VERSION ""

NS_ :

BS_:

BU_: APIM_CISM FCIMB RACM_RCIM DSP WCM DACMC HUD_ADV TRM_ITRM ACM GWM _delete APIM IPC GENERIC TSTR

BO_ 1931 TesterPhysicalResDSP: 8 DSP
 SG_ TesterPhysicalResDSP : 7|64@0+ (1,0) [0|1.84467E+019] "unitless"  TSTR

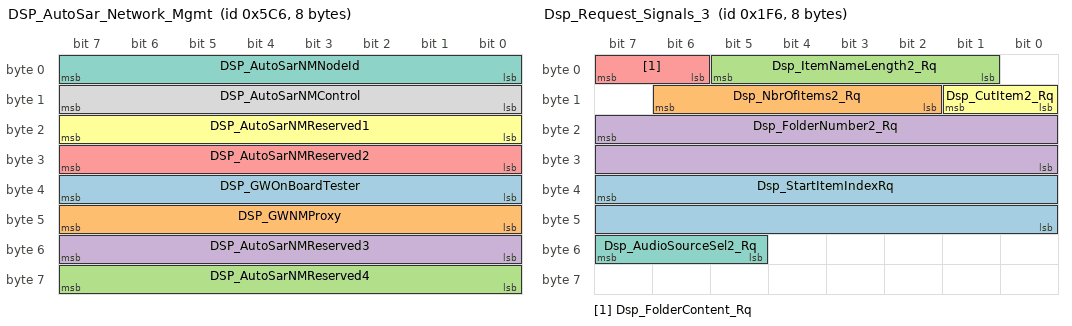
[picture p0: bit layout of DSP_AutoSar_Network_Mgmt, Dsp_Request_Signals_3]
BO_ 1478 DSP_AutoSar_Network_Mgmt: 8 DSP
 SG_ DSP_GWOnBoardTester : 39|8@0+ (1,0) [0|255] "unitless"  HUD_ADV
 SG_ DSP_GWNMProxy : 47|8@0+ (1,0) [0|255] "unitless"  HUD_ADV
 SG_ DSP_AutoSarNMReserved4 : 63|8@0+ (1,0) [0|255] "unitless"  HUD_ADV
 SG_ DSP_AutoSarNMReserved3 : 55|8@0+ (1,0) [0|255] "unitless"  HUD_ADV
 SG_ DSP_AutoSarNMReserved2 : 31|8@0+ (1,0) [0|255] "unitless"  HUD_ADV
 SG_ DSP_AutoSarNMReserved1 : 23|8@0+ (1,0) [0|255] "unitless"  HUD_ADV
 SG_ DSP_AutoSarNMNodeId : 7|8@0+ (1,0) [0|255] "unitless"  HUD_ADV
 SG_ DSP_AutoSarNMControl : 15|8@0+ (1,0) [0|255] "unitless"  HUD_ADV

BO_ 502 Dsp_Request_Signals_3: 8 APIM
 SG_ Dsp_StartItemIndexRq : 39|16@0+ (1,0) [0|65535] "unitless"  ACM
 SG_ Dsp_NbrOfItems2_Rq : 14|5@0+ (1,0) [0|20] "SED"  ACM
 SG_ Dsp_ItemNameLength2_Rq : 5|5@0+ (1,0) [0|20] "SED"  ACM
 SG_ Dsp_FolderNumber2_Rq : 23|16@0+ (1,0) [0|65535] "unitless"  ACM
 SG_ Dsp_FolderContent_Rq : 7|2@0+ (1,0) [0|3] "SED"  ACM
 SG_ Dsp_CutItem2_Rq : 9|2@0+ (1,0) [0|3] "SED"  ACM
 SG_ Dsp_AudioSourceSel2_Rq : 55|3@0+ (1,0) [0|7] "SED"  ACM

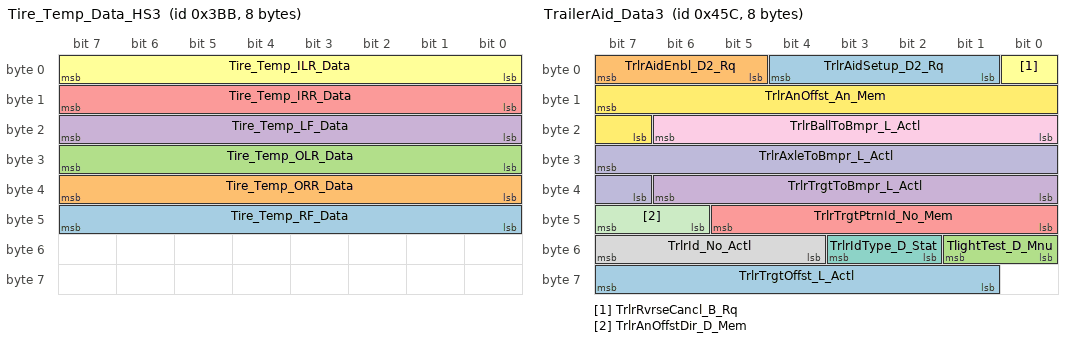
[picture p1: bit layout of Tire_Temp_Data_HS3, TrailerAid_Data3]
BO_ 955 Tire_Temp_Data_HS3: 8 GWM
 SG_ Tire_Temp_RF_Data : 47|8@0+ (1,-60) [-60|193] "degC"  IPC,APIM,APIM_CISM
 SG_ Tire_Temp_ORR_Data : 39|8@0+ (1,-60) [-60|193] "degC"  IPC,APIM,APIM_CISM
 SG_ Tire_Temp_OLR_Data : 31|8@0+ (1,-60) [-60|193] "degC"  IPC,APIM,APIM_CISM
 SG_ Tire_Temp_LF_Data : 23|8@0+ (1,-60) [-60|193] "degC"  IPC,APIM,APIM_CISM
 SG_ Tire_Temp_IRR_Data : 15|8@0+ (1,-60) [-60|193] "degC"  IPC,APIM,APIM_CISM
 SG_ Tire_Temp_ILR_Data : 7|8@0+ (1,-60) [-60|193] "degC"  IPC,APIM,APIM_CISM

BO_ 1116 TrailerAid_Data3: 8 APIM
 SG_ TrlrAidSetup_D2_Rq : 4|4@0+ (1,0) [0|15] "SED"  GWM
 SG_ TrlrAidEnbl_D2_Rq : 7|3@0+ (1,0) [0|7] "SED"  GWM
 SG_ TlightTest_D_Mnu : 49|2@0+ (1,0) [0|3] "SED"  GWM
 SG_ TrlrTrgtToBmpr_L_Actl : 38|7@0+ (0.0127,0) [0|1.6129] "meter"  GWM
 SG_ TrlrTrgtPtrnId_No_Mem : 45|6@0+ (1,0) [0|63] "unitless"  GWM
 SG_ TrlrRvrseCancl_B_Rq : 0|1@0+ (1,0) [0|1] "SED"  GWM
 SG_ TrlrIdType_D_Stat : 51|2@0+ (1,0) [0|3] "SED"  GWM
 SG_ TrlrId_No_Actl : 55|4@0+ (1,0) [0|15] "unitless"  GWM
 SG_ TrlrBallToBmpr_L_Actl : 22|7@0+ (0.0127,0) [0|1.6129] "meter"  GWM
 SG_ TrlrAxleToBmpr_L_Actl : 31|9@0+ (0.0254,0) [0|12.9794] "meter"  GWM
 SG_ TrlrAnOffstDir_D_Mem : 47|2@0+ (1,0) [0|3] "SED"  GWM
 SG_ TrlrAnOffst_An_Mem : 15|9@0+ (0.1,0) [0|51.1] "degrees"  GWM
 SG_ TrlrTrgtOffst_L_Actl : 63|7@0+ (0.0127,0) [0|1.6129] "meter"  GWM

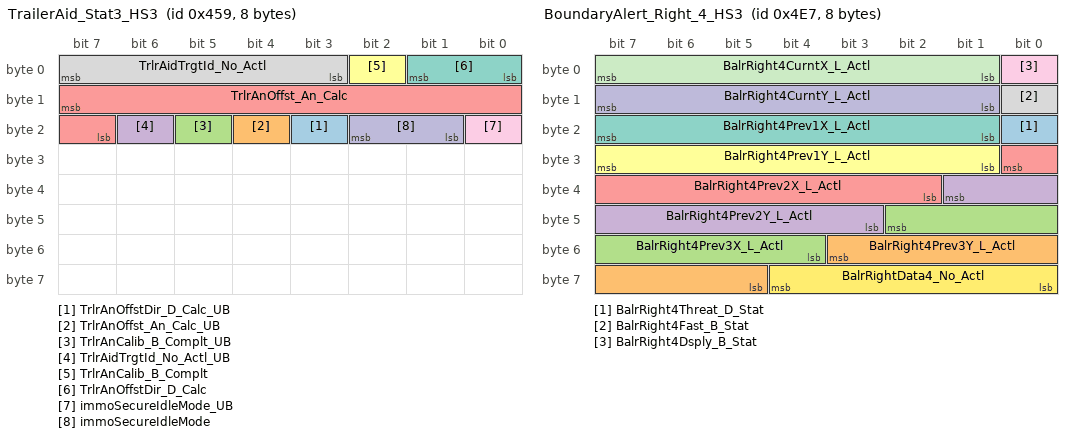
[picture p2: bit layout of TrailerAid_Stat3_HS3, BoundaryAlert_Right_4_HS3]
BO_ 1113 TrailerAid_Stat3_HS3: 8 GWM
 SG_ TrlrAnOffstDir_D_Calc_UB : 19|1@0+ (1,0) [0|1] "SED"  APIM_CISM,IPC,APIM
 SG_ TrlrAnOffst_An_Calc_UB : 20|1@0+ (1,0) [0|1] "SED"  APIM_CISM,IPC,APIM
 SG_ TrlrAnCalib_B_Complt_UB : 21|1@0+ (1,0) [0|1] "SED"  APIM_CISM,IPC,APIM
 SG_ TrlrAidTrgtId_No_Actl_UB : 22|1@0+ (1,0) [0|1] "SED"  APIM_CISM,IPC,APIM
 SG_ TrlrAnOffst_An_Calc : 15|9@0+ (0.1,0) [0|51.1] "degrees"  APIM_CISM,IPC,APIM
 SG_ TrlrAnCalib_B_Complt : 2|1@0+ (1,0) [0|1] "SED"  APIM_CISM,IPC,APIM
 SG_ TrlrAnOffstDir_D_Calc : 1|2@0+ (1,0) [0|3] "SED"  APIM_CISM,IPC,APIM
 SG_ TrlrAidTrgtId_No_Actl : 7|5@0+ (1,0) [0|31] "unitless"  APIM_CISM,IPC,APIM
 SG_ immoSecureIdleMode_UB : 16|1@0+ (1,0) [0|1] "SED"  APIM
 SG_ immoSecureIdleMode : 18|2@0+ (1,0) [0|3] "SED"  APIM

BO_ 1255 BoundaryAlert_Right_4_HS3: 8 GWM
 SG_ BalrRight4Threat_D_Stat : 16|1@0+ (1,0) [0|1] "SED"  IPC
 SG_ BalrRight4Prev3Y_L_Actl : 51|7@0+ (0.5,-32) [-32|31.5] "meter"  IPC
 SG_ BalrRight4Prev3X_L_Actl : 42|7@0+ (0.5,-32) [-32|31.5] "meter"  IPC
 SG_ BalrRight4Prev2Y_L_Actl : 33|7@0+ (0.5,-32) [-32|31.5] "meter"  IPC
 SG_ BalrRight4Prev2X_L_Actl : 24|7@0+ (0.5,-32) [-32|31.5] "meter"  IPC
 SG_ BalrRight4Prev1Y_L_Actl : 31|7@0+ (0.5,-32) [-32|31.5] "meter"  IPC
 SG_ BalrRight4Prev1X_L_Actl : 23|7@0+ (0.5,-32) [-32|31.5] "meter"  IPC
 SG_ BalrRight4Fast_B_Stat : 8|1@0+ (1,0) [0|1] "SED"  IPC
 SG_ BalrRight4Dsply_B_Stat : 0|1@0+ (1,0) [0|1] "SED"  IPC
 SG_ BalrRight4CurntY_L_Actl : 15|7@0+ (0.5,-32) [-32|31.5] "meter"  IPC
 SG_ BalrRight4CurntX_L_Actl : 7|7@0+ (0.5,-32) [-32|31.5] "meter"  IPC
 SG_ BalrRightData4_No_Actl : 60|5@0+ (1,0) [0|31] "unitless" Vector__XXX

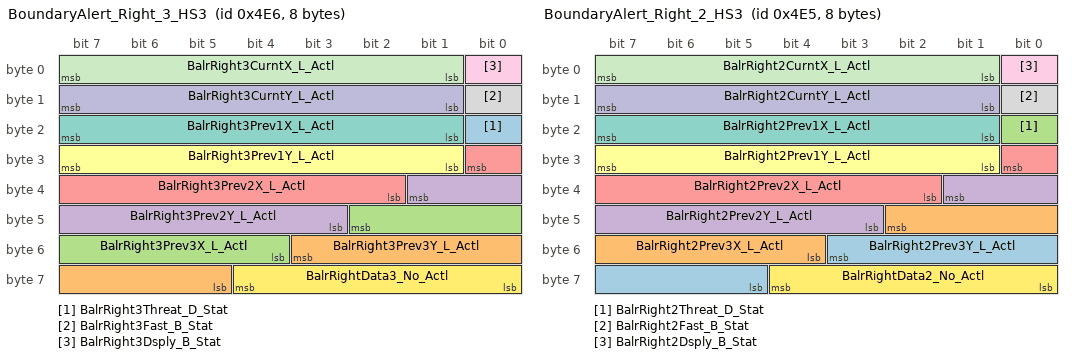
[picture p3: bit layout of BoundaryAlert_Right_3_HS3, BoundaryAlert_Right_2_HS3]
BO_ 1254 BoundaryAlert_Right_3_HS3: 8 GWM
 SG_ BalrRight3Threat_D_Stat : 16|1@0+ (1,0) [0|1] "SED"  IPC
 SG_ BalrRight3Prev3Y_L_Actl : 51|7@0+ (0.5,-32) [-32|31.5] "meter"  IPC
 SG_ BalrRight3Prev3X_L_Actl : 42|7@0+ (0.5,-32) [-32|31.5] "meter"  IPC
 SG_ BalrRight3Prev2Y_L_Actl : 33|7@0+ (0.5,-32) [-32|31.5] "meter"  IPC
 SG_ BalrRight3Prev2X_L_Actl : 24|7@0+ (0.5,-32) [-32|31.5] "meter"  IPC
 SG_ BalrRight3Prev1Y_L_Actl : 31|7@0+ (0.5,-32) [-32|31.5] "meter"  IPC
 SG_ BalrRight3Prev1X_L_Actl : 23|7@0+ (0.5,-32) [-32|31.5] "meter"  IPC
 SG_ BalrRight3Fast_B_Stat : 8|1@0+ (1,0) [0|1] "SED"  IPC
 SG_ BalrRight3Dsply_B_Stat : 0|1@0+ (1,0) [0|1] "SED"  IPC
 SG_ BalrRight3CurntY_L_Actl : 15|7@0+ (0.5,-32) [-32|31.5] "meter"  IPC
 SG_ BalrRight3CurntX_L_Actl : 7|7@0+ (0.5,-32) [-32|31.5] "meter"  IPC
 SG_ BalrRightData3_No_Actl : 60|5@0+ (1,0) [0|31] "unitless" Vector__XXX

BO_ 1253 BoundaryAlert_Right_2_HS3: 8 GWM
 SG_ BalrRight2Prev3Y_L_Actl : 51|7@0+ (0.5,-32) [-32|31.5] "meter"  IPC
 SG_ BalrRight2Prev3X_L_Actl : 42|7@0+ (0.5,-32) [-32|31.5] "meter"  IPC
 SG_ BalrRight2Threat_D_Stat : 16|1@0+ (1,0) [0|1] "SED"  IPC
 SG_ BalrRight2Prev2Y_L_Actl : 33|7@0+ (0.5,-32) [-32|31.5] "meter"  IPC
 SG_ BalrRight2Prev2X_L_Actl : 24|7@0+ (0.5,-32) [-32|31.5] "meter"  IPC
 SG_ BalrRight2Prev1Y_L_Actl : 31|7@0+ (0.5,-32) [-32|31.5] "meter"  IPC
 SG_ BalrRight2Prev1X_L_Actl : 23|7@0+ (0.5,-32) [-32|31.5] "meter"  IPC
 SG_ BalrRight2Fast_B_Stat : 8|1@0+ (1,0) [0|1] "SED"  IPC
 SG_ BalrRight2Dsply_B_Stat : 0|1@0+ (1,0) [0|1] "SED"  IPC
 SG_ BalrRight2CurntY_L_Actl : 15|7@0+ (0.5,-32) [-32|31.5] "meter"  IPC
 SG_ BalrRight2CurntX_L_Actl : 7|7@0+ (0.5,-32) [-32|31.5] "meter"  IPC
 SG_ BalrRightData2_No_Actl : 60|5@0+ (1,0) [0|31] "unitless" Vector__XXX

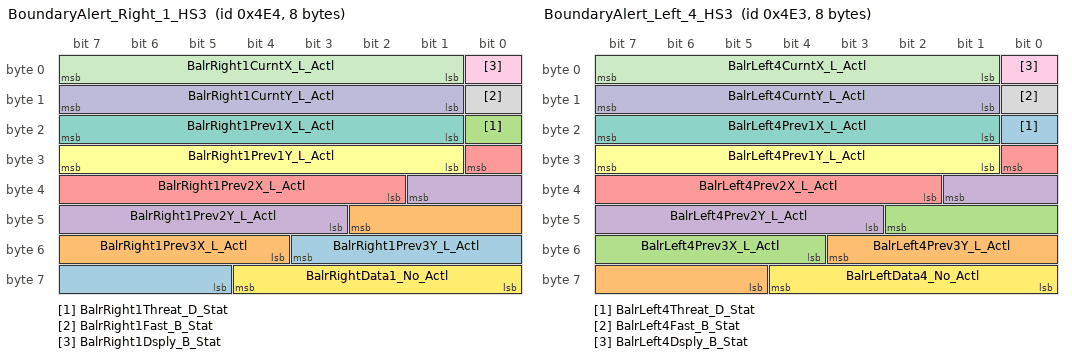
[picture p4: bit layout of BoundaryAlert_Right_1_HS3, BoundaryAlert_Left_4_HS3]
BO_ 1252 BoundaryAlert_Right_1_HS3: 8 GWM
 SG_ BalrRight1Prev3Y_L_Actl : 51|7@0+ (0.5,-32) [-32|31.5] "meter"  IPC
 SG_ BalrRight1Prev3X_L_Actl : 42|7@0+ (0.5,-32) [-32|31.5] "meter"  IPC
 SG_ BalrRight1Threat_D_Stat : 16|1@0+ (1,0) [0|1] "SED"  IPC
 SG_ BalrRight1Prev2Y_L_Actl : 33|7@0+ (0.5,-32) [-32|31.5] "meter"  IPC
 SG_ BalrRight1Prev2X_L_Actl : 24|7@0+ (0.5,-32) [-32|31.5] "meter"  IPC
 SG_ BalrRight1Prev1Y_L_Actl : 31|7@0+ (0.5,-32) [-32|31.5] "meter"  IPC
 SG_ BalrRight1Prev1X_L_Actl : 23|7@0+ (0.5,-32) [-32|31.5] "meter"  IPC
 SG_ BalrRight1Fast_B_Stat : 8|1@0+ (1,0) [0|1] "SED"  IPC
 SG_ BalrRight1Dsply_B_Stat : 0|1@0+ (1,0) [0|1] "SED"  IPC
 SG_ BalrRight1CurntY_L_Actl : 15|7@0+ (0.5,-32) [-32|31.5] "meter"  IPC
 SG_ BalrRight1CurntX_L_Actl : 7|7@0+ (0.5,-32) [-32|31.5] "meter"  IPC
 SG_ BalrRightData1_No_Actl : 60|5@0+ (1,0) [0|31] "unitless" Vector__XXX

BO_ 1251 BoundaryAlert_Left_4_HS3: 8 GWM
 SG_ BalrLeft4Threat_D_Stat : 16|1@0+ (1,0) [0|1] "SED"  IPC
 SG_ BalrLeft4Prev3Y_L_Actl : 51|7@0+ (0.5,-32) [-32|31.5] "meter"  IPC
 SG_ BalrLeft4Prev3X_L_Actl : 42|7@0+ (0.5,-32) [-32|31.5] "meter"  IPC
 SG_ BalrLeft4Prev2Y_L_Actl : 33|7@0+ (0.5,-32) [-32|31.5] "meter"  IPC
 SG_ BalrLeft4Prev2X_L_Actl : 24|7@0+ (0.5,-32) [-32|31.5] "meter"  IPC
 SG_ BalrLeft4Prev1Y_L_Actl : 31|7@0+ (0.5,-32) [-32|31.5] "meter"  IPC
 SG_ BalrLeft4Prev1X_L_Actl : 23|7@0+ (0.5,-32) [-32|31.5] "meter"  IPC
 SG_ BalrLeft4Fast_B_Stat : 8|1@0+ (1,0) [0|1] "SED"  IPC
 SG_ BalrLeft4Dsply_B_Stat : 0|1@0+ (1,0) [0|1] "SED"  IPC
 SG_ BalrLeft4CurntY_L_Actl : 15|7@0+ (0.5,-32) [-32|31.5] "meter"  IPC
 SG_ BalrLeft4CurntX_L_Actl : 7|7@0+ (0.5,-32) [-32|31.5] "meter"  IPC
 SG_ BalrLeftData4_No_Actl : 60|5@0+ (1,0) [0|31] "unitless" Vector__XXX

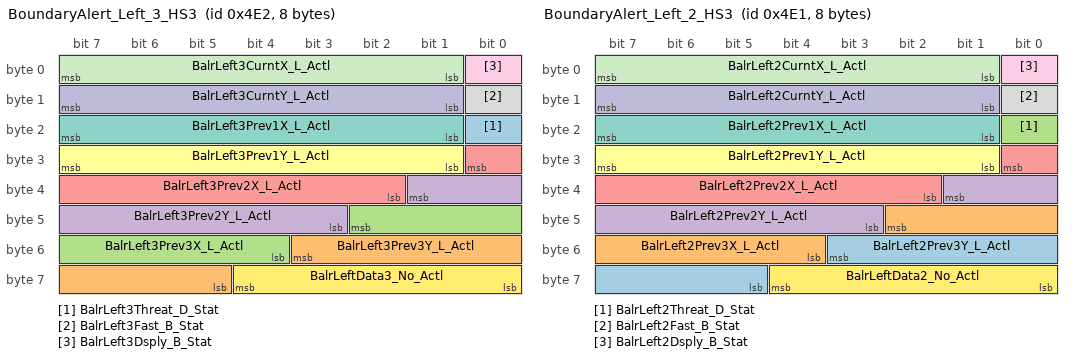
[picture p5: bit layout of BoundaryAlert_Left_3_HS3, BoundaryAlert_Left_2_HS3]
BO_ 1250 BoundaryAlert_Left_3_HS3: 8 GWM
 SG_ BalrLeft3Threat_D_Stat : 16|1@0+ (1,0) [0|1] "SED"  IPC
 SG_ BalrLeft3Prev3Y_L_Actl : 51|7@0+ (0.5,-32) [-32|31.5] "meter"  IPC
 SG_ BalrLeft3Prev3X_L_Actl : 42|7@0+ (0.5,-32) [-32|31.5] "meter"  IPC
 SG_ BalrLeft3Prev2Y_L_Actl : 33|7@0+ (0.5,-32) [-32|31.5] "meter"  IPC
 SG_ BalrLeft3Prev2X_L_Actl : 24|7@0+ (0.5,-32) [-32|31.5] "meter"  IPC
 SG_ BalrLeft3Prev1Y_L_Actl : 31|7@0+ (0.5,-32) [-32|31.5] "meter"  IPC
 SG_ BalrLeft3Prev1X_L_Actl : 23|7@0+ (0.5,-32) [-32|31.5] "meter"  IPC
 SG_ BalrLeft3Fast_B_Stat : 8|1@0+ (1,0) [0|1] "SED"  IPC
 SG_ BalrLeft3Dsply_B_Stat : 0|1@0+ (1,0) [0|1] "SED"  IPC
 SG_ BalrLeft3CurntY_L_Actl : 15|7@0+ (0.5,-32) [-32|31.5] "meter"  IPC
 SG_ BalrLeft3CurntX_L_Actl : 7|7@0+ (0.5,-32) [-32|31.5] "meter"  IPC
 SG_ BalrLeftData3_No_Actl : 60|5@0+ (1,0) [0|31] "unitless" Vector__XXX

BO_ 1249 BoundaryAlert_Left_2_HS3: 8 GWM
 SG_ BalrLeft2Prev3Y_L_Actl : 51|7@0+ (0.5,-32) [-32|31.5] "meter"  IPC
 SG_ BalrLeft2Prev3X_L_Actl : 42|7@0+ (0.5,-32) [-32|31.5] "meter"  IPC
 SG_ BalrLeft2Threat_D_Stat : 16|1@0+ (1,0) [0|1] "SED"  IPC
 SG_ BalrLeft2Prev2Y_L_Actl : 33|7@0+ (0.5,-32) [-32|31.5] "meter"  IPC
 SG_ BalrLeft2Prev2X_L_Actl : 24|7@0+ (0.5,-32) [-32|31.5] "meter"  IPC
 SG_ BalrLeft2Prev1Y_L_Actl : 31|7@0+ (0.5,-32) [-32|31.5] "meter"  IPC
 SG_ BalrLeft2Prev1X_L_Actl : 23|7@0+ (0.5,-32) [-32|31.5] "meter"  IPC
 SG_ BalrLeft2Fast_B_Stat : 8|1@0+ (1,0) [0|1] "SED"  IPC
 SG_ BalrLeft2Dsply_B_Stat : 0|1@0+ (1,0) [0|1] "SED"  IPC
 SG_ BalrLeft2CurntY_L_Actl : 15|7@0+ (0.5,-32) [-32|31.5] "meter"  IPC
 SG_ BalrLeft2CurntX_L_Actl : 7|7@0+ (0.5,-32) [-32|31.5] "meter"  IPC
 SG_ BalrLeftData2_No_Actl : 60|5@0+ (1,0) [0|31] "unitless" Vector__XXX

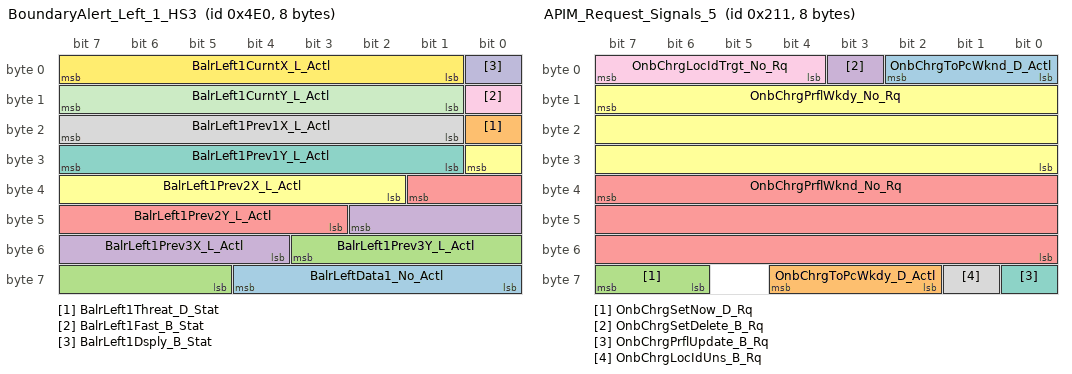
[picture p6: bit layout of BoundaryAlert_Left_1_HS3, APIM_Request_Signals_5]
BO_ 1248 BoundaryAlert_Left_1_HS3: 8 GWM
 SG_ BalrLeftData1_No_Actl : 60|5@0+ (1,0) [0|31] "unitless" Vector__XXX
 SG_ BalrLeft1Threat_D_Stat : 16|1@0+ (1,0) [0|1] "SED"  IPC
 SG_ BalrLeft1Prev3Y_L_Actl : 51|7@0+ (0.5,-32) [-32|31.5] "meter"  IPC
 SG_ BalrLeft1Prev3X_L_Actl : 42|7@0+ (0.5,-32) [-32|31.5] "meter"  IPC
 SG_ BalrLeft1Prev2Y_L_Actl : 33|7@0+ (0.5,-32) [-32|31.5] "meter"  IPC
 SG_ BalrLeft1Prev2X_L_Actl : 24|7@0+ (0.5,-32) [-32|31.5] "meter"  IPC
 SG_ BalrLeft1Prev1Y_L_Actl : 31|7@0+ (0.5,-32) [-32|31.5] "meter"  IPC
 SG_ BalrLeft1Prev1X_L_Actl : 23|7@0+ (0.5,-32) [-32|31.5] "meter"  IPC
 SG_ BalrLeft1Fast_B_Stat : 8|1@0+ (1,0) [0|1] "SED"  IPC
 SG_ BalrLeft1Dsply_B_Stat : 0|1@0+ (1,0) [0|1] "SED"  IPC
 SG_ BalrLeft1CurntY_L_Actl : 15|7@0+ (0.5,-32) [-32|31.5] "meter"  IPC
 SG_ BalrLeft1CurntX_L_Actl : 7|7@0+ (0.5,-32) [-32|31.5] "meter"  IPC

BO_ 1256 GWM_Send_Signals_15_HS3: 8 GWM
 SG_ BalrMdeRight_D_Stat_UB : 21|1@0+ (1,0) [0|1] "SED"  IPC
 SG_ BalrMdeSelRight_B_Stat_UB : 17|1@0+ (1,0) [0|1] "SED"  IPC
 SG_ BalrRight_D_Stat_UB : 16|1@0+ (1,0) [0|1] "SED"  IPC
 SG_ BalrLckRight_B_Stat_UB : 14|1@0+ (1,0) [0|1] "SED"  IPC
 SG_ BalrChimeRight_D_Rq_UB : 2|1@0+ (1,0) [0|1] "SED"  IPC
 SG_ BalrSnsRight_D_Falt_UB : 24|1@0+ (1,0) [0|1] "SED"  IPC
 SG_ BalrWndwRight_B_Stat_UB : 36|1@0+ (1,0) [0|1] "SED"  IPC
 SG_ BalrLckRight_B_Stat : 15|1@0+ (1,0) [0|1] "SED"  IPC
 SG_ BalrWndwRight_B_Stat : 37|1@0+ (1,0) [0|1] "SED"  IPC
 SG_ BalrMdeSelRight_B_Stat : 18|1@0+ (1,0) [0|1] "SED"  IPC
 SG_ BalrSnsRight_D_Falt : 26|2@0+ (1,0) [0|3] "SED"  IPC
 SG_ BalrChimeRight_D_Rq : 4|2@0+ (1,0) [0|3] "SED"  IPC
 SG_ BalrMdeRight_D_Stat : 23|2@0+ (1,0) [0|3] "SED"  IPC
 SG_ BalrRight_D_Stat : 31|2@0+ (1,0) [0|3] "SED"  IPC
 SG_ BalrWndwLeft_B_Stat_UB : 38|1@0+ (1,0) [0|1] "SED"  IPC
 SG_ BalrSnsLeft_D_Falt_UB : 27|1@0+ (1,0) [0|1] "SED"  IPC
 SG_ BalrMdeSelLeft_B_Stat_UB : 19|1@0+ (1,0) [0|1] "SED"  IPC
 SG_ BalrMdeLeft_D_Stat_UB : 8|1@0+ (1,0) [0|1] "SED"  IPC
 SG_ BalrLeft_D_Stat_UB : 11|1@0+ (1,0) [0|1] "SED"  IPC
 SG_ BalrLckLeft_B_Stat_UB : 0|1@0+ (1,0) [0|1] "SED"  IPC
 SG_ BalrChimeLeft_D_Rq_UB : 5|1@0+ (1,0) [0|1] "SED"  IPC
 SG_ BalrLeft_D_Stat : 13|2@0+ (1,0) [0|3] "SED"  IPC
 SG_ BalrMdeSelLeft_B_Stat : 20|1@0+ (1,0) [0|1] "SED"  IPC
 SG_ BalrLckLeft_B_Stat : 1|1@0+ (1,0) [0|1] "SED"  IPC
 SG_ BalrWndwLeft_B_Stat : 39|1@0+ (1,0) [0|1] "SED"  IPC
 SG_ BalrMdeLeft_D_Stat : 10|2@0+ (1,0) [0|3] "SED"  IPC
 SG_ BalrSnsLeft_D_Falt : 29|2@0+ (1,0) [0|3] "SED"  IPC
 SG_ BalrChimeLeft_D_Rq : 7|2@0+ (1,0) [0|3] "SED"  IPC
 SG_ WakeAlarm2_D_Stat_UB : 33|1@0+ (1,0) [0|1] "SED"  TRM_ITRM
 SG_ WakeAlarm2_D_Stat : 35|2@0+ (1,0) [0|3] "SED"  TRM_ITRM

BO_ 529 APIM_Request_Signals_5: 8 APIM
 SG_ OnbChrgToPcWknd_D_Actl : 2|3@0+ (1,0) [0|7] "percent"  GWM
 SG_ OnbChrgToPcWkdy_D_Actl : 60|3@0+ (1,0) [0|7] "percent"  GWM
 SG_ OnbChrgSetNow_D_Rq : 63|2@0+ (1,0) [0|3] "SED"  GWM
 SG_ OnbChrgSetDelete_B_Rq : 3|1@0+ (1,0) [0|1] "SED"  GWM
 SG_ OnbChrgPrflWknd_No_Rq : 39|24@0+ (1,0) [0|16777215] "unitless"  GWM
 SG_ OnbChrgPrflWkdy_No_Rq : 15|24@0+ (1,0) [0|16777215] "unitless"  GWM
 SG_ OnbChrgPrflUpdate_B_Rq : 56|1@0+ (1,0) [0|1] "SED"  GWM
 SG_ OnbChrgLocIdUns_B_Rq : 57|1@0+ (1,0) [0|1] "SED"  GWM
 SG_ OnbChrgLocIdTrgt_No_Rq : 7|4@0+ (1,0) [0|15] "Unitless"  GWM

BO_ 642 GWM_Send_Signals_14_HS3: 8 GWM
 SG_ SldrrMsgTxt_D2_Rq_UB : 8|1@0+ (1,0) [0|1] "SED"  IPC
 SG_ SldrrMsgTxt_D2_Rq : 11|3@0+ (1,0) [0|7] "SED"  IPC
 SG_ SldrrChime_D_Rq_UB : 12|1@0+ (1,0) [0|1] "SED"  IPC
 SG_ SldrrChime_D_Rq : 15|3@0+ (1,0) [0|7] "SED"  IPC
 SG_ SldrlMsgTxt_D2_Rq_UB : 0|1@0+ (1,0) [0|1] "SED"  IPC
 SG_ SldrlMsgTxt_D2_Rq : 3|3@0+ (1,0) [0|7] "SED"  IPC
 SG_ SldrlChime_D_Rq_UB : 4|1@0+ (1,0) [0|1] "SED"  IPC
 SG_ SldrlChime_D_Rq : 7|3@0+ (1,0) [0|7] "SED"  IPC
 SG_ PaakMyKeySearch_D_Stat_UB : 27|1@0+ (1,0) [0|1] "SED"  APIM_CISM,APIM
 SG_ UreaLvlQlty_D_RqDsply_UB : 48|1@0+ (1,0) [0|1] "SED"  IPC
 SG_ DieslPrtcWarn_D_Rq_UB : 24|1@0+ (1,0) [0|1] "SED"  IPC
 SG_ UreaQltySysWarn_D_Rq_UB : 25|1@0+ (1,0) [0|1] "SED"  IPC
 SG_ UreaLvlTxtWarn_D_Rq_UB : 26|1@0+ (1,0) [0|1] "SED"  IPC
 SG_ UreaLvlQlty_D_RqDsply : 59|3@0+ (1,0) [0|7] "SED"  IPC
 SG_ UreaLvlTxtWarn_D_Rq : 63|4@0+ (1,0) [0|15] "SED"  IPC
 SG_ UreaQltySysWarn_D_Rq : 51|3@0+ (1,0) [0|7] "SED"  IPC
 SG_ DieslPrtcWarn_D_Rq : 55|4@0+ (1,0) [0|15] "SED"  IPC
 SG_ KeyMyKeyTot_No2_Cnt_UB : 40|1@0+ (1,0) [0|1] "SED"  APIM_CISM,APIM
 SG_ KeyAdmnTot_No2_Cnt_UB : 32|1@0+ (1,0) [0|1] "SED"  APIM_CISM,APIM
 SG_ KeyMyKeyTot_No2_Cnt : 47|7@0+ (1,0) [0|127] "unitless"  APIM_CISM,APIM
 SG_ KeyAdmnTot_No2_Cnt : 39|7@0+ (1,0) [0|127] "unitless"  APIM_CISM,APIM
 SG_ DcChrgSrvcRqd_B_Rq_UB : 31|1@0+ (1,0) [0|1] "SED"  IPC
 SG_ DcChrgSrvcRqd_B_Rq : 16|1@0+ (1,0) [0|1] "SED"  IPC
 SG_ PaakMyKeySearch_D_Stat : 30|3@0+ (1,0) [0|7] "SED"  APIM_CISM,APIM
 SG_ GrdAsstActv_B_Stat_UB : 17|1@0+ (1,0) [0|1] "SED"  IPC
 SG_ GrdAsstActv_B_Stat : 18|1@0+ (1,0) [0|1] "SED"  IPC
 SG_ TrlrAidTrlrId_No_Rq_UB : 19|1@0+ (1,0) [0|1] "SED"  APIM_CISM,IPC,APIM
 SG_ TrlrAidTrlrId_No_Rq : 23|4@0+ (1,0) [0|15] "unitless"  APIM_CISM,IPC,APIM

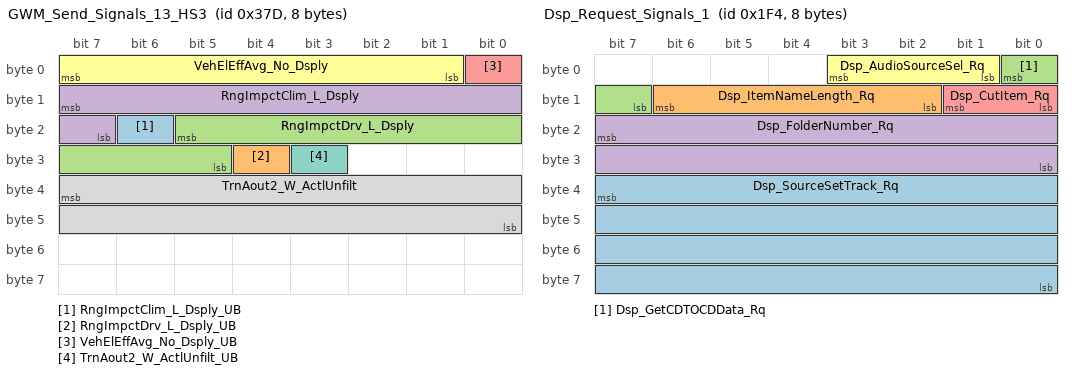
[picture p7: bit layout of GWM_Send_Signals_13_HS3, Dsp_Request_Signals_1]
BO_ 893 GWM_Send_Signals_13_HS3: 8 GWM
 SG_ RngImpctClim_L_Dsply_UB : 22|1@0+ (1,0) [0|1] "SED"  IPC
 SG_ RngImpctDrv_L_Dsply_UB : 28|1@0+ (1,0) [0|1] "SED"  IPC
 SG_ RngImpctDrv_L_Dsply : 21|9@0+ (1,-255) [-255|256] "km"  IPC
 SG_ RngImpctClim_L_Dsply : 15|9@0+ (1,-255) [-255|256] "km"  IPC
 SG_ VehElEffAvg_No_Dsply_UB : 0|1@0+ (1,0) [0|1] "SED"  IPC,APIM
 SG_ VehElEffAvg_No_Dsply : 7|7@0+ (10,-100) [-100|1150] "wattHr/km"  IPC,APIM
 SG_ TrnAout2_W_ActlUnfilt_UB : 27|1@0+ (1,0) [0|1] "SED"  ACM
 SG_ TrnAout2_W_ActlUnfilt : 39|16@0+ (0.1,-3276.5) [-3276.5|3276.8] "rad/s"  ACM

BO_ 500 Dsp_Request_Signals_1: 8 APIM
 SG_ Dsp_SourceSetTrack_Rq : 39|32@0+ (1,0) [0|4294967295] "unitless"  ACM
 SG_ Dsp_ItemNameLength_Rq : 14|5@0+ (1,0) [0|20] "SED"  ACM
 SG_ Dsp_GetCDTOCDData_Rq : 0|2@0+ (1,0) [0|3] "SED"  ACM
 SG_ Dsp_FolderNumber_Rq : 23|16@0+ (1,0) [0|65535] "unitless"  ACM
 SG_ Dsp_CutItem_Rq : 9|2@0+ (1,0) [0|3] "SED"  ACM
 SG_ Dsp_AudioSourceSel_Rq : 3|3@0+ (1,0) [0|7] "SED"  ACM

BO_ 503 Dsp_Request_Signals_4: 8 APIM
 SG_ Dsp_PlayFrstTrInFldr_Rq : 39|16@0+ (1,0) [0|65535] "unitless"  ACM
 SG_ Dsp_ItemIndex_Rq : 23|16@0+ (1,0) [0|65535] "unitless"  ACM
 SG_ Dsp_FolderNumber3_Rq : 7|16@0+ (1,0) [0|65535] "unitless"  ACM
 SG_ Dsp_AudioSourceSel3_Rq : 55|3@0+ (1,0) [0|7] "SED"  ACM

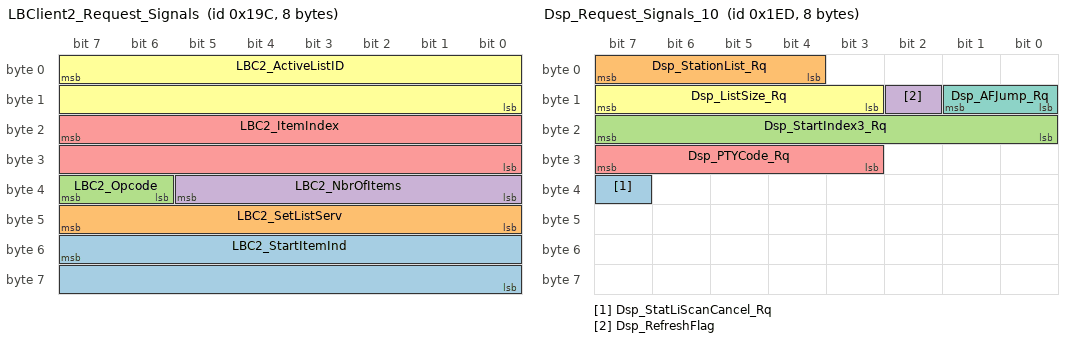
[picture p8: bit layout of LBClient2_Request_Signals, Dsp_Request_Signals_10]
BO_ 412 LBClient2_Request_Signals: 8 APIM
 SG_ LBC2_StartItemInd : 55|16@0+ (1,0) [0|65535] "unitless"  ACM
 SG_ LBC2_SetListServ : 47|8@0+ (1,0) [0|255] "unitless"  ACM
 SG_ LBC2_Opcode : 39|2@0+ (1,0) [0|3] "SED"  ACM
 SG_ LBC2_NbrOfItems : 37|6@0+ (1,0) [0|63] "unitless"  ACM
 SG_ LBC2_ItemIndex : 23|16@0+ (1,0) [0|65535] "unitless"  ACM
 SG_ LBC2_ActiveListID : 7|16@0+ (1,0) [0|65535] "unitless"  ACM

BO_ 493 Dsp_Request_Signals_10: 8 APIM
 SG_ Dsp_StatLiScanCancel_Rq : 39|1@0+ (1,0) [0|1] "SED"  ACM
 SG_ Dsp_StationList_Rq : 7|4@0+ (1,0) [0|15] "SED"  ACM
 SG_ Dsp_StartIndex3_Rq : 23|8@0+ (1,0) [0|255] "unitless"  ACM
 SG_ Dsp_RefreshFlag : 10|1@0+ (1,0) [0|1] "SED"  ACM
 SG_ Dsp_PTYCode_Rq : 31|5@0+ (1,0) [0|31] "SED"  ACM
 SG_ Dsp_ListSize_Rq : 15|5@0+ (1,0) [0|31] "SED"  ACM
 SG_ Dsp_AFJump_Rq : 9|2@0+ (1,0) [0|3] "SED"  ACM

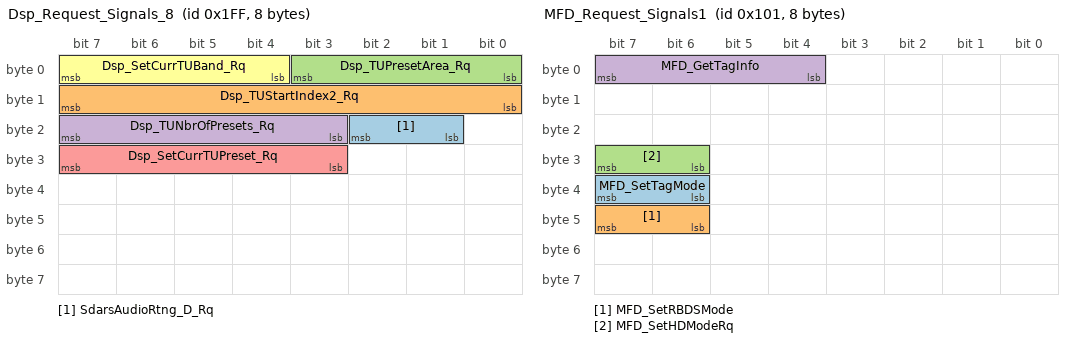
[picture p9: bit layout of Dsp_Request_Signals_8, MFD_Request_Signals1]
BO_ 511 Dsp_Request_Signals_8: 8 APIM
 SG_ SdarsAudioRtng_D_Rq : 18|2@0+ (1,0) [0|3] "SED"  ACM
 SG_ Dsp_TUStartIndex2_Rq : 15|8@0+ (1,0) [0|255] "unitless"  ACM
 SG_ Dsp_TUPresetArea_Rq : 3|4@0+ (1,0) [0|15] "SED"  ACM
 SG_ Dsp_TUNbrOfPresets_Rq : 23|5@0+ (1,0) [0|30] "SED"  ACM
 SG_ Dsp_SetCurrTUPreset_Rq : 31|5@0+ (1,0) [0|31] "SED"  ACM
 SG_ Dsp_SetCurrTUBand_Rq : 7|4@0+ (1,0) [0|15] "SED"  ACM

BO_ 257 MFD_Request_Signals1: 8 APIM
 SG_ MFD_SetTagMode : 39|2@0+ (1,0) [0|3] "SED"  ACM
 SG_ MFD_SetRBDSMode : 47|2@0+ (1,0) [0|3] "SED"  ACM
 SG_ MFD_SetHDModeRq : 31|2@0+ (1,0) [0|3] "SED"  ACM
 SG_ MFD_GetTagInfo : 7|4@0+ (1,0) [0|15] "day"  ACM

BO_ 713 SDARS_RDISP_WORD_Rx: 8 APIM
 SG_ SDARS_RDISP_WORD_Rx : 7|64@0+ (1,0) [0|1.84467440737096E+019] "unitless"  ACM

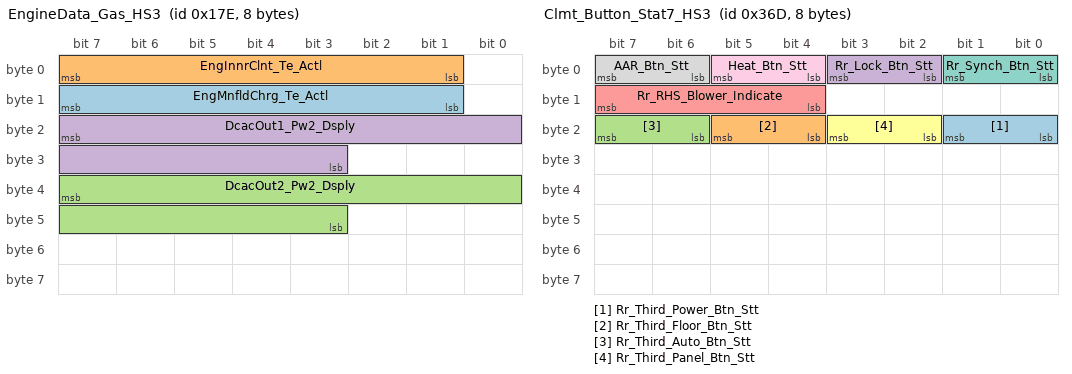
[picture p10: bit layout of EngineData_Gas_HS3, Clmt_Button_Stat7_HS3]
BO_ 382 EngineData_Gas_HS3: 8 GWM
 SG_ EngMnfldChrg_Te_Actl : 15|7@0+ (1,-20) [-20|105] "degC"  IPC
 SG_ EngInnrClnt_Te_Actl : 7|7@0+ (1,50) [50|175] "degC"  IPC
 SG_ DcacOut2_Pw2_Dsply : 39|13@0+ (1,0) [0|8189] "watts"  APIM
 SG_ DcacOut1_Pw2_Dsply : 23|13@0+ (1,0) [0|8189] "watts"  APIM

BO_ 877 Clmt_Button_Stat7_HS3: 8 GWM
 SG_ Rr_Third_Power_Btn_Stt : 17|2@0+ (1,0) [0|3] "SED"  APIM_CISM,APIM,RACM_RCIM
 SG_ Rr_Third_Floor_Btn_Stt : 21|2@0+ (1,0) [0|3] "SED"  APIM_CISM,APIM,RACM_RCIM
 SG_ Rr_Third_Auto_Btn_Stt : 23|2@0+ (1,0) [0|3] "SED"  APIM_CISM,APIM,RACM_RCIM
 SG_ Rr_Lock_Btn_Stt : 3|2@0+ (1,0) [0|3] "SED"  APIM_CISM,RACM_RCIM,APIM
 SG_ Rr_RHS_Blower_Indicate : 15|4@0+ (1,0) [0|15] "SED"  APIM_CISM,RACM_RCIM,APIM
 SG_ Rr_Third_Panel_Btn_Stt : 19|2@0+ (1,0) [0|3] "SED"  APIM_CISM,APIM,RACM_RCIM
 SG_ Rr_Synch_Btn_Stt : 1|2@0+ (1,0) [0|3] "SED"  APIM_CISM,APIM
 SG_ AAR_Btn_Stt : 7|2@0+ (1,0) [0|3] "SED"  APIM_CISM,FCIMB,APIM
 SG_ Heat_Btn_Stt : 5|2@0+ (1,0) [0|3] "SED"  APIM_CISM,FCIMB,APIM

BO_ 592 RFA_BLEM_APIM_Tx_HS3: 8 GWM
 SG_ RFA_BLEM_APIM_Tx : 7|64@0+ (1,0) [0|1.84467440737096E+019] "unitless"  APIM_CISM,APIM

BO_ 600 APIM_RFA_BLEM_Tx: 8 APIM
 SG_ APIM_RFA_BLEM_Tx : 7|64@0+ (1,0) [0|1.84467440737096E+019] "unitless"  GWM

BO_ 708 TMCSrvr_TMCClnt_WORD_Tx: 8 ACM
 SG_ TMCSrvr_TMCClnt_WORD_Tx : 7|64@0+ (1,0) [0|1.84467440737096E+019] "unitless"  APIM

BO_ 414 LBS2_Indication_Signals: 8 ACM
 SG_ LBS2_ListStatus : 57|2@0+ (1,0) [0|3] "SED"  APIM,IPC
 SG_ LBS2_ParentID : 31|16@0+ (1,0) [0|65535] "unitless"  APIM,IPC
 SG_ LBS2_ListServer : 7|8@0+ (1,0) [0|255] "unitless"  APIM,IPC
 SG_ LBS2_ListID : 15|16@0+ (1,0) [0|65535] "unitless"  APIM,IPC
 SG_ LBS2_EntryIndex : 47|16@0+ (1,0) [0|65535] "unitless"  APIM,IPC

BO_ 716 TMCSrvr_TMCClient_WORD_Rx: 8 APIM
 SG_ TMCSrvr_TMCClnt_WORD_Rx : 7|64@0+ (1,0) [0|1.84467440737096E+019] "unitless"  ACM

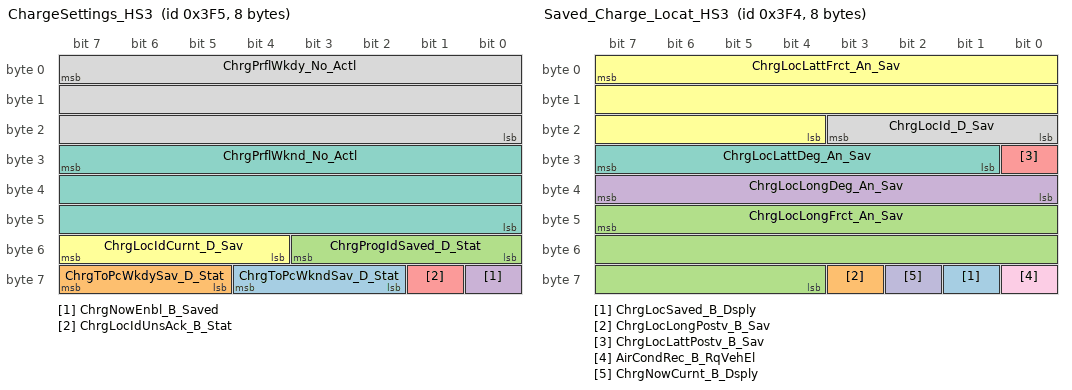
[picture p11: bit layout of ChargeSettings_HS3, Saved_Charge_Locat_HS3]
BO_ 1013 ChargeSettings_HS3: 8 GWM
 SG_ ChrgToPcWkndSav_D_Stat : 60|3@0+ (1,0) [0|7] "SED"  APIM_CISM,APIM
 SG_ ChrgToPcWkdySav_D_Stat : 63|3@0+ (1,0) [0|7] "SED"  APIM_CISM,APIM
 SG_ ChrgProgIdSaved_D_Stat : 51|4@0+ (1,0) [0|15] "Unitless"  APIM_CISM,APIM
 SG_ ChrgNowEnbl_B_Saved : 56|1@0+ (1,0) [0|1] "SED"  APIM_CISM,APIM
 SG_ ChrgLocIdUnsAck_B_Stat : 57|1@0+ (1,0) [0|1] "SED"  APIM_CISM,APIM
 SG_ ChrgLocIdCurnt_D_Sav : 55|4@0+ (1,0) [0|15] "unitless"  APIM_CISM,IPC,APIM
 SG_ ChrgPrflWknd_No_Actl : 31|24@0+ (1,0) [0|16777215] "unitless"  APIM_CISM,APIM
 SG_ ChrgPrflWkdy_No_Actl : 7|24@0+ (1,0) [0|16777215] "unitless"  APIM_CISM,APIM

BO_ 641 GWM_Send_Signals_10_HS3: 8 GWM
 SG_ ChrgGoTElement_B_Dsply_UB : 57|1@0+ (1,0) [0|1] "SED"  APIM,APIM_CISM
 SG_ ChrgGoTElement_B_Dsply : 58|1@0+ (1,0) [0|1] "SED"  APIM,APIM_CISM
 SG_ BattChrgTrgtSoC_D_Rq : 46|3@0+ (1,0) [0|7] "Percent"  APIM_CISM,IPC
 SG_ BattChrgTrgtSoC_D_Rq_UB : 43|1@0+ (1,0) [0|1] "SED"  APIM_CISM,IPC
 SG_ ChrgLocIdCurnt_D_Uns_UB : 59|1@0+ (1,0) [0|1] "SED"  APIM_CISM,APIM
 SG_ ChrgLocIdCurnt_D_Uns : 63|4@0+ (1,0) [0|15] "unitless"  APIM_CISM,APIM
 SG_ IgnPsswrdActv_B_Stat_UB : 54|1@0+ (1,0) [0|1] "SED"  APIM_CISM,APIM
 SG_ IgnPsswrdSetup_B_Rq_UB : 50|1@0+ (1,0) [0|1] "SED"  APIM_CISM,APIM
 SG_ IgnPsswrdLckout_B_Stat_UB : 51|1@0+ (1,0) [0|1] "SED"  APIM_CISM,APIM
 SG_ IgnPsswrdSetup_B_Rq : 52|1@0+ (1,0) [0|1] "SED"  APIM_CISM,APIM
 SG_ IgnPsswrdLckout_B_Stat : 53|1@0+ (1,0) [0|1] "SED"  APIM_CISM,APIM
 SG_ PaakCnnct_D_Stat_UB : 40|1@0+ (1,0) [0|1] "SED"  APIM_CISM,APIM
 SG_ PaakCnnct_D_Stat : 42|2@0+ (1,0) [0|3] "SED"  APIM_CISM,APIM
 SG_ IgnPsswrdActv_B_Stat : 55|1@0+ (1,0) [0|1] "SED"  APIM_CISM,APIM
 SG_ ChrgGoTTouch_B_Stat_UB : 47|1@0+ (1,0) [0|1] "SED"  APIM_CISM,APIM
 SG_ ChrgGoTTouch_B_Stat : 24|1@0+ (1,0) [0|1] "SED"  APIM_CISM,APIM
 SG_ ChrgGoTPrcond_D_Stat_UB : 16|1@0+ (1,0) [0|1] "SED"  APIM_CISM,APIM
 SG_ ChrgGoTPrcond_D_Stat : 26|2@0+ (1,0) [0|3] "SED"  APIM_CISM,APIM
 SG_ ChrgGoTNext_D_Stat_UB : 17|1@0+ (1,0) [0|1] "SED"  APIM_CISM,APIM
 SG_ ChrgGoTNext_D_Stat : 35|4@0+ (1,0) [0|15] "Unitless"  APIM_CISM,APIM
 SG_ ChrgGoTMnte_D_Stat_UB : 18|1@0+ (1,0) [0|1] "SED"  APIM_CISM,APIM
 SG_ ChrgGoTMnte_D_Stat : 39|4@0+ (1,0) [0|15] "SED"  APIM_CISM,APIM
 SG_ ChrgGoTHr_T_Stat_UB : 19|1@0+ (1,0) [0|1] "SED"  APIM_CISM,APIM
 SG_ ChrgGoTHr_T_Stat : 31|5@0+ (1,0) [0|29] "hour"  APIM_CISM,APIM
 SG_ ChrgGoTExtHtr_B_Stat_UB : 8|1@0+ (1,0) [0|1] "SED"  APIM_CISM,APIM
 SG_ ChrgGoTExtHtr_B_Stat : 9|1@0+ (1,0) [0|1] "SED"  APIM_CISM,APIM
 SG_ ChrgGoTElement_D_Stat_UB : 10|1@0+ (1,0) [0|1] "SED"  APIM_CISM,APIM
 SG_ ChrgGoTElement_D_Stat : 23|4@0+ (1,0) [0|15] "Unitless"  APIM_CISM,APIM
 SG_ ChrgGoTAllOn_B_Stat_UB : 11|1@0+ (1,0) [0|1] "SED"  APIM_CISM,APIM
 SG_ ChrgGoTAllOn_B_Stat : 12|1@0+ (1,0) [0|1] "SED"  APIM_CISM,APIM
 SG_ TrlrAidMsgTxt_D2_Rq : 7|6@0+ (1,0) [0|63] "SED"  APIM_CISM,IPC,TRM_ITRM,APIM
 SG_ TrlrAidEnbl_D2_Stat : 15|3@0+ (1,0) [0|7] "SED"  APIM_CISM,IPC,TRM_ITRM,APIM
 SG_ TrlrAidMsgTxt_D2_Rq_UB : 1|1@0+ (1,0) [0|1] "SED"  APIM_CISM,IPC,TRM_ITRM,APIM
 SG_ TrlrAidEnbl_D2_Stat_UB : 0|1@0+ (1,0) [0|1] "SED"  APIM_CISM,IPC,TRM_ITRM,APIM

BO_ 1012 Saved_Charge_Locat_HS3: 8 GWM
 SG_ ChrgLocSaved_B_Dsply : 57|1@0+ (1,0) [0|1] "SED"  APIM,APIM_CISM
 SG_ ChrgLocLongPostv_B_Sav : 59|1@0+ (1,0) [0|1] "SED"  APIM_CISM,APIM
 SG_ ChrgLocLongFrct_An_Sav : 47|20@0+ (1E-006,0) [0|1.048575] "degrees"  APIM_CISM,APIM
 SG_ ChrgLocLongDeg_An_Sav : 39|8@0+ (1,0) [0|255] "degrees"  APIM_CISM,APIM
 SG_ ChrgLocLattPostv_B_Sav : 24|1@0+ (1,0) [0|1] "SED"  APIM_CISM,APIM
 SG_ ChrgLocLattFrct_An_Sav : 7|20@0+ (1E-006,0) [0|1.048575] "degrees"  APIM_CISM,APIM
 SG_ ChrgLocLattDeg_An_Sav : 31|7@0+ (1,0) [0|127] "unitless"  APIM_CISM,APIM
 SG_ ChrgLocId_D_Sav : 19|4@0+ (1,0) [0|15] "unitless"  APIM_CISM,APIM
 SG_ AirCondRec_B_RqVehEl : 56|1@0+ (1,0) [0|1] "SED"  GENERIC
 SG_ ChrgNowCurnt_B_Dsply : 58|1@0+ (1,0) [0|1] "SED"  IPC,APIM_CISM,APIM

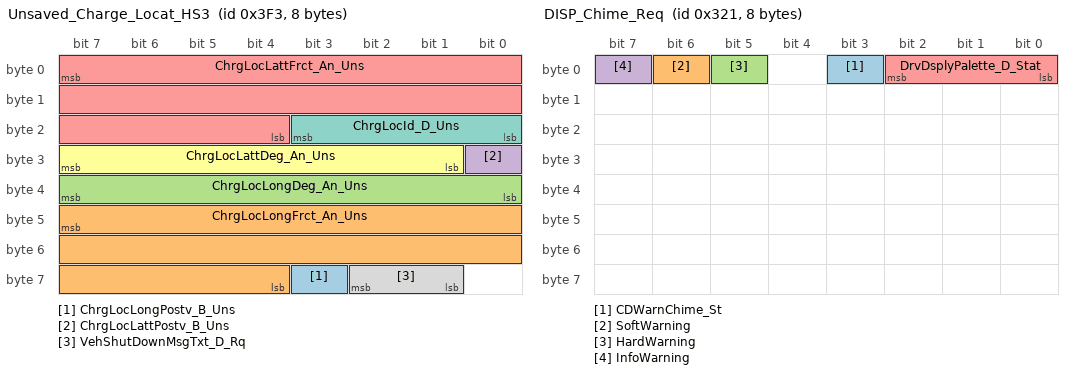
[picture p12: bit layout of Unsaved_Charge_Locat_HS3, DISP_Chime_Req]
BO_ 1011 Unsaved_Charge_Locat_HS3: 8 GWM
 SG_ ChrgLocLongPostv_B_Uns : 59|1@0+ (1,0) [0|1] "SED"  APIM_CISM,APIM
 SG_ ChrgLocLongFrct_An_Uns : 47|20@0+ (1E-006,0) [0|1.048575] "degrees"  APIM_CISM,APIM
 SG_ ChrgLocLongDeg_An_Uns : 39|8@0+ (1,0) [0|255] "degrees"  APIM_CISM,APIM
 SG_ ChrgLocLattPostv_B_Uns : 24|1@0+ (1,0) [0|1] "SED"  APIM_CISM,APIM
 SG_ ChrgLocLattFrct_An_Uns : 7|20@0+ (1E-006,0) [0|1.048575] "degrees"  APIM_CISM,APIM
 SG_ ChrgLocLattDeg_An_Uns : 31|7@0+ (1,0) [0|127] "unitless"  APIM_CISM,APIM
 SG_ ChrgLocId_D_Uns : 19|4@0+ (1,0) [0|15] "unitless"  APIM_CISM,APIM
 SG_ VehShutDownMsgTxt_D_Rq : 58|2@0+ (1,0) [0|3] "SED"  IPC

BO_ 533 APIM_Send_Signals_2: 8 APIM
 SG_ AutoEpbZoomView_B_Stat : 32|1@0+ (1,0) [0|1] "SED"  GWM
 SG_ PaakMyKey_D_Rq : 7|2@0+ (1,0) [0|3] "SED"  GWM
 SG_ AutoEpbButtn_B_Stat : 19|1@0+ (1,0) [0|1] "SED"  GWM
 SG_ TrlrAidMde_D_Rq : 5|2@0+ (1,0) [0|3] "SED"  GWM
 SG_ TCU_Init_Actvtn_St : 1|2@0+ (1,0) [0|3] "SED"  GWM
 SG_ TCU_Final_Actvtn_St : 3|2@0+ (1,0) [0|3] "SED"  GWM
 SG_ DcacPw_D_Rq : 62|2@0+ (1,0) [0|3] "SED"  GWM
 SG_ DcacPwReset_B_Rq : 63|1@0+ (1,0) [0|1] "SED"  GWM
 SG_ LghtAmbDrvMde_D_Rq : 49|2@0+ (1,0) [0|3] "SED"  GWM
 SG_ OtaTrg_D_Stat : 41|2@0+ (1,0) [0|3] "SED"  GWM
 SG_ DcacPwLoButtn_B_Stat : 13|1@0+ (1,0) [0|1] "SED"  GWM
 SG_ DcacPwOffButtn_B_Stat : 12|1@0+ (1,0) [0|1] "SED"  GWM
 SG_ DcacPwHiButtn_B_Stat : 14|1@0+ (1,0) [0|1] "SED"  GWM
 SG_ DcacPwResetButtn_B_Stat : 11|1@0+ (1,0) [0|1] "SED"  GWM
 SG_ DcacPwButtn_B_Falt : 15|1@0+ (1,0) [0|1] "SED"  GWM
 SG_ OnbChrgGoTTouch_D_Rq : 43|2@0+ (1,0) [0|3] "SED"  GWM
 SG_ OnbChrgGoTPrcond_D_Rq : 34|2@0+ (1,0) [0|3] "SED"  GWM
 SG_ OnbChrgGoTOn_D_Rq : 25|2@0+ (1,0) [0|3] "SED"  GWM
 SG_ OnbChrgGoTMnte_D_Rq : 47|4@0+ (1,0) [0|15] "minute"  GWM
 SG_ OnbChrgGoTHr_T_Rq : 39|5@0+ (1,0) [0|29] "hour"  GWM
 SG_ OnbChrgGoTExtHtr_D_Rq : 27|2@0+ (1,0) [0|3] "SED"  GWM
 SG_ OnbChrgGoTElement_D_Rq : 31|4@0+ (1,0) [0|15] "Unitless"  GWM
 SG_ OnbChrgGoTDelete_B_Rq : 17|1@0+ (1,0) [0|1] "SED"  GWM
 SG_ OnbChrgClearAll_B_Rq : 18|1@0+ (1,0) [0|1] "SED"  GWM
 SG_ OnbChrgGoTUpdate_B_Rq : 16|1@0+ (1,0) [0|1] "SED"  GWM
 SG_ TrlrAlarmButtn_B_Stat : 50|1@0+ (1,0) [0|1] "SED"  TRM_ITRM,GWM
 SG_ DcacMdeButtn_B_Stat : 8|1@0+ (1,0) [0|1] "SED"  GWM
 SG_ DcacGfciTestBttn_B_Stat : 9|1@0+ (1,0) [0|1] "SED"  GWM
 SG_ TrlrBrkGain_No_Rq : 55|5@0+ (0.5,0) [0|15.5] "unitless"  TRM_ITRM,GWM
 SG_ TrlrHitch_D_RqMnu : 23|4@0+ (1,0) [0|15] "SED"  GWM
 SG_ DcacPwButtn_B_Stat : 10|1@0+ (1,0) [0|1] "SED"  GWM

BO_ 1184 APIM_TCU_Word_Rx_HS3: 8 GWM
 SG_ APIM_TCU_Word_Rx : 7|64@0+ (1,0) [0|1.84467440737096E+019] "unitless"  APIM_CISM,APIM

BO_ 801 DISP_Chime_Req: 8 APIM
 SG_ CDWarnChime_St : 3|1@0+ (1,0) [0|1] "SED"  IPC
 SG_ SoftWarning : 6|1@0+ (1,0) [0|1] "SED"  IPC
 SG_ HardWarning : 5|1@0+ (1,0) [0|1] "SED"  IPC
 SG_ InfoWarning : 7|1@0+ (1,0) [0|1] "SED"  IPC
 SG_ DrvDsplyPalette_D_Stat : 2|3@0+ (1,0) [0|7] "SED"  IPC

BO_ 878 Rear_Climate_Data2: 8 RACM_RCIM
 SG_ ClimtSyncRear2_B_Stat : 58|1@0+ (1,0) [0|1] "SED"  GENERIC,GWM
 SG_ ClimtStHeatRr2_B_Stat : 54|1@0+ (1,0) [0|1] "SED"  GENERIC,GWM
 SG_ ClimtStHeatRl2_B_Stat : 55|1@0+ (1,0) [0|1] "SED"  GENERIC,GWM
 SG_ ClimtStCoolRr2_B_Stat : 52|1@0+ (1,0) [0|1] "SED"  GENERIC,GWM
 SG_ ClimtStCoolRl2_B_Stat : 53|1@0+ (1,0) [0|1] "SED"  GENERIC,GWM
 SG_ ClimtSeatRr2_D_Rq : 39|8@0+ (1,0) [0|64] "SED"  GENERIC,GWM
 SG_ ClimtSeatRl2_D_Rq : 47|8@0+ (1,0) [0|64] "SED"  GENERIC,GWM
 SG_ ClimtRrTe3rd2_D_Stat : 51|2@0+ (1,0) [0|3] "SED"  GENERIC,GWM
 SG_ ClimtRrPw3rd2_B_Stat : 59|1@0+ (1,0) [0|1] "SED"  GENERIC,GWM
 SG_ ClimtRrPnl3rd2_B_Stat : 62|1@0+ (1,0) [0|1] "SED"  GENERIC,GWM
 SG_ ClimtRrPf3rd2_B_Stat : 63|1@0+ (1,0) [0|1] "SED"  GENERIC,GWM
 SG_ ClimtRrFlr3rd2_B_Stat : 61|1@0+ (1,0) [0|1] "SED"  GENERIC,GWM
 SG_ ClimtRrBlwr3rd2_D_Stat : 49|2@0+ (1,0) [0|3] "SED"  GENERIC,GWM
 SG_ ClimtRrAuto3rd2_B_Stat : 60|1@0+ (1,0) [0|1] "SED"  GENERIC,GWM
 SG_ ClimtRearView2_D_Stat : 57|2@0+ (1,0) [0|3] "SED"  GENERIC,GWM
 SG_ ClimtRearTe2_D_Stat : 11|2@0+ (1,0) [0|3] "SED"  GENERIC,GWM
 SG_ ClimtRearTe2_An_Actl : 7|9@0+ (1,0) [0|510] "degrees"  GENERIC,GWM
 SG_ ClimtRearPw2_B_Stat : 29|1@0+ (1,0) [0|1] "SED"  GENERIC,GWM
 SG_ ClimtRearPnlFlr2_B_Stat : 13|1@0+ (1,0) [0|1] "SED"  GENERIC,GWM
 SG_ ClimtRearPnl2_B_Stat : 14|1@0+ (1,0) [0|1] "SED"  GENERIC,GWM
 SG_ ClimtRearFlr2_B_Stat : 12|1@0+ (1,0) [0|1] "SED"  GENERIC,GWM
 SG_ ClimtRearBlwr2_D_Stat : 9|2@0+ (1,0) [0|3] "SED"  GENERIC,GWM
 SG_ ClimtRearBlwr2_An_Actl : 23|9@0+ (1,0) [0|510] "degrees"  GENERIC,GWM
 SG_ ClimtRearAuto2_B_Stat : 30|1@0+ (1,0) [0|1] "SED"  GENERIC,GWM

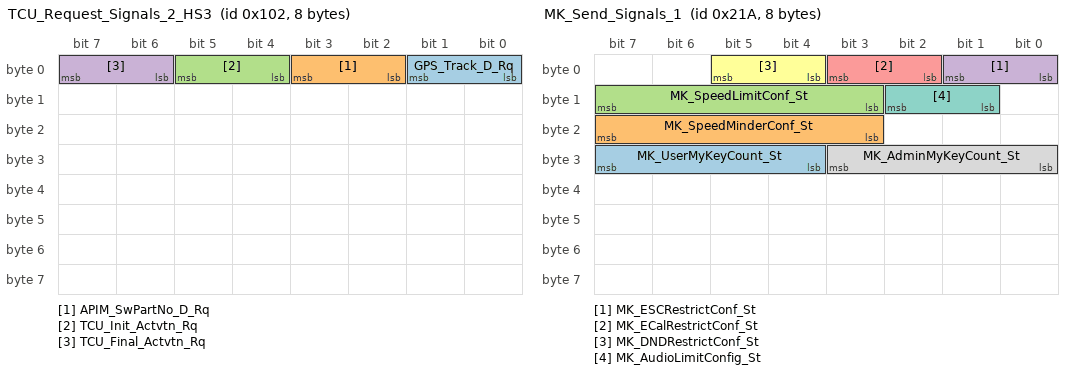
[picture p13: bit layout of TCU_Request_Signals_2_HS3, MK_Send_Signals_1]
BO_ 258 TCU_Request_Signals_2_HS3: 8 GWM
 SG_ GPS_Track_D_Rq : 1|2@0+ (1,0) [0|3] "SED"  APIM_CISM,APIM
 SG_ APIM_SwPartNo_D_Rq : 3|2@0+ (1,0) [0|3] "SED"  APIM_CISM,APIM
 SG_ TCU_Init_Actvtn_Rq : 5|2@0+ (1,0) [0|3] "SED"  APIM_CISM,APIM
 SG_ TCU_Final_Actvtn_Rq : 7|2@0+ (1,0) [0|3] "SED"  APIM_CISM,APIM

BO_ 1192 APIM_TCU_Word_Tx: 8 APIM
 SG_ APIM_TCU_Word_Tx : 7|64@0+ (1,0) [0|1.84467440737096E+019] "unitless"  GWM

BO_ 259 MFD_Request_Signals2: 8 APIM
 SG_ SDARS_CurrCATlstSize_Rq : 15|8@0+ (1,0) [0|255] "unitless"  ACM
 SG_ SDARS_CurrCATlistInd_Rq : 7|8@0+ (1,0) [0|255] "unitless"  ACM
 SG_ SDARS_ChipControl_Rq : 21|3@0+ (1,0) [0|7] "SED"  ACM
 SG_ SDARS_AlertStatus_Rq : 23|2@0+ (1,0) [0|3] "SED"  ACM

BO_ 538 MK_Send_Signals_1: 8 IPC
 SG_ MK_UserMyKeyCount_St : 31|4@0+ (1,0) [0|13] "SED"  APIM_CISM,APIM
 SG_ MK_SpeedMinderConf_St : 23|5@0+ (1,0) [0|31] "SED"  APIM_CISM,APIM
 SG_ MK_SpeedLimitConf_St : 15|5@0+ (1,0) [0|31] "SED"  APIM_CISM,APIM
 SG_ MK_ESCRestrictConf_St : 1|2@0+ (1,0) [0|3] "SED"  APIM_CISM,GENERIC
 SG_ MK_ECalRestrictConf_St : 3|2@0+ (1,0) [0|3] "SED"  APIM_CISM,APIM
 SG_ MK_DNDRestrictConf_St : 5|2@0+ (1,0) [0|3] "SED"  APIM_CISM,APIM
 SG_ MK_AudioLimitConfig_St : 10|2@0+ (1,0) [0|3] "SED"  APIM_CISM,APIM
 SG_ MK_AdminMyKeyCount_St : 27|4@0+ (1,0) [0|13] "SED"  APIM_CISM,APIM

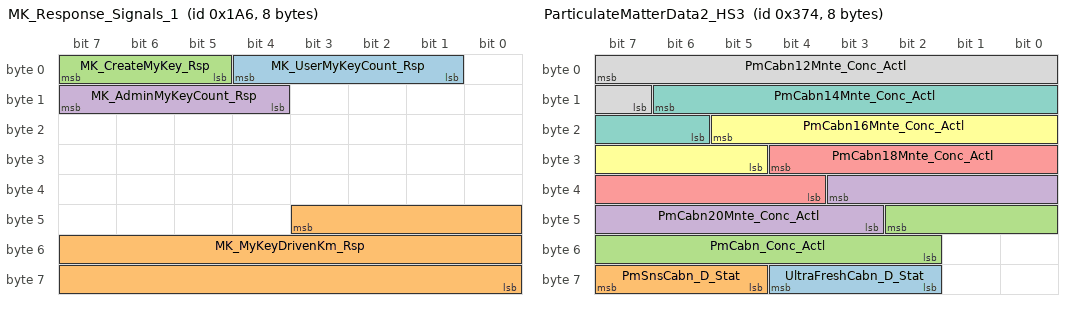
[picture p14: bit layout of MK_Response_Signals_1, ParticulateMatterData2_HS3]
BO_ 422 MK_Response_Signals_1: 8 IPC
 SG_ MK_UserMyKeyCount_Rsp : 4|4@0+ (1,0) [0|15] "SED"  APIM_CISM,APIM
 SG_ MK_MyKeyDrivenKm_Rsp : 43|20@0+ (1,0) [0|1048575] "km"  APIM_CISM,APIM
 SG_ MK_CreateMyKey_Rsp : 7|3@0+ (1,0) [0|7] "SED"  APIM_CISM,APIM
 SG_ MK_AdminMyKeyCount_Rsp : 15|4@0+ (1,0) [0|15] "SED"  APIM_CISM,APIM

BO_ 2008 TesterPhysicalResAPIM: 8 APIM
 SG_ TesterPhysicalResAPIM : 7|64@0+ (1,0) [0|1.84467E+019] "unitless"  TSTR

BO_ 884 ParticulateMatterData2_HS3: 8 GWM
 SG_ UltraFreshCabn_D_Stat : 60|3@0+ (1,0) [0|7] "SED"  APIM_CISM,GENERIC
 SG_ PmSnsCabn_D_Stat : 63|3@0+ (1,0) [0|7] "SED"  APIM_CISM,APIM
 SG_ PmCabn_Conc_Actl : 42|9@0+ (1,0) [0|509] "parts/million"  APIM_CISM,APIM
 SG_ PmCabn20Mnte_Conc_Actl : 35|9@0+ (1,0) [0|509] "parts/million"  RACM_RCIM,APIM_CISM,APIM
 SG_ PmCabn18Mnte_Conc_Actl : 28|9@0+ (1,0) [0|509] "parts/million"  RACM_RCIM,APIM_CISM,APIM
 SG_ PmCabn16Mnte_Conc_Actl : 21|9@0+ (1,0) [0|509] "parts/million"  RACM_RCIM,APIM_CISM,APIM
 SG_ PmCabn14Mnte_Conc_Actl : 14|9@0+ (1,0) [0|509] "parts/million"  RACM_RCIM,APIM_CISM,APIM
 SG_ PmCabn12Mnte_Conc_Actl : 7|9@0+ (1,0) [0|509] "parts/million"  RACM_RCIM,APIM_CISM,APIM

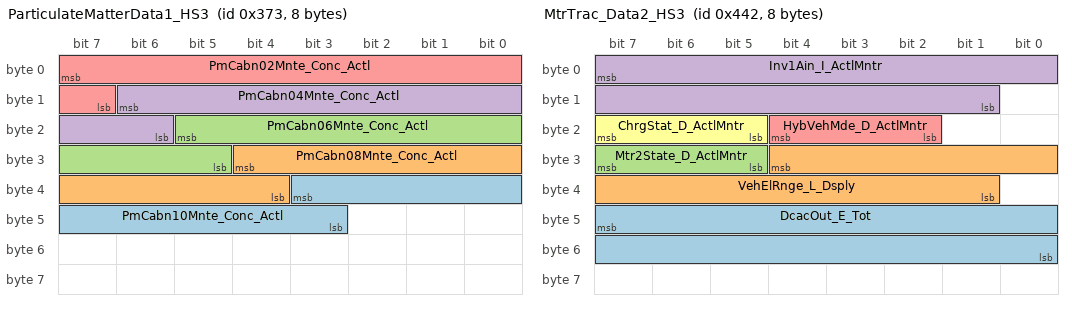
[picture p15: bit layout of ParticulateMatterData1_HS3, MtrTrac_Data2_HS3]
BO_ 883 ParticulateMatterData1_HS3: 8 GWM
 SG_ PmCabn10Mnte_Conc_Actl : 35|9@0+ (1,0) [0|509] "parts/million"  RACM_RCIM,APIM_CISM,APIM
 SG_ PmCabn08Mnte_Conc_Actl : 28|9@0+ (1,0) [0|509] "parts/million"  RACM_RCIM,APIM_CISM,APIM
 SG_ PmCabn06Mnte_Conc_Actl : 21|9@0+ (1,0) [0|509] "parts/million"  RACM_RCIM,APIM_CISM,APIM
 SG_ PmCabn04Mnte_Conc_Actl : 14|9@0+ (1,0) [0|509] "parts/million"  RACM_RCIM,APIM_CISM,APIM
 SG_ PmCabn02Mnte_Conc_Actl : 7|9@0+ (1,0) [0|509] "parts/million"  RACM_RCIM,APIM_CISM,APIM

BO_ 1090 MtrTrac_Data2_HS3: 8 GWM
 SG_ DcacOut_E_Tot : 47|16@0+ (20,0) [0|1310700] "watthour"  GENERIC
 SG_ VehElRnge_L_Dsply : 28|12@0+ (0.1,0) [0|409.3] "kilometer"  APIM_CISM,APIM,HUD_ADV,IPC
 SG_ Mtr2State_D_ActlMntr : 31|3@0+ (1,0) [0|7] "SED" Vector__XXX
 SG_ Inv1Ain_I_ActlMntr : 7|15@0+ (0.1,-1000) [-1000|2276.5] "ampere"  GENERIC
 SG_ HybVehMde_D_ActlMntr : 20|3@0+ (1,0) [0|7] "SED"  GENERIC
 SG_ ChrgStat_D_ActlMntr : 23|3@0+ (1,0) [0|7] "SED"  GENERIC

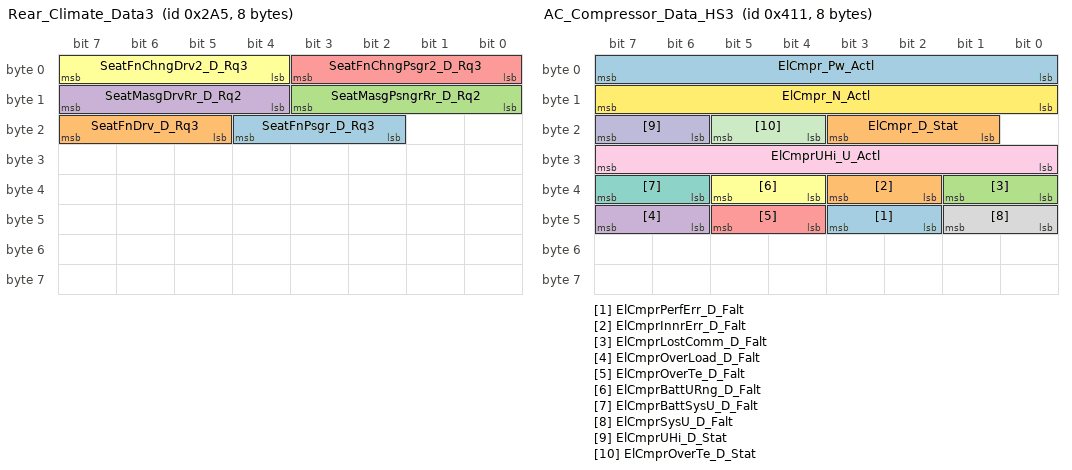
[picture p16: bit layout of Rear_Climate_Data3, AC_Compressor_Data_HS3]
BO_ 677 Rear_Climate_Data3: 8 RACM_RCIM
 SG_ SeatFnPsgr_D_Rq3 : 20|3@0+ (1,0) [0|7] "SED"  GWM
 SG_ SeatFnDrv_D_Rq3 : 23|3@0+ (1,0) [0|7] "SED"  GWM
 SG_ SeatMasgPsngrRr_D_Rq2 : 11|4@0+ (1,0) [0|15] "SED"  GWM
 SG_ SeatMasgDrvRr_D_Rq2 : 15|4@0+ (1,0) [0|15] "SED"  GWM
 SG_ SeatFnChngPsgr2_D_Rq3 : 3|4@0+ (1,0) [0|15] "SED"  GWM
 SG_ SeatFnChngDrv2_D_Rq3 : 7|4@0+ (1,0) [0|15] "SED"  GWM

BO_ 1238 IPMA_Data5_HS3: 8 GWM
 SG_ IaccVAdjReas_D_Dsply : 15|5@0+ (1,0) [0|31] "SED"  APIM,APIM_CISM,IPC
 SG_ IaccVAdjLim_No_Actl : 7|8@0+ (1,0) [0|255] "unitless"  APIM,APIM_CISM,IPC

BO_ 1041 AC_Compressor_Data_HS3: 8 GWM
 SG_ ElCmprPerfErr_D_Falt : 43|2@0+ (1,0) [0|3] "SED" Vector__XXX
 SG_ ElCmprInnrErr_D_Falt : 35|2@0+ (1,0) [0|3] "SED" Vector__XXX
 SG_ ElCmprLostComm_D_Falt : 33|2@0+ (1,0) [0|3] "SED" Vector__XXX
 SG_ ElCmprOverLoad_D_Falt : 47|2@0+ (1,0) [0|3] "SED" Vector__XXX
 SG_ ElCmprOverTe_D_Falt : 45|2@0+ (1,0) [0|3] "SED" Vector__XXX
 SG_ ElCmprBattURng_D_Falt : 37|2@0+ (1,0) [0|3] "SED" Vector__XXX
 SG_ ElCmprBattSysU_D_Falt : 39|2@0+ (1,0) [0|3] "SED" Vector__XXX
 SG_ ElCmprSysU_D_Falt : 41|2@0+ (1,0) [0|3] "SED" Vector__XXX
 SG_ ElCmprUHi_U_Actl : 31|8@0+ (2,0) [0|510] "volt" Vector__XXX
 SG_ ElCmprUHi_D_Stat : 23|2@0+ (1,0) [0|3] "SED" Vector__XXX
 SG_ ElCmprOverTe_D_Stat : 21|2@0+ (1,0) [0|3] "SED" Vector__XXX
 SG_ ElCmpr_N_Actl : 15|8@0+ (50,0) [0|12700] "RPM"  WCM
 SG_ ElCmpr_Pw_Actl : 7|8@0+ (40,0) [0|10160] "watts" Vector__XXX
 SG_ ElCmpr_D_Stat : 19|3@0+ (1,0) [0|7] "SED" Vector__XXX

BO_ 2609971416 OTAPhysGWM_ECGtoWCM: 8 GWM
 SG_ OTAPhysGWM_ECGtoWCM : 7|29@0+ (1,0) [0|536870911] "unitless"  WCM

BO_ 2610126912 OTAPhysWCMtoGWM_ECG: 8 WCM
 SG_ OTAPhysWCMtoGWM_ECG : 7|29@0+ (1,0) [0|536870911] "unitless"  GWM

BO_ 2611019992 PARSEDPhysGWM_ECGtoWCM: 8 GWM
 SG_ PARSEDPhysGWM_ECGtoWCM : 7|29@0+ (1,0) [0|536870911] "unitless"  WCM

BO_ 2611175488 PARSEDPhysWCMtoGWM_ECG: 8 WCM
 SG_ PARSEDPhysWCMtoGWM_ECG : 7|29@0+ (1,0) [0|536870911] "unitless"  GWM

BO_ 2612068568 PARSEDPushFcGWM_ECGtoWCM: 8 GWM
 SG_ PARSEDPushFcGWM_ECGtoWCM : 7|29@0+ (1,0) [0|536870911] "unitless"  WCM

BO_ 2612224064 PARSEDPushFcWCMtoGWM_ECG: 8 WCM
 SG_ PARSEDPushFcwcmtoGWM_ECG : 7|29@0+ (1,0) [0|536870911] "unitless"  GWM

BO_ 557 DSPAMP_Send_Signals_2: 8 DSP
 SG_ AudioToneTouchY_D_Stat : 15|8@0+ (1,0) [0|255] "SED"  APIM_CISM,APIM
 SG_ AudioToneTouchX_D_Stat : 7|8@0+ (1,0) [0|255] "SED"  APIM_CISM,APIM
 SG_ AudioToneTouch_D_Stat : 23|2@0+ (1,0) [0|3] "SED"  APIM_CISM,APIM

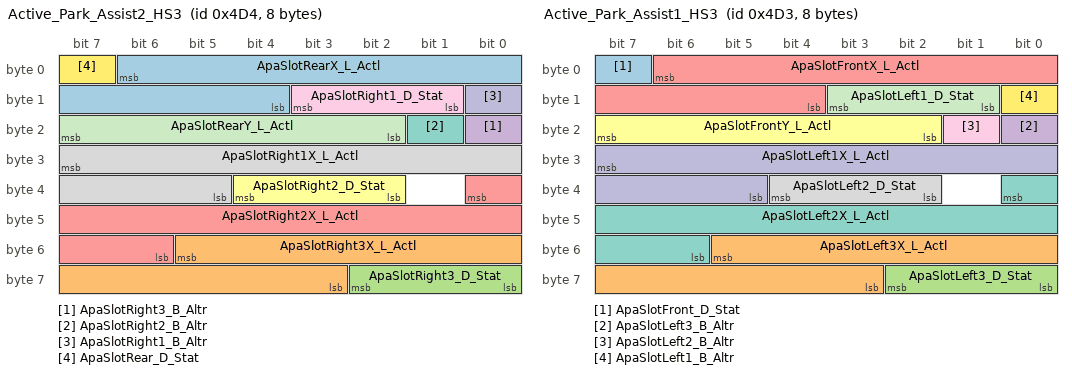
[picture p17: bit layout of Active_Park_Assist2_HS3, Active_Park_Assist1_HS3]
BO_ 1236 Active_Park_Assist2_HS3: 8 GWM
 SG_ ApaSlotRearX_L_Actl : 6|11@0+ (0.02,-20.96) [-20.96|19.98] "meter"  APIM_CISM,APIM
 SG_ ApaSlotRight3X_L_Actl : 53|11@0+ (0.02,-20.96) [-20.96|19.98] "meter"  APIM_CISM,APIM
 SG_ ApaSlotRight3_D_Stat : 58|3@0+ (1,0) [0|7] "SE"  APIM_CISM,APIM
 SG_ ApaSlotRight3_B_Altr : 16|1@0+ (1,0) [0|1] "SED"  APIM_CISM,APIM
 SG_ ApaSlotRight2X_L_Actl : 32|11@0+ (0.02,-20.96) [-20.96|19.98] "meter"  APIM_CISM,APIM
 SG_ ApaSlotRight2_D_Stat : 36|3@0+ (1,0) [0|7] "SED"  APIM_CISM,APIM
 SG_ ApaSlotRight2_B_Altr : 17|1@0+ (1,0) [0|1] "SED"  APIM_CISM,APIM
 SG_ ApaSlotRight1X_L_Actl : 31|11@0+ (0.02,-20.96) [-20.96|19.98] "meter"  APIM_CISM,APIM
 SG_ ApaSlotRight1_D_Stat : 11|3@0+ (1,0) [0|7] "SE"  APIM_CISM,APIM
 SG_ ApaSlotRight1_B_Altr : 8|1@0+ (1,0) [0|1] "SED"  APIM_CISM,APIM
 SG_ ApaSlotRearY_L_Actl : 23|6@0+ (0.22,-6.4) [-6.4|6.2] "meter"  APIM_CISM,APIM
 SG_ ApaSlotRear_D_Stat : 7|1@0+ (1,0) [0|1] "SED"  APIM_CISM,APIM

BO_ 1235 Active_Park_Assist1_HS3: 8 GWM
 SG_ ApaSlotFront_D_Stat : 7|1@0+ (1,0) [0|1] "SED"  APIM_CISM,APIM
 SG_ ApaSlotLeft3X_L_Actl : 53|11@0+ (0.02,-20.96) [-20.96|19.98] "meter"  APIM_CISM,APIM
 SG_ ApaSlotLeft3_D_Stat : 58|3@0+ (1,0) [0|7] "SED"  APIM_CISM,APIM
 SG_ ApaSlotLeft3_B_Altr : 16|1@0+ (1,0) [0|1] "SED"  APIM_CISM,APIM
 SG_ ApaSlotFrontX_L_Actl : 6|11@0+ (0.02,-20.96) [-20.96|19.98] "meter"  APIM_CISM,APIM
 SG_ ApaSlotFrontY_L_Actl : 23|6@0+ (0.2,-6.4) [-6.4|6.2] "meter"  APIM_CISM,APIM
 SG_ ApaSlotLeft2X_L_Actl : 32|11@0+ (0.02,-20.96) [-20.96|19.98] "meter"  APIM_CISM,APIM
 SG_ ApaSlotLeft2_D_Stat : 36|3@0+ (1,0) [0|7] "SED"  APIM_CISM,APIM
 SG_ ApaSlotLeft2_B_Altr : 17|1@0+ (1,0) [0|1] "SED"  APIM_CISM,APIM
 SG_ ApaSlotLeft1X_L_Actl : 31|11@0+ (0.02,-20.96) [-20.96|19.98] "meter"  APIM_CISM,APIM
 SG_ ApaSlotLeft1_D_Stat : 11|3@0+ (1,0) [0|7] "SED"  APIM_CISM,APIM
 SG_ ApaSlotLeft1_B_Altr : 8|1@0+ (1,0) [0|1] "SED"  APIM_CISM,APIM

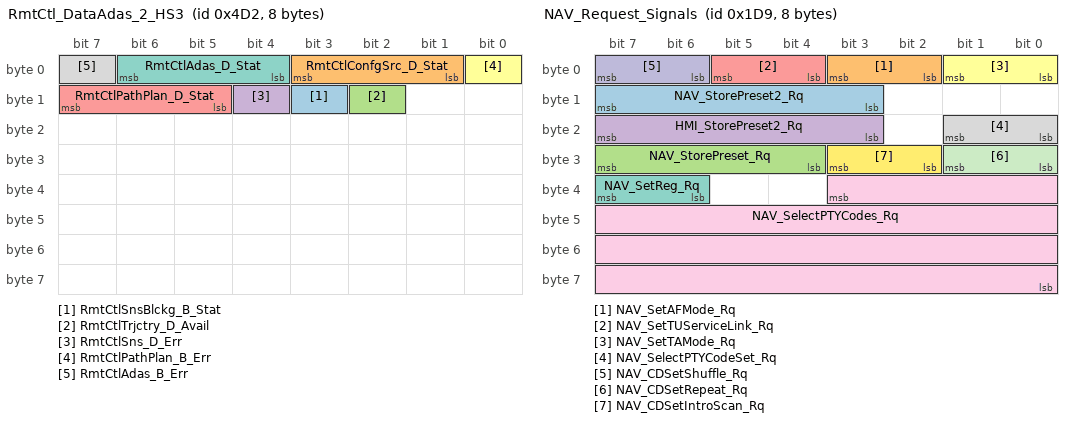
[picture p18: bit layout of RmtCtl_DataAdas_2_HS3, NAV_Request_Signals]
BO_ 1234 RmtCtl_DataAdas_2_HS3: 8 GWM
 SG_ RmtCtlSnsBlckg_B_Stat : 11|1@0+ (1,0) [0|1] "SED"  GENERIC
 SG_ RmtCtlConfgSrc_D_Stat : 3|3@0+ (1,0) [0|7] "SED"  GENERIC
 SG_ RmtCtlTrjctry_D_Avail : 10|1@0+ (1,0) [0|1] "SED"  GENERIC
 SG_ RmtCtlSns_D_Err : 12|1@0+ (1,0) [0|1] "SED"  GENERIC
 SG_ RmtCtlPathPlan_D_Stat : 15|3@0+ (1,0) [0|7] "SED"  GENERIC
 SG_ RmtCtlPathPlan_B_Err : 0|1@0+ (1,0) [0|1] "SED"  GENERIC
 SG_ RmtCtlAdas_D_Stat : 6|3@0+ (1,0) [0|7] "SED"  GENERIC
 SG_ RmtCtlAdas_B_Err : 7|1@0+ (1,0) [0|1] "SED"  GENERIC

BO_ 1237 Active_Park_Assist3_HS3: 8 GWM
 SG_ ApaSlotRef2Y_L_Actl : 31|11@0+ (0.02,-20.96) [-20.96|19.98] "meter"  APIM_CISM,APIM
 SG_ ApaSlotRef2X_L_Actl : 12|11@0+ (0.02,-20.96) [-20.96|19.98] "meter"  APIM_CISM,APIM
 SG_ ApaSlotRef1Y_L_Actl : 36|11@0+ (0.02,-20.96) [-20.96|19.98] "meter"  APIM_CISM,APIM
 SG_ ApaSlotRef1X_L_Actl : 7|11@0+ (0.02,-20.96) [-20.96|19.98] "meter"  APIM_CISM,APIM

BO_ 976 VehCharacteristicSet2_HS3: 8 GWM
 SG_ VehLong2_A_Actl_UB : 34|1@0+ (1,0) [0|1] "SED"  ACM
 SG_ VehLong2_A_Actl : 52|13@0+ (0.01,-40) [-40|41.89] "m/s^2"  ACM

BO_ 715 SSPClnt_SSPSrv_WORD_Rx: 8 APIM
 SG_ RDISP_SSP_WORD_Rx : 7|64@0+ (1,0) [0|1.84467440737096E+019] "unitless"  ACM

BO_ 925 TripInfoData3_HS3: 8 GWM
 SG_ TripSumDrvE_Pc_Dsply : 25|10@0+ (0.1,0) [0|102.1] "percent"  APIM,IPC
 SG_ TripExtFctrE_Pc_Dsply : 19|10@0+ (0.1,0) [0|102.1] "percent"  APIM,IPC
 SG_ TripClimE_Pc_Dsply : 13|10@0+ (0.1,0) [0|102.1] "percent"  APIM,IPC
 SG_ TripBattULoE_Pc_Dsply : 7|10@0+ (0.1,0) [0|102.1] "percent"  APIM,IPC

BO_ 788 PowertrainData_13_HS3: 8 GWM
 SG_ EcoCochDecel2_Pc_Dsply : 47|8@0+ (0.392157,0) [0|100.000035] "percent"  APIM
 SG_ EcoCochDecel1_Pc_Dsply : 39|8@0+ (0.392157,0) [0|100.000035] "percent"  APIM
 SG_ EcoCochCrus2_Pc_Dsply : 31|8@0+ (0.392157,0) [0|100.000035] "percent"  APIM
 SG_ EcoCochCrus1_Pc_Dsply : 23|8@0+ (0.392157,0) [0|100.000035] "percent"  APIM
 SG_ EcoCochATrip2_Pc_Dsply : 15|8@0+ (0.392157,0) [0|100.000035] "percent"  APIM
 SG_ EcoCochATrip1_Pc_Dsply : 7|8@0+ (0.392157,0) [0|100.000035] "percent"  APIM

BO_ 473 NAV_Request_Signals: 8 APIM
 SG_ NAV_StorePreset2_Rq : 15|5@0+ (1,0) [0|31] "SED"  ACM
 SG_ NAV_SetAFMode_Rq : 3|2@0+ (1,0) [0|3] "SED"  ACM,GENERIC
 SG_ NAV_StorePreset_Rq : 31|4@0+ (1,0) [0|15] "SED"  ACM,GENERIC
 SG_ HMI_StorePreset2_Rq : 23|5@0+ (1,0) [0|31] "SED"  ACM
 SG_ NAV_SetTUServiceLink_Rq : 5|2@0+ (1,0) [0|3] "SED"  ACM
 SG_ NAV_SetTAMode_Rq : 1|2@0+ (1,0) [0|3] "SED"  ACM
 SG_ NAV_SetReg_Rq : 39|2@0+ (1,0) [0|3] "SED"  ACM
 SG_ NAV_SelectPTYCodeSet_Rq : 17|2@0+ (1,0) [0|3] "SED"  ACM
 SG_ NAV_SelectPTYCodes_Rq : 35|28@0+ (1,0) [0|268435455] "unitless"  ACM
 SG_ NAV_CDSetShuffle_Rq : 7|2@0+ (1,0) [0|3] "SED"  ACM
 SG_ NAV_CDSetRepeat_Rq : 25|2@0+ (1,0) [0|3] "SED"  ACM
 SG_ NAV_CDSetIntroScan_Rq : 27|2@0+ (1,0) [0|3] "SED"  ACM

BO_ 2000 TesterPhysicalReqAPIM: 8 TSTR
 SG_ TesterPhysicalReqAPIM : 7|64@0+ (1,0) [0|1.84467E+019] "unitless"  APIM,APIM_CISM

BO_ 810 ECG_Data_HS3: 8 GWM
 SG_ ExtLghtDsply_B_StatArb : 7|1@0+ (1,0) [0|1] "SED"  APIM
 SG_ OneTEditActv_B_RqCld : 32|1@0+ (1,0) [0|1] "SED"  APIM

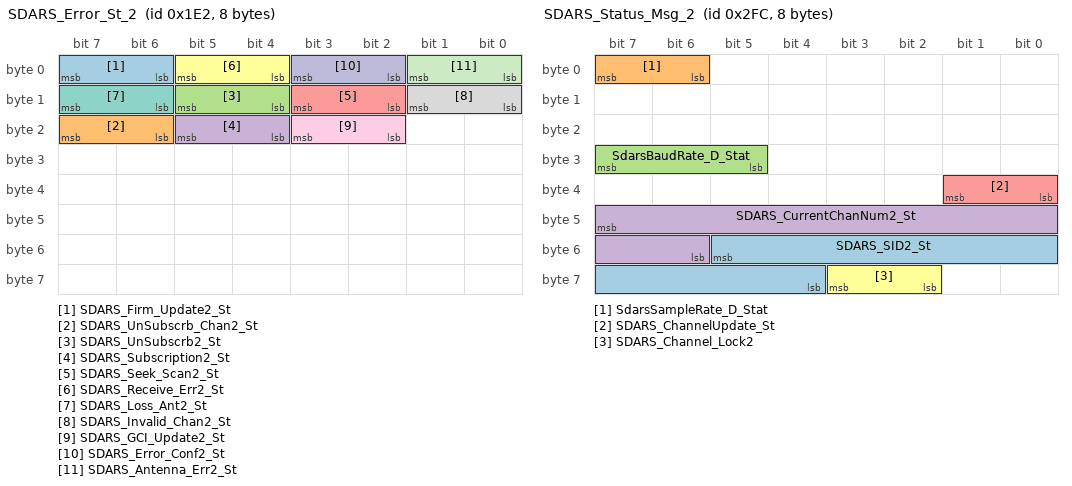
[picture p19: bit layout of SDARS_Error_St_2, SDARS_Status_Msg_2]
BO_ 482 SDARS_Error_St_2: 8 APIM
 SG_ SDARS_Firm_Update2_St : 7|2@0+ (1,0) [0|3] "SED"  IPC
 SG_ SDARS_UnSubscrb_Chan2_St : 23|2@0+ (1,0) [0|3] "SED"  IPC
 SG_ SDARS_UnSubscrb2_St : 13|2@0+ (1,0) [0|3] "SED"  IPC
 SG_ SDARS_Subscription2_St : 21|2@0+ (1,0) [0|3] "SED"  IPC
 SG_ SDARS_Seek_Scan2_St : 11|2@0+ (1,0) [0|3] "SED"  IPC
 SG_ SDARS_Receive_Err2_St : 5|2@0+ (1,0) [0|3] "SED"  IPC
 SG_ SDARS_Loss_Ant2_St : 15|2@0+ (1,0) [0|3] "SED"  IPC
 SG_ SDARS_Invalid_Chan2_St : 9|2@0+ (1,0) [0|3] "SED"  IPC
 SG_ SDARS_GCI_Update2_St : 19|2@0+ (1,0) [0|3] "SED"  IPC
 SG_ SDARS_Error_Conf2_St : 3|2@0+ (1,0) [0|3] "SED"  IPC
 SG_ SDARS_Antenna_Err2_St : 1|2@0+ (1,0) [0|3] "SED"  IPC

BO_ 764 SDARS_Status_Msg_2: 8 APIM
 SG_ SDARS_SID2_St : 53|10@0+ (1,0) [0|1023] "unitless"  ACM
 SG_ SdarsSampleRate_D_Stat : 7|2@0+ (1,0) [0|3] "SED"  ACM
 SG_ SdarsBaudRate_D_Stat : 31|3@0+ (1,0) [0|7] "SED"  ACM
 SG_ SDARS_CurrentChanNum2_St : 47|10@0+ (1,0) [0|1023] "unitless"  IPC,ACM
 SG_ SDARS_ChannelUpdate_St : 33|2@0+ (1,0) [0|3] "SED"  ACM
 SG_ SDARS_Channel_Lock2 : 59|2@0+ (1,0) [0|3] "SED"  ACM

BO_TX_BU_ 1116 : APIM_CISM,APIM;
BO_TX_BU_ 529 : APIM_CISM,APIM;
BO_TX_BU_ 600 : APIM_CISM,APIM;
BO_TX_BU_ 414 : APIM_CISM,ACM;
BO_TX_BU_ 533 : APIM_CISM,APIM;
BO_TX_BU_ 801 : ACM,APIM_CISM,APIM;
BO_TX_BU_ 1192 : APIM_CISM,APIM;
BO_TX_BU_ 2008 : APIM_CISM,APIM;
CM_ SG_ 502 Dsp_StartItemIndexRq "Object Media Player BT SDCard.GetMPInfo.StartItemIndex
USB.GetMPInfo.StartItemIndex
SingleCD.GetMPInfo.StartItemIndex

$FFFF: Inactive";
CM_ SG_ 502 Dsp_NbrOfItems2_Rq "Object Media Player 
BT Audio.GetMPInfo.NbrOfItems
SDCard.GetMPInfo.NbrOfItems
USB.GetMPInfo.NbrOfItems
SingleCD.GetMPInfo.NbrOfItems";
CM_ SG_ 502 Dsp_ItemNameLength2_Rq "Object Media Player 
BT Audio.GetMPInfo.ItemNameLength
SDCard.GetMPInfo.ItemNameLength
USB.GetMPInfo.ItemNameLength
SingleCD.GetMPInfo.ItemNameLength";
CM_ SG_ 502 Dsp_FolderNumber2_Rq "Object Media Player 
BT Audio.GetMPInfo.FolderNumber
USB.GetMPInfo.FolderNumber
SDCard.GetMPInfo.FolderNumber
SingleCD.GetMPInfo.FolderNumber

$FFFF: Inactive";
CM_ SG_ 502 Dsp_FolderContent_Rq "Object Media Player 
BT Audio.GetMPInfo.FolderContent
SDCard.GetMPInfo.FolderContent
USB.GetMPInfo.FolderContent
SingleCD.GetMPinfo.Foldercontent

Note: Value table entries were truncated from:
$0: ..FolderNumber
$1: ..OfParameterFolderNumber";
CM_ SG_ 502 Dsp_CutItem2_Rq "Object Media Player 
BT Audio.GetMPInfo.CutItemName
SDCard.GetMPInfo.CutItemName
USB.GetMPInfo.CutItemName
SingleCD.GetMPInfo.CutItemName

Note: value table entry for value $2 was truncated from:
OneQuarterFromTheBeginningThreeQuarterFromTheEnd";
CM_ SG_ 502 Dsp_AudioSourceSel2_Rq "Object Media Player 
BT Audio.GetMPInfo.AudioSource
SDCard.GetMPInfo.AudioSource
USB.GetMPInfo.AudioSource
SingleCD.GetMPInfo.AudioSource";
CM_ SG_ 500 Dsp_SourceSetTrack_Rq "Object Media Player BTAudio.SetTrack
Object Media Player USB.SetTrack
Object Single CD.SetTrack.AudioSource
";
CM_ SG_ 500 Dsp_ItemNameLength_Rq "Object Media Player BTAudio.GetFolderName.ItemNameLength
Object Media Player USB.GetFolderName.ItemNameLength
Object Single CD.GetFolderName.ItemNameLength";
CM_ SG_ 500 Dsp_GetCDTOCDData_Rq "GetCDTOCData";
CM_ SG_ 500 Dsp_FolderNumber_Rq "Object Media Player BTAudio.GetFolderName.FolderNumber
Object Media Player USB.GetFolderName.FolderNumber
Object Single CD.GetFolderName.FolderNumber";
CM_ SG_ 500 Dsp_CutItem_Rq "Object Media Player BTAudio.GetFolderName.CutItemName
Object Media Player USB.GetFolderName.CutItemName
Object Single CD.GetFolderName.CutItemName

Note: value table entry for value $2 was truncated from:
OneQuarterFromTheBeginningThreeQuarterFromTheEnd";
CM_ SG_ 500 Dsp_AudioSourceSel_Rq "Object Media Player 
{ BTAudio.GetFolderName, 
SDCard.GetFolderName,
USB.GetFolderName,
BTAudio.SetTrack,
SD Card.SetTrack}.AudioSource
USB.SetTrack.AudioSource
Object Single CD.GetFolderName.AudioSource
Object Single CD.SetTrack.AudioSource";
CM_ SG_ 503 Dsp_PlayFrstTrInFldr_Rq "Object Single CD.PlayFirstTrackInFolder
Object Media Player BTAudio.PlayFirstTrackInFolder.FolderNumber
Object Media Player USB.PlayFirstTrackInFolder.FolderNumber

$FFFF: Inactive";
CM_ SG_ 503 Dsp_ItemIndex_Rq "Object Media Player BTAudio.GetDetailedMPInfo.ItemIndex
Object Media Player USB.GetDetailedMPInfo.ItemIndex

$FFFF: Inactive";
CM_ SG_ 503 Dsp_FolderNumber3_Rq "Object Media Player BTAudio.GetDetailedMPInfo.FolderNumber
Object Media Player USB.GetDetailedMPInfo.FolderNumber

$FFFF: Inactive";
CM_ SG_ 503 Dsp_AudioSourceSel3_Rq "Objects Media Player  {BTAudio, USB}.GetDetailedMPInfo.AudioSource

Objects Media Player {Single CD, BTAudio, USB}.PlayFirstTrackInFolder.AudioSource";
CM_ SG_ 412 LBC2_StartItemInd "Object. ListBrowser.ItemInf.Rq.StartItemInd
0x0000:Inactive
0x0001:1
0xFFFE:65634
0xFFFF:Reserved";
CM_ SG_ 412 LBC2_SetListServ "Object. ListBrowser.ItemInf.Rq.SetListServ
0x00:Inactive
0x01:ServerID_1
0xFF:ALL";
CM_ SG_ 412 LBC2_Opcode "Object. ListBrowser.ItemInf.Rq.Opcode";
CM_ SG_ 412 LBC2_NbrOfItems "Object. ListBrowser.ItemInf.Rq.NbrOfItems
0x00:Inactive
0x01:1Item
0x3F:63Items";
CM_ SG_ 412 LBC2_ItemIndex "Object. ListBrowser.ItemInf.Rq.ItemIndex
0x0000:BrowseActiveListID
0x0001:EntryIndex_1
0xFFFF:ParentOfActiveListID";
CM_ SG_ 412 LBC2_ActiveListID "Object. ListBrowser.ItemInf.Rq.ActiveListID
0x0000:Root
0xFFFF:Reserved";
CM_ SG_ 493 Dsp_StatLiScanCancel_Rq "Object Tuner.StationListScan";
CM_ SG_ 493 Dsp_StationList_Rq "Object Tuner.GetStationList(StationList)
(Parameter1)";
CM_ SG_ 493 Dsp_StartIndex3_Rq "Object TunerGetStationList(StartingIndex)
(Parameter3)";
CM_ SG_ 493 Dsp_RefreshFlag "Object Tuner.GetStationList(StationList)
(Parameter5)";
CM_ SG_ 493 Dsp_PTYCode_Rq "Object Tuner.GetStationList(PTYCode)
(Parramater4)

$0: Invalid
$1: PTY 1 (News)
..
$1F: PTY 31 (Alarm)";
CM_ SG_ 493 Dsp_ListSize_Rq "Object Tuner.GetStationList(ListSize)
(Parameter2)";
CM_ SG_ 493 Dsp_AFJump_Rq "Object Tuner.AFJump.Rq";
CM_ SG_ 511 Dsp_TUStartIndex2_Rq "Object Tuner.GetTUPresetInfo.StartIndex2
Object DAB.GetTUPresetInfo.StartIndex2
Object SDARS.GetTUPresetInfo.StartIndex2

$1-$FF: Preset 1 to 255";
CM_ SG_ 511 Dsp_TUPresetArea_Rq "Object Tuner.GetTUPresetInfo.PresetArea
Object DAB.GetTUPresetInfo.PresetArea
Object SDARS.GetTUPresetInfo.PresetArea";
CM_ SG_ 511 Dsp_TUNbrOfPresets_Rq "Object Tuner.GetTUPresetInfo.NumberOfPresets
Object DAB.GetTUPresetInfo.NumberOfPresets
Object SDARS.GetTUPresetInfo.NumberOfPresets

$1-$1E: Preset 1 to 30";
CM_ SG_ 511 Dsp_SetCurrTUPreset_Rq "Object Tuner.GetTUPresetInfo.SetCurrentTUPreset
Object DAB.GetTUPresetInfo.SetCurrentTUPreset
Object SDARS.GetTUPresetInfo.SetCurrentTUPreset

$1-$1E: Preset 1 to 30";
CM_ SG_ 511 Dsp_SetCurrTUBand_Rq "Object Tuner.SetCurrTUBand
Object DAB.SetCurrTUBand
Object SDARS.SetCurrTUBand
";
CM_ SG_ 257 MFD_SetTagMode "Used by MFD to distribute actual Master Clock data to the Slave";
CM_ SG_ 257 MFD_SetRBDSMode "Used by MFD to distribute actual Master Clock data to the Slave";
CM_ SG_ 257 MFD_SetHDModeRq "Used by MFD to distribute actual Master Clock data to the Slave";
CM_ SG_ 257 MFD_GetTagInfo "Used by MFD to distribute actual Master Clock data to the Slave";
CM_ BO_ 382 "ECM, PCM Gas Only msg";
CM_ BO_ 600 "Tx by HS3 APIM";
CM_ SG_ 600 APIM_RFA_BLEM_Tx "Tx by HS3 APIM";
CM_ SG_ 708 TMCSrvr_TMCClnt_WORD_Tx "MM ISO 15765-2 Message Catalogue RDISP2 - AUDIO";
CM_ SG_ 414 LBS2_ParentID "Object. ListBrowser.ItemInf.Rq.ActiveListID
0x0000:Root
0xFFFF:Reserved";
CM_ SG_ 414 LBS2_ListID "Object. ListBrowser.ItemInf.Rq.ItemIndex
0x0000:BrowseActiveListID
0x0001:EntryIndex_1
0xFFFF:ParentOfActiveListID";
CM_ SG_ 414 LBS2_EntryIndex "Object. ListBrowser.ItemInf.Rq.ActiveListID
0x0000:Root
0xFFFF:Reserved";
CM_ SG_ 641 IgnPsswrdSetup_B_Rq "ABSGenSigTimeoutTime=1000";
CM_ SG_ 641 IgnPsswrdLckout_B_Stat "ABSGenSigTimeoutTime=1000";
CM_ BO_ 1184 "TP message";
CM_ SG_ 1192 APIM_TCU_Word_Tx "Tx by HS3 APIM";
CM_ SG_ 259 SDARS_CurrCATlstSize_Rq "Object:SDARSClient.CurrentCatList.Rq.NumberOfItems 

0x00: Invalid
0x01: List Size 1
0x02: List Size 2
....
0x1E: List Size 30
0xFF: No Entry
";
CM_ SG_ 259 SDARS_CurrCATlistInd_Rq "ObjectTuner.SDARSTuner.CurrentCATList
$0: Inactive
$FF:No_Entry";
CM_ SG_ 259 SDARS_AlertStatus_Rq "Object.SDARSClient.AlertStatus.Rq.Status";
CM_ SG_ 538 MK_UserMyKeyCount_St "Object MyKey.SystemKeyCount_St
[Parameter1]";
CM_ SG_ 538 MK_SpeedMinderConf_St "Object MyKey.SpeedMinderConfig_St";
CM_ SG_ 538 MK_SpeedLimitConf_St "Object MyKey.SpeedLimitConfig_St";
CM_ SG_ 538 MK_ECalRestrictConf_St "Object MyKey.ECallRestrictionConfig_St";
CM_ SG_ 538 MK_DNDRestrictConf_St "Object MyKey.DNDRestrictionConfig_St";
CM_ SG_ 538 MK_AudioLimitConfig_St "Object MyKey.AudioLimitConfig_St";
CM_ SG_ 538 MK_AdminMyKeyCount_St "Object MyKey.SystemKeyCount_St
[Parameter2]";
CM_ SG_ 473 NAV_SetAFMode_Rq "Object Tuner.SetAFMode";
CM_ SG_ 473 NAV_StorePreset_Rq "Object Tuner.StorePreset

NOTE: If used on CANalyzer/CANoe for the older DENSO HighNav System, wrong values will be shown!";
CM_ SG_ 473 NAV_SetTUServiceLink_Rq "Object Tuner.NAV_SetTUServiceLink_Rq";
CM_ SG_ 473 NAV_SetTAMode_Rq "Object Tuner.SetTAMode";
CM_ SG_ 473 NAV_SetReg_Rq "Object Tuner.SetREG";
CM_ SG_ 473 NAV_SelectPTYCodeSet_Rq "Object Tuner.SelectPTYCodes

Set PTY code with the follow bit encoding";
CM_ SG_ 473 NAV_SelectPTYCodes_Rq "Object Tuner.SelectPTYCodes

28 bit bitfield where each PTY code can be set separately:
Bit 0:  0:  PTY Code 2 not selected; 1:  PTY Code 2 selected
...
Bit 27: PTY Code 29 not selected; 1:  PTY Code 29 selected";
CM_ SG_ 473 NAV_CDSetShuffle_Rq "Object Single CD.SetShuffle";
CM_ SG_ 473 NAV_CDSetRepeat_Rq "Object Single CD.SetRepeat";
CM_ SG_ 473 NAV_CDSetIntroScan_Rq "Object Single CD.SetIntroScan";
CM_ SG_ 482 SDARS_Firm_Update2_St "Object Tuner.SDARS Tuner.FirmwareUpdate";
CM_ SG_ 482 SDARS_UnSubscrb_Chan2_St "Object Tuner.SDARS Tuner.Unsubscribed Channel ";
CM_ SG_ 482 SDARS_UnSubscrb2_St "Object Tuner.SDARS Tuner.Unsubscribed Receiver ";
CM_ SG_ 482 SDARS_Subscription2_St "Object Tuner.SDARS Tuner.Subscription Update ";
CM_ SG_ 482 SDARS_Seek_Scan2_St "Method SDARS_Error_Msg
Int Seek/Scan No Channels Available

0x1: No Channel Available
Object Tuner.SDARS Tuner.";
CM_ SG_ 482 SDARS_Receive_Err2_St "Object Tuner.SDARS Tuner.Receiver Error";
CM_ SG_ 482 SDARS_Loss_Ant2_St "Object Tuner.SDARS Tuner.Loss of Antenna Signal ";
CM_ SG_ 482 SDARS_Invalid_Chan2_St "Object Tuner.SDARS Tuner.";
CM_ SG_ 482 SDARS_GCI_Update2_St "Object Tuner.SDARS Tuner.GCI Update ";
CM_ SG_ 482 SDARS_Error_Conf2_St "Object Tuner.SDARS Tuner.Configuration Status";
CM_ SG_ 482 SDARS_Antenna_Err2_St "Object Tuner.SDARS Tuner.Antenna Error";
CM_ SG_ 764 SDARS_SID2_St "Object Tuner.SDARS.ServiceID
$0: SID_0
$1: SID_1
$2: SID_2
$FE: SID_254
$FF: SID_255

";
CM_ SG_ 764 SDARS_CurrentChanNum2_St "Object Tuner.SDARS Tuner.CurrentChanNum.ChanNum 
$0: Channel_0
$1: Channel_1
$2: Channel_2
$FE: Channel_254
$FF: Inactive";
CM_ SG_ 764 SDARS_Channel_Lock2 "Method SDARS_Channel_Lock";
BA_DEF_ BO_  "FrameRouting" STRING ;
BA_DEF_ BO_  "FrameGatewayNetwork" STRING ;
BA_DEF_ BO_  "NetworkInitialization" ENUM  "No","Yes";
BA_DEF_ BO_  "FrameGatewayId" HEX 0 1407;
BA_DEF_ BO_  "EventRateOfChange" INT 10 10000;
BA_DEF_ BO_  "GenMsgStartDelayTime" INT 0 10000;
BA_DEF_ BO_  "GenMsgNrOfRepetition" INT 0 100;
BA_DEF_ BO_  "GenMsgDelayTime" INT 0 1000;
BA_DEF_ BO_  "GenMsgCycleTime" INT 0 100000;
BA_DEF_ BO_  "GenMsgSendType" ENUM  "FixedPeriodic","Event","EnabledPeriodic","NotUsed","NotUsed","EventPeriodic","NotUsed","NotUsed","NoMsgSendType";
BA_DEF_ SG_  "U_U55X_MY2022_Tx" ENUM  "No","Yes";
BA_DEF_ SG_  "U_CD542_MY2021_Tx" ENUM  "No","Yes";
BA_DEF_ SG_  "ECGUsedTxSignal" ENUM  "No","Yes";
BA_DEF_ SG_  "U_T6_MCA_MY2020_Tx" ENUM  "No","Yes";
BA_DEF_ SG_  "U_P702_MY2021_Tx" ENUM  "No","Yes";
BA_DEF_ SG_  "U_CX727_MY2021_Tx" ENUM  "No","Yes";
BA_DEF_ SG_  "U_FNV2_IVI_Rx" ENUM  "No","Yes";
BA_DEF_ SG_  "U_U55X_MY2022_Rx" ENUM  "No","Yes";
BA_DEF_ SG_  "U_CD542_MY2021_Rx" ENUM  "No","Yes";
BA_DEF_ SG_  "ECGUsedRxSignal" ENUM  "No","Yes";
BA_DEF_ SG_  "U_T6_MCA_MY2020_Rx" ENUM  "No","Yes";
BA_DEF_ SG_  "U_P702_MY2021_Rx" ENUM  "No","Yes";
BA_DEF_ SG_  "U_CX727_MY2021_Rx" ENUM  "No","Yes";
BA_DEF_ SG_  "GenSigStartValue" HEX 0 268435455;
BA_DEF_ SG_  "MetaData" ENUM  "No","Yes";
BA_DEF_ SG_  "ContentDependant" ENUM  "No","Yes";
BA_DEF_ SG_  "GenSigStartValueInteger" INT 0 1000000000;
BA_DEF_ SG_  "UsedOnPgmDBC" ENUM  "No","Yes";
BA_DEF_ SG_  "WakeupSignal" ENUM  "No","Yes";
BA_DEF_ SG_  "GenSigInactiveValue" INT 0 100000;
BA_DEF_ SG_  "GenSigSendType" ENUM  "Cyclic","OnWrite","vector_leerstring","OnChange","vector_leerstring","IfActive","vector_leerstring","NoSigSendType";
BA_DEF_ BO_  "OvtpPushApplication" ENUM  "FALSE","TRUE";
BA_DEF_ BO_  "SCP_FreshnessValueLength" INT 0 512;
BA_DEF_ BO_  "SCP_FreshnessValueTxLength" INT 0 512;
BA_DEF_ BO_  "SCP_AuthInfoTxLength" INT 0 512;
BA_DEF_ BO_  "GenMsgRoutingTimeoutTime" INT 0 5000;
BA_DEF_ BO_  "MessageGateway" ENUM  "No","Yes";
BA_DEF_ BO_  "NmAsrMessage" ENUM  "No","Yes";
BA_DEF_ BO_  "DiagState" ENUM  "No","Yes";
BA_DEF_ BO_  "TpTxIndex" INT 0 536870911;
BA_DEF_ BO_  "DiagRequest" ENUM  "No","Yes";
BA_DEF_ BO_  "DiagResponse" ENUM  "No","Yes";
BA_DEF_ BO_  "GenMsgILSupport" ENUM  "No","Yes";
BA_DEF_DEF_  "FrameRouting" "";
BA_DEF_DEF_  "FrameGatewayNetwork" "NONE";
BA_DEF_DEF_  "NetworkInitialization" "Yes";
BA_DEF_DEF_  "FrameGatewayId" 0;
BA_DEF_DEF_  "EventRateOfChange" 10000;
BA_DEF_DEF_  "GenMsgStartDelayTime" 0;
BA_DEF_DEF_  "GenMsgNrOfRepetition" 1;
BA_DEF_DEF_  "GenMsgDelayTime" 20;
BA_DEF_DEF_  "GenMsgCycleTime" 0;
BA_DEF_DEF_  "GenMsgSendType" "NoMsgSendType";
BA_DEF_DEF_  "U_U55X_MY2022_Tx" "No";
BA_DEF_DEF_  "U_CD542_MY2021_Tx" "No";
BA_DEF_DEF_  "ECGUsedTxSignal" "No";
BA_DEF_DEF_  "U_T6_MCA_MY2020_Tx" "No";
BA_DEF_DEF_  "U_P702_MY2021_Tx" "No";
BA_DEF_DEF_  "U_CX727_MY2021_Tx" "No";
BA_DEF_DEF_  "U_FNV2_IVI_Rx" "No";
BA_DEF_DEF_  "U_U55X_MY2022_Rx" "No";
BA_DEF_DEF_  "U_CD542_MY2021_Rx" "No";
BA_DEF_DEF_  "ECGUsedRxSignal" "No";
BA_DEF_DEF_  "U_T6_MCA_MY2020_Rx" "No";
BA_DEF_DEF_  "U_P702_MY2021_Rx" "No";
BA_DEF_DEF_  "U_CX727_MY2021_Rx" "No";
BA_DEF_DEF_  "GenSigStartValue" 0;
BA_DEF_DEF_  "MetaData" "No";
BA_DEF_DEF_  "ContentDependant" "No";
BA_DEF_DEF_  "GenSigStartValueInteger" 0;
BA_DEF_DEF_  "UsedOnPgmDBC" "Yes";
BA_DEF_DEF_  "WakeupSignal" "No";
BA_DEF_DEF_  "GenSigInactiveValue" 0;
BA_DEF_DEF_  "GenSigSendType" "NoSigSendType";
BA_DEF_DEF_  "OvtpPushApplication" "FALSE";
BA_DEF_DEF_  "SCP_FreshnessValueLength" 64;
BA_DEF_DEF_  "SCP_FreshnessValueTxLength" 11;
BA_DEF_DEF_  "SCP_AuthInfoTxLength" 53;
BA_DEF_DEF_  "GenMsgRoutingTimeoutTime" 0;
BA_DEF_DEF_  "MessageGateway" "No";
BA_DEF_DEF_  "NmAsrMessage" "No";
BA_DEF_DEF_  "DiagState" "No";
BA_DEF_DEF_  "TpTxIndex" 0;
BA_DEF_DEF_  "DiagRequest" "No";
BA_DEF_DEF_  "DiagResponse" "No";
BA_DEF_DEF_  "GenMsgILSupport" "Yes";
BA_ "NetworkInitialization" BO_ 1931 0;
BA_ "GenMsgDelayTime" BO_ 1931 0;
BA_ "GenMsgSendType" BO_ 1931 1;
BA_ "DiagResponse" BO_ 1931 1;
BA_ "GenMsgILSupport" BO_ 1931 0;
BA_ "NetworkInitialization" BO_ 1478 0;
BA_ "GenMsgCycleTime" BO_ 1478 1000;
BA_ "GenMsgSendType" BO_ 1478 0;
BA_ "NmAsrMessage" BO_ 1478 1;
BA_ "GenMsgILSupport" BO_ 1478 0;
BA_ "GenMsgSendType" BO_ 502 1;
BA_ "FrameRouting" BO_ 955 "HS1_CAN,0x3BB;";
BA_ "FrameGatewayNetwork" BO_ 955 "HS1_CAN";
BA_ "FrameGatewayId" BO_ 955 955;
BA_ "GenMsgCycleTime" BO_ 1116 1000;
BA_ "GenMsgSendType" BO_ 1116 5;
BA_ "GenMsgCycleTime" BO_ 1113 50;
BA_ "GenMsgSendType" BO_ 1113 0;
BA_ "FrameRouting" BO_ 1255 "FD1_CAN,0x4E7;MS1_CAN,0x4E7";
BA_ "FrameRouting" BO_ 1254 "FD1_CAN,0x4E6;MS1_CAN,0x4E6";
BA_ "FrameRouting" BO_ 1253 "FD1_CAN,0x4E5;MS1_CAN,0x4E5";
BA_ "FrameRouting" BO_ 1252 "FD1_CAN,0x4E4;MS1_CAN,0x4E4";
BA_ "FrameRouting" BO_ 1251 "FD1_CAN,0x4E3;MS1_CAN,0x4E3";
BA_ "FrameRouting" BO_ 1250 "FD1_CAN,0x4E2;MS1_CAN,0x4E2";
BA_ "FrameRouting" BO_ 1249 "FD1_CAN,0x4E1;MS1_CAN,0x4E1";
BA_ "FrameRouting" BO_ 1248 "FD1_CAN,0x4E0;MS1_CAN,0x4E0";
BA_ "GenMsgCycleTime" BO_ 1256 1000;
BA_ "GenMsgSendType" BO_ 1256 5;
BA_ "GenMsgCycleTime" BO_ 529 1000;
BA_ "GenMsgSendType" BO_ 529 5;
BA_ "GenMsgCycleTime" BO_ 642 1000;
BA_ "GenMsgSendType" BO_ 642 5;
BA_ "GenMsgCycleTime" BO_ 893 1000;
BA_ "GenMsgSendType" BO_ 893 0;
BA_ "GenMsgSendType" BO_ 500 1;
BA_ "GenMsgSendType" BO_ 503 1;
BA_ "GenMsgSendType" BO_ 412 1;
BA_ "GenMsgSendType" BO_ 493 1;
BA_ "GenMsgSendType" BO_ 511 1;
BA_ "GenMsgSendType" BO_ 257 1;
BA_ "TpTxIndex" BO_ 713 27;
BA_ "FrameRouting" BO_ 382 "FD1_CAN,0x17E;";
BA_ "FrameGatewayNetwork" BO_ 382 "FD1_CAN";
BA_ "FrameGatewayId" BO_ 382 382;
BA_ "FrameRouting" BO_ 877 "MS1_CAN,0x36D;";
BA_ "FrameGatewayNetwork" BO_ 877 "MS1_CAN";
BA_ "FrameGatewayId" BO_ 877 877;
BA_ "FrameRouting" BO_ 592 "HS4_CAN,0x250";
BA_ "FrameGatewayNetwork" BO_ 592 "HS4_CAN";
BA_ "FrameGatewayId" BO_ 592 592;
BA_ "TpTxIndex" BO_ 592 50;
BA_ "TpTxIndex" BO_ 600 50;
BA_ "TpTxIndex" BO_ 708 33;
BA_ "GenMsgSendType" BO_ 414 1;
BA_ "TpTxIndex" BO_ 716 33;
BA_ "FrameRouting" BO_ 1013 "HS1_CAN,0x3F5;";
BA_ "FrameGatewayNetwork" BO_ 1013 "HS1_CAN";
BA_ "FrameGatewayId" BO_ 1013 1013;
BA_ "GenMsgCycleTime" BO_ 641 1000;
BA_ "GenMsgSendType" BO_ 641 5;
BA_ "FrameRouting" BO_ 1012 "HS1_CAN,0x3F4;";
BA_ "FrameGatewayNetwork" BO_ 1012 "HS1_CAN";
BA_ "FrameGatewayId" BO_ 1012 1012;
BA_ "FrameRouting" BO_ 1011 "FD1_CAN,0x3F3;HS1_CAN,0x3F3";
BA_ "GenMsgCycleTime" BO_ 533 1000;
BA_ "GenMsgSendType" BO_ 533 5;
BA_ "FrameRouting" BO_ 1184 "HS4_CAN,0x4A0";
BA_ "FrameGatewayNetwork" BO_ 1184 "HS4_CAN";
BA_ "FrameGatewayId" BO_ 1184 1184;
BA_ "TpTxIndex" BO_ 1184 20;
BA_ "GenMsgCycleTime" BO_ 801 1000;
BA_ "GenMsgSendType" BO_ 801 5;
BA_ "GenMsgCycleTime" BO_ 878 1000;
BA_ "GenMsgSendType" BO_ 878 5;
BA_ "FrameRouting" BO_ 258 "HS4_CAN,0x102;";
BA_ "FrameGatewayNetwork" BO_ 258 "HS4_CAN";
BA_ "FrameGatewayId" BO_ 258 258;
BA_ "TpTxIndex" BO_ 1192 20;
BA_ "GenMsgSendType" BO_ 259 1;
BA_ "GenMsgCycleTime" BO_ 538 1000;
BA_ "GenMsgSendType" BO_ 538 5;
BA_ "GenMsgSendType" BO_ 422 1;
BA_ "NetworkInitialization" BO_ 2008 0;
BA_ "GenMsgDelayTime" BO_ 2008 0;
BA_ "GenMsgSendType" BO_ 2008 1;
BA_ "DiagResponse" BO_ 2008 1;
BA_ "GenMsgILSupport" BO_ 2008 0;
BA_ "FrameRouting" BO_ 884 "MS1_CAN,0x374;";
BA_ "FrameGatewayNetwork" BO_ 884 "MS1_CAN";
BA_ "FrameGatewayId" BO_ 884 884;
BA_ "FrameRouting" BO_ 883 "MS1_CAN,0x373;";
BA_ "FrameGatewayNetwork" BO_ 883 "MS1_CAN";
BA_ "FrameGatewayId" BO_ 883 883;
BA_ "FrameRouting" BO_ 1090 "FD1_CAN,0x442;HS1_CAN,0x442";
BA_ "GenMsgCycleTime" BO_ 677 1000;
BA_ "GenMsgSendType" BO_ 677 5;
BA_ "FrameRouting" BO_ 1238 "FD1_CAN,0x4D6;";
BA_ "FrameGatewayNetwork" BO_ 1238 "FD1_CAN";
BA_ "FrameGatewayId" BO_ 1238 1238;
BA_ "FrameRouting" BO_ 1041 "HS1_CAN,0x411;";
BA_ "FrameGatewayNetwork" BO_ 1041 "HS1_CAN";
BA_ "FrameGatewayId" BO_ 1041 1041;
BA_ "NetworkInitialization" BO_ 2609971416 0;
BA_ "GenMsgDelayTime" BO_ 2609971416 0;
BA_ "GenMsgSendType" BO_ 2609971416 1;
BA_ "TpTxIndex" BO_ 2609971416 462487768;
BA_ "NetworkInitialization" BO_ 2610126912 0;
BA_ "GenMsgDelayTime" BO_ 2610126912 0;
BA_ "GenMsgSendType" BO_ 2610126912 1;
BA_ "TpTxIndex" BO_ 2610126912 462487768;
BA_ "NetworkInitialization" BO_ 2611019992 0;
BA_ "GenMsgDelayTime" BO_ 2611019992 0;
BA_ "GenMsgSendType" BO_ 2611019992 1;
BA_ "TpTxIndex" BO_ 2611019992 463536344;
BA_ "NetworkInitialization" BO_ 2611175488 0;
BA_ "GenMsgDelayTime" BO_ 2611175488 0;
BA_ "GenMsgSendType" BO_ 2611175488 1;
BA_ "TpTxIndex" BO_ 2611175488 463536344;
BA_ "NetworkInitialization" BO_ 2612068568 0;
BA_ "GenMsgDelayTime" BO_ 2612068568 0;
BA_ "GenMsgSendType" BO_ 2612068568 1;
BA_ "TpTxIndex" BO_ 2612068568 464584920;
BA_ "NetworkInitialization" BO_ 2612224064 0;
BA_ "GenMsgDelayTime" BO_ 2612224064 0;
BA_ "GenMsgSendType" BO_ 2612224064 1;
BA_ "TpTxIndex" BO_ 2612224064 464584920;
BA_ "GenMsgCycleTime" BO_ 557 1000;
BA_ "GenMsgSendType" BO_ 557 5;
BA_ "FrameRouting" BO_ 1236 "FD1_CAN,0x4D4;";
BA_ "FrameGatewayNetwork" BO_ 1236 "FD1_CAN";
BA_ "FrameGatewayId" BO_ 1236 1236;
BA_ "FrameRouting" BO_ 1235 "FD1_CAN,0x4D3;";
BA_ "FrameGatewayNetwork" BO_ 1235 "FD1_CAN";
BA_ "FrameGatewayId" BO_ 1235 1235;
BA_ "FrameRouting" BO_ 1234 "FD1_CAN,0x4D2;";
BA_ "FrameGatewayNetwork" BO_ 1234 "FD1_CAN";
BA_ "FrameGatewayId" BO_ 1234 1234;
BA_ "FrameRouting" BO_ 1237 "FD1_CAN,0x4D5;";
BA_ "FrameGatewayNetwork" BO_ 1237 "FD1_CAN";
BA_ "FrameGatewayId" BO_ 1237 1237;
BA_ "GenMsgCycleTime" BO_ 976 1000;
BA_ "GenMsgSendType" BO_ 976 5;
BA_ "TpTxIndex" BO_ 715 23;
BA_ "FrameRouting" BO_ 925 "FD1_CAN,0x39D";
BA_ "FrameGatewayNetwork" BO_ 925 "FD1_CAN";
BA_ "FrameGatewayId" BO_ 925 925;
BA_ "FrameRouting" BO_ 788 "FD1_CAN,0x314;";
BA_ "FrameGatewayNetwork" BO_ 788 "FD1_CAN";
BA_ "FrameGatewayId" BO_ 788 788;
BA_ "GenMsgSendType" BO_ 473 1;
BA_ "NetworkInitialization" BO_ 2000 0;
BA_ "GenMsgDelayTime" BO_ 2000 0;
BA_ "GenMsgSendType" BO_ 2000 1;
BA_ "DiagRequest" BO_ 2000 1;
BA_ "GenMsgILSupport" BO_ 2000 0;
BA_ "GenMsgCycleTime" BO_ 810 1000;
BA_ "GenMsgSendType" BO_ 810 5;
BA_ "GenMsgCycleTime" BO_ 482 1000;
BA_ "GenMsgSendType" BO_ 482 5;
BA_ "GenMsgCycleTime" BO_ 764 1000;
BA_ "GenMsgSendType" BO_ 764 5;
BA_ "U_CD542_MY2021_Tx" SG_ 1931 TesterPhysicalResDSP 1;
BA_ "U_T6_MCA_MY2020_Tx" SG_ 1931 TesterPhysicalResDSP 1;
BA_ "GenSigSendType" SG_ 1931 TesterPhysicalResDSP 3;
BA_ "U_CD542_MY2021_Tx" SG_ 1478 DSP_GWOnBoardTester 1;
BA_ "U_T6_MCA_MY2020_Tx" SG_ 1478 DSP_GWOnBoardTester 1;
BA_ "U_T6_MCA_MY2020_Rx" SG_ 1478 DSP_GWOnBoardTester 1;
BA_ "GenSigStartValue" SG_ 1478 DSP_GWOnBoardTester 255;
BA_ "ContentDependant" SG_ 1478 DSP_GWOnBoardTester 1;
BA_ "GenSigStartValueInteger" SG_ 1478 DSP_GWOnBoardTester 255;
BA_ "U_CD542_MY2021_Tx" SG_ 1478 DSP_GWNMProxy 1;
BA_ "U_T6_MCA_MY2020_Tx" SG_ 1478 DSP_GWNMProxy 1;
BA_ "U_T6_MCA_MY2020_Rx" SG_ 1478 DSP_GWNMProxy 1;
BA_ "GenSigStartValue" SG_ 1478 DSP_GWNMProxy 255;
BA_ "ContentDependant" SG_ 1478 DSP_GWNMProxy 1;
BA_ "GenSigStartValueInteger" SG_ 1478 DSP_GWNMProxy 255;
BA_ "U_CD542_MY2021_Tx" SG_ 1478 DSP_AutoSarNMReserved4 1;
BA_ "U_T6_MCA_MY2020_Tx" SG_ 1478 DSP_AutoSarNMReserved4 1;
BA_ "U_T6_MCA_MY2020_Rx" SG_ 1478 DSP_AutoSarNMReserved4 1;
BA_ "GenSigStartValue" SG_ 1478 DSP_AutoSarNMReserved4 255;
BA_ "ContentDependant" SG_ 1478 DSP_AutoSarNMReserved4 1;
BA_ "GenSigStartValueInteger" SG_ 1478 DSP_AutoSarNMReserved4 255;
BA_ "U_CD542_MY2021_Tx" SG_ 1478 DSP_AutoSarNMReserved3 1;
BA_ "U_T6_MCA_MY2020_Tx" SG_ 1478 DSP_AutoSarNMReserved3 1;
BA_ "U_T6_MCA_MY2020_Rx" SG_ 1478 DSP_AutoSarNMReserved3 1;
BA_ "GenSigStartValue" SG_ 1478 DSP_AutoSarNMReserved3 255;
BA_ "ContentDependant" SG_ 1478 DSP_AutoSarNMReserved3 1;
BA_ "GenSigStartValueInteger" SG_ 1478 DSP_AutoSarNMReserved3 255;
BA_ "U_CD542_MY2021_Tx" SG_ 1478 DSP_AutoSarNMReserved2 1;
BA_ "U_T6_MCA_MY2020_Tx" SG_ 1478 DSP_AutoSarNMReserved2 1;
BA_ "U_T6_MCA_MY2020_Rx" SG_ 1478 DSP_AutoSarNMReserved2 1;
BA_ "GenSigStartValue" SG_ 1478 DSP_AutoSarNMReserved2 255;
BA_ "ContentDependant" SG_ 1478 DSP_AutoSarNMReserved2 1;
BA_ "GenSigStartValueInteger" SG_ 1478 DSP_AutoSarNMReserved2 255;
BA_ "U_CD542_MY2021_Tx" SG_ 1478 DSP_AutoSarNMReserved1 1;
BA_ "U_T6_MCA_MY2020_Tx" SG_ 1478 DSP_AutoSarNMReserved1 1;
BA_ "U_T6_MCA_MY2020_Rx" SG_ 1478 DSP_AutoSarNMReserved1 1;
BA_ "GenSigStartValue" SG_ 1478 DSP_AutoSarNMReserved1 255;
BA_ "ContentDependant" SG_ 1478 DSP_AutoSarNMReserved1 1;
BA_ "GenSigStartValueInteger" SG_ 1478 DSP_AutoSarNMReserved1 255;
BA_ "U_CD542_MY2021_Tx" SG_ 1478 DSP_AutoSarNMNodeId 1;
BA_ "U_T6_MCA_MY2020_Tx" SG_ 1478 DSP_AutoSarNMNodeId 1;
BA_ "U_T6_MCA_MY2020_Rx" SG_ 1478 DSP_AutoSarNMNodeId 1;
BA_ "GenSigStartValue" SG_ 1478 DSP_AutoSarNMNodeId 198;
BA_ "ContentDependant" SG_ 1478 DSP_AutoSarNMNodeId 1;
BA_ "GenSigStartValueInteger" SG_ 1478 DSP_AutoSarNMNodeId 198;
BA_ "U_CD542_MY2021_Tx" SG_ 1478 DSP_AutoSarNMControl 1;
BA_ "U_T6_MCA_MY2020_Tx" SG_ 1478 DSP_AutoSarNMControl 1;
BA_ "U_T6_MCA_MY2020_Rx" SG_ 1478 DSP_AutoSarNMControl 1;
BA_ "ContentDependant" SG_ 1478 DSP_AutoSarNMControl 1;
BA_ "U_CD542_MY2021_Tx" SG_ 502 Dsp_StartItemIndexRq 1;
BA_ "U_T6_MCA_MY2020_Tx" SG_ 502 Dsp_StartItemIndexRq 1;
BA_ "U_P702_MY2021_Tx" SG_ 502 Dsp_StartItemIndexRq 1;
BA_ "U_CD542_MY2021_Rx" SG_ 502 Dsp_StartItemIndexRq 1;
BA_ "U_T6_MCA_MY2020_Rx" SG_ 502 Dsp_StartItemIndexRq 1;
BA_ "U_P702_MY2021_Rx" SG_ 502 Dsp_StartItemIndexRq 1;
BA_ "U_CD542_MY2021_Tx" SG_ 502 Dsp_NbrOfItems2_Rq 1;
BA_ "U_T6_MCA_MY2020_Tx" SG_ 502 Dsp_NbrOfItems2_Rq 1;
BA_ "U_P702_MY2021_Tx" SG_ 502 Dsp_NbrOfItems2_Rq 1;
BA_ "U_CD542_MY2021_Rx" SG_ 502 Dsp_NbrOfItems2_Rq 1;
BA_ "U_T6_MCA_MY2020_Rx" SG_ 502 Dsp_NbrOfItems2_Rq 1;
BA_ "U_P702_MY2021_Rx" SG_ 502 Dsp_NbrOfItems2_Rq 1;
BA_ "U_CD542_MY2021_Tx" SG_ 502 Dsp_ItemNameLength2_Rq 1;
BA_ "U_T6_MCA_MY2020_Tx" SG_ 502 Dsp_ItemNameLength2_Rq 1;
BA_ "U_P702_MY2021_Tx" SG_ 502 Dsp_ItemNameLength2_Rq 1;
BA_ "U_CD542_MY2021_Rx" SG_ 502 Dsp_ItemNameLength2_Rq 1;
BA_ "U_T6_MCA_MY2020_Rx" SG_ 502 Dsp_ItemNameLength2_Rq 1;
BA_ "U_P702_MY2021_Rx" SG_ 502 Dsp_ItemNameLength2_Rq 1;
BA_ "U_CD542_MY2021_Tx" SG_ 502 Dsp_FolderNumber2_Rq 1;
BA_ "U_T6_MCA_MY2020_Tx" SG_ 502 Dsp_FolderNumber2_Rq 1;
BA_ "U_P702_MY2021_Tx" SG_ 502 Dsp_FolderNumber2_Rq 1;
BA_ "U_CD542_MY2021_Rx" SG_ 502 Dsp_FolderNumber2_Rq 1;
BA_ "U_T6_MCA_MY2020_Rx" SG_ 502 Dsp_FolderNumber2_Rq 1;
BA_ "U_P702_MY2021_Rx" SG_ 502 Dsp_FolderNumber2_Rq 1;
BA_ "U_CD542_MY2021_Tx" SG_ 502 Dsp_FolderContent_Rq 1;
BA_ "U_T6_MCA_MY2020_Tx" SG_ 502 Dsp_FolderContent_Rq 1;
BA_ "U_P702_MY2021_Tx" SG_ 502 Dsp_FolderContent_Rq 1;
BA_ "U_CD542_MY2021_Rx" SG_ 502 Dsp_FolderContent_Rq 1;
BA_ "U_T6_MCA_MY2020_Rx" SG_ 502 Dsp_FolderContent_Rq 1;
BA_ "U_P702_MY2021_Rx" SG_ 502 Dsp_FolderContent_Rq 1;
BA_ "U_CD542_MY2021_Tx" SG_ 502 Dsp_CutItem2_Rq 1;
BA_ "U_T6_MCA_MY2020_Tx" SG_ 502 Dsp_CutItem2_Rq 1;
BA_ "U_P702_MY2021_Tx" SG_ 502 Dsp_CutItem2_Rq 1;
BA_ "U_CD542_MY2021_Rx" SG_ 502 Dsp_CutItem2_Rq 1;
BA_ "U_T6_MCA_MY2020_Rx" SG_ 502 Dsp_CutItem2_Rq 1;
BA_ "U_P702_MY2021_Rx" SG_ 502 Dsp_CutItem2_Rq 1;
BA_ "U_CD542_MY2021_Tx" SG_ 502 Dsp_AudioSourceSel2_Rq 1;
BA_ "U_T6_MCA_MY2020_Tx" SG_ 502 Dsp_AudioSourceSel2_Rq 1;
BA_ "U_P702_MY2021_Tx" SG_ 502 Dsp_AudioSourceSel2_Rq 1;
BA_ "U_CD542_MY2021_Rx" SG_ 502 Dsp_AudioSourceSel2_Rq 1;
BA_ "U_T6_MCA_MY2020_Rx" SG_ 502 Dsp_AudioSourceSel2_Rq 1;
BA_ "U_P702_MY2021_Rx" SG_ 502 Dsp_AudioSourceSel2_Rq 1;
BA_ "GenSigSendType" SG_ 502 Dsp_AudioSourceSel2_Rq 3;
BA_ "U_CD542_MY2021_Rx" SG_ 955 Tire_Temp_RF_Data 1;
BA_ "U_T6_MCA_MY2020_Rx" SG_ 955 Tire_Temp_RF_Data 1;
BA_ "GenSigStartValue" SG_ 955 Tire_Temp_RF_Data 253;
BA_ "GenSigStartValueInteger" SG_ 955 Tire_Temp_RF_Data 253;
BA_ "U_CD542_MY2021_Rx" SG_ 955 Tire_Temp_ORR_Data 1;
BA_ "U_T6_MCA_MY2020_Rx" SG_ 955 Tire_Temp_ORR_Data 1;
BA_ "GenSigStartValue" SG_ 955 Tire_Temp_ORR_Data 253;
BA_ "GenSigStartValueInteger" SG_ 955 Tire_Temp_ORR_Data 253;
BA_ "U_CD542_MY2021_Rx" SG_ 955 Tire_Temp_OLR_Data 1;
BA_ "U_T6_MCA_MY2020_Rx" SG_ 955 Tire_Temp_OLR_Data 1;
BA_ "GenSigStartValue" SG_ 955 Tire_Temp_OLR_Data 253;
BA_ "GenSigStartValueInteger" SG_ 955 Tire_Temp_OLR_Data 253;
BA_ "U_CD542_MY2021_Rx" SG_ 955 Tire_Temp_LF_Data 1;
BA_ "U_T6_MCA_MY2020_Rx" SG_ 955 Tire_Temp_LF_Data 1;
BA_ "GenSigStartValue" SG_ 955 Tire_Temp_LF_Data 253;
BA_ "GenSigStartValueInteger" SG_ 955 Tire_Temp_LF_Data 253;
BA_ "U_CD542_MY2021_Rx" SG_ 955 Tire_Temp_IRR_Data 1;
BA_ "U_T6_MCA_MY2020_Rx" SG_ 955 Tire_Temp_IRR_Data 1;
BA_ "GenSigStartValue" SG_ 955 Tire_Temp_IRR_Data 253;
BA_ "GenSigStartValueInteger" SG_ 955 Tire_Temp_IRR_Data 253;
BA_ "U_CD542_MY2021_Rx" SG_ 955 Tire_Temp_ILR_Data 1;
BA_ "U_T6_MCA_MY2020_Rx" SG_ 955 Tire_Temp_ILR_Data 1;
BA_ "GenSigStartValue" SG_ 955 Tire_Temp_ILR_Data 253;
BA_ "GenSigStartValueInteger" SG_ 955 Tire_Temp_ILR_Data 253;
BA_ "U_CD542_MY2021_Tx" SG_ 1116 TrlrAidSetup_D2_Rq 1;
BA_ "U_T6_MCA_MY2020_Tx" SG_ 1116 TrlrAidSetup_D2_Rq 1;
BA_ "GenSigSendType" SG_ 1116 TrlrAidSetup_D2_Rq 3;
BA_ "U_CD542_MY2021_Tx" SG_ 1116 TrlrAidEnbl_D2_Rq 1;
BA_ "U_T6_MCA_MY2020_Tx" SG_ 1116 TrlrAidEnbl_D2_Rq 1;
BA_ "GenSigSendType" SG_ 1116 TrlrAidEnbl_D2_Rq 3;
BA_ "U_CD542_MY2021_Tx" SG_ 1116 TlightTest_D_Mnu 1;
BA_ "U_T6_MCA_MY2020_Tx" SG_ 1116 TlightTest_D_Mnu 1;
BA_ "U_U55X_MY2022_Rx" SG_ 1116 TlightTest_D_Mnu 1;
BA_ "ECGUsedRxSignal" SG_ 1116 TlightTest_D_Mnu 1;
BA_ "GenSigSendType" SG_ 1116 TlightTest_D_Mnu 3;
BA_ "U_CD542_MY2021_Tx" SG_ 1116 TrlrTrgtToBmpr_L_Actl 1;
BA_ "U_T6_MCA_MY2020_Tx" SG_ 1116 TrlrTrgtToBmpr_L_Actl 1;
BA_ "U_CD542_MY2021_Tx" SG_ 1116 TrlrTrgtPtrnId_No_Mem 1;
BA_ "U_T6_MCA_MY2020_Tx" SG_ 1116 TrlrTrgtPtrnId_No_Mem 1;
BA_ "U_CD542_MY2021_Tx" SG_ 1116 TrlrRvrseCancl_B_Rq 1;
BA_ "U_T6_MCA_MY2020_Tx" SG_ 1116 TrlrRvrseCancl_B_Rq 1;
BA_ "GenSigSendType" SG_ 1116 TrlrRvrseCancl_B_Rq 3;
BA_ "U_CD542_MY2021_Tx" SG_ 1116 TrlrIdType_D_Stat 1;
BA_ "U_T6_MCA_MY2020_Tx" SG_ 1116 TrlrIdType_D_Stat 1;
BA_ "GenSigSendType" SG_ 1116 TrlrIdType_D_Stat 3;
BA_ "U_CD542_MY2021_Tx" SG_ 1116 TrlrId_No_Actl 1;
BA_ "U_T6_MCA_MY2020_Tx" SG_ 1116 TrlrId_No_Actl 1;
BA_ "U_CD542_MY2021_Tx" SG_ 1116 TrlrBallToBmpr_L_Actl 1;
BA_ "U_T6_MCA_MY2020_Tx" SG_ 1116 TrlrBallToBmpr_L_Actl 1;
BA_ "U_CD542_MY2021_Tx" SG_ 1116 TrlrAxleToBmpr_L_Actl 1;
BA_ "U_T6_MCA_MY2020_Tx" SG_ 1116 TrlrAxleToBmpr_L_Actl 1;
BA_ "U_CD542_MY2021_Tx" SG_ 1116 TrlrAnOffstDir_D_Mem 1;
BA_ "U_T6_MCA_MY2020_Tx" SG_ 1116 TrlrAnOffstDir_D_Mem 1;
BA_ "GenSigSendType" SG_ 1116 TrlrAnOffstDir_D_Mem 3;
BA_ "U_CD542_MY2021_Tx" SG_ 1116 TrlrAnOffst_An_Mem 1;
BA_ "U_T6_MCA_MY2020_Tx" SG_ 1116 TrlrAnOffst_An_Mem 1;
BA_ "U_CD542_MY2021_Tx" SG_ 1116 TrlrTrgtOffst_L_Actl 1;
BA_ "U_T6_MCA_MY2020_Tx" SG_ 1116 TrlrTrgtOffst_L_Actl 1;
BA_ "U_CD542_MY2021_Rx" SG_ 1113 TrlrAnOffstDir_D_Calc_UB 1;
BA_ "U_P702_MY2021_Rx" SG_ 1113 TrlrAnOffstDir_D_Calc_UB 1;
BA_ "U_T6_MCA_MY2020_Rx" SG_ 1113 TrlrAnOffstDir_D_Calc_UB 1;
BA_ "U_CD542_MY2021_Rx" SG_ 1113 TrlrAnOffst_An_Calc_UB 1;
BA_ "U_P702_MY2021_Rx" SG_ 1113 TrlrAnOffst_An_Calc_UB 1;
BA_ "U_T6_MCA_MY2020_Rx" SG_ 1113 TrlrAnOffst_An_Calc_UB 1;
BA_ "U_CD542_MY2021_Rx" SG_ 1113 TrlrAnCalib_B_Complt_UB 1;
BA_ "U_T6_MCA_MY2020_Rx" SG_ 1113 TrlrAnCalib_B_Complt_UB 1;
BA_ "U_CD542_MY2021_Rx" SG_ 1113 TrlrAidTrgtId_No_Actl_UB 1;
BA_ "U_T6_MCA_MY2020_Rx" SG_ 1113 TrlrAidTrgtId_No_Actl_UB 1;
BA_ "U_CD542_MY2021_Rx" SG_ 1113 TrlrAnOffst_An_Calc 1;
BA_ "U_P702_MY2021_Rx" SG_ 1113 TrlrAnOffst_An_Calc 1;
BA_ "U_T6_MCA_MY2020_Rx" SG_ 1113 TrlrAnOffst_An_Calc 1;
BA_ "U_CD542_MY2021_Rx" SG_ 1113 TrlrAnCalib_B_Complt 1;
BA_ "U_T6_MCA_MY2020_Rx" SG_ 1113 TrlrAnCalib_B_Complt 1;
BA_ "U_CD542_MY2021_Rx" SG_ 1113 TrlrAnOffstDir_D_Calc 1;
BA_ "U_P702_MY2021_Rx" SG_ 1113 TrlrAnOffstDir_D_Calc 1;
BA_ "U_T6_MCA_MY2020_Rx" SG_ 1113 TrlrAnOffstDir_D_Calc 1;
BA_ "U_CD542_MY2021_Rx" SG_ 1113 TrlrAidTrgtId_No_Actl 1;
BA_ "U_T6_MCA_MY2020_Rx" SG_ 1113 TrlrAidTrgtId_No_Actl 1;
BA_ "U_CD542_MY2021_Rx" SG_ 1113 immoSecureIdleMode_UB 1;
BA_ "U_T6_MCA_MY2020_Rx" SG_ 1113 immoSecureIdleMode_UB 1;
BA_ "U_CD542_MY2021_Rx" SG_ 1113 immoSecureIdleMode 1;
BA_ "U_T6_MCA_MY2020_Rx" SG_ 1113 immoSecureIdleMode 1;
BA_ "U_CD542_MY2021_Rx" SG_ 1255 BalrRight4Threat_D_Stat 1;
BA_ "U_T6_MCA_MY2020_Rx" SG_ 1255 BalrRight4Threat_D_Stat 1;
BA_ "U_CD542_MY2021_Rx" SG_ 1255 BalrRight4Prev3Y_L_Actl 1;
BA_ "U_T6_MCA_MY2020_Rx" SG_ 1255 BalrRight4Prev3Y_L_Actl 1;
BA_ "GenSigStartValueInteger" SG_ 1255 BalrRight4Prev3Y_L_Actl 64;
BA_ "U_CD542_MY2021_Rx" SG_ 1255 BalrRight4Prev3X_L_Actl 1;
BA_ "U_T6_MCA_MY2020_Rx" SG_ 1255 BalrRight4Prev3X_L_Actl 1;
BA_ "GenSigStartValueInteger" SG_ 1255 BalrRight4Prev3X_L_Actl 64;
BA_ "U_CD542_MY2021_Rx" SG_ 1255 BalrRight4Prev2Y_L_Actl 1;
BA_ "U_T6_MCA_MY2020_Rx" SG_ 1255 BalrRight4Prev2Y_L_Actl 1;
BA_ "GenSigStartValueInteger" SG_ 1255 BalrRight4Prev2Y_L_Actl 64;
BA_ "U_CD542_MY2021_Rx" SG_ 1255 BalrRight4Prev2X_L_Actl 1;
BA_ "U_T6_MCA_MY2020_Rx" SG_ 1255 BalrRight4Prev2X_L_Actl 1;
BA_ "GenSigStartValueInteger" SG_ 1255 BalrRight4Prev2X_L_Actl 64;
BA_ "U_CD542_MY2021_Rx" SG_ 1255 BalrRight4Prev1Y_L_Actl 1;
BA_ "U_T6_MCA_MY2020_Rx" SG_ 1255 BalrRight4Prev1Y_L_Actl 1;
BA_ "GenSigStartValueInteger" SG_ 1255 BalrRight4Prev1Y_L_Actl 64;
BA_ "U_CD542_MY2021_Rx" SG_ 1255 BalrRight4Prev1X_L_Actl 1;
BA_ "U_T6_MCA_MY2020_Rx" SG_ 1255 BalrRight4Prev1X_L_Actl 1;
BA_ "GenSigStartValueInteger" SG_ 1255 BalrRight4Prev1X_L_Actl 64;
BA_ "U_CD542_MY2021_Rx" SG_ 1255 BalrRight4Fast_B_Stat 1;
BA_ "U_T6_MCA_MY2020_Rx" SG_ 1255 BalrRight4Fast_B_Stat 1;
BA_ "U_CD542_MY2021_Rx" SG_ 1255 BalrRight4Dsply_B_Stat 1;
BA_ "U_T6_MCA_MY2020_Rx" SG_ 1255 BalrRight4Dsply_B_Stat 1;
BA_ "U_CD542_MY2021_Rx" SG_ 1255 BalrRight4CurntY_L_Actl 1;
BA_ "U_T6_MCA_MY2020_Rx" SG_ 1255 BalrRight4CurntY_L_Actl 1;
BA_ "GenSigStartValueInteger" SG_ 1255 BalrRight4CurntY_L_Actl 64;
BA_ "U_CD542_MY2021_Rx" SG_ 1255 BalrRight4CurntX_L_Actl 1;
BA_ "U_T6_MCA_MY2020_Rx" SG_ 1255 BalrRight4CurntX_L_Actl 1;
BA_ "GenSigStartValueInteger" SG_ 1255 BalrRight4CurntX_L_Actl 64;
BA_ "U_CD542_MY2021_Rx" SG_ 1254 BalrRight3Threat_D_Stat 1;
BA_ "U_T6_MCA_MY2020_Rx" SG_ 1254 BalrRight3Threat_D_Stat 1;
BA_ "U_CD542_MY2021_Rx" SG_ 1254 BalrRight3Prev3Y_L_Actl 1;
BA_ "U_T6_MCA_MY2020_Rx" SG_ 1254 BalrRight3Prev3Y_L_Actl 1;
BA_ "GenSigStartValueInteger" SG_ 1254 BalrRight3Prev3Y_L_Actl 64;
BA_ "U_CD542_MY2021_Rx" SG_ 1254 BalrRight3Prev3X_L_Actl 1;
BA_ "U_T6_MCA_MY2020_Rx" SG_ 1254 BalrRight3Prev3X_L_Actl 1;
BA_ "GenSigStartValueInteger" SG_ 1254 BalrRight3Prev3X_L_Actl 64;
BA_ "U_CD542_MY2021_Rx" SG_ 1254 BalrRight3Prev2Y_L_Actl 1;
BA_ "U_T6_MCA_MY2020_Rx" SG_ 1254 BalrRight3Prev2Y_L_Actl 1;
BA_ "GenSigStartValueInteger" SG_ 1254 BalrRight3Prev2Y_L_Actl 64;
BA_ "U_CD542_MY2021_Rx" SG_ 1254 BalrRight3Prev2X_L_Actl 1;
BA_ "U_T6_MCA_MY2020_Rx" SG_ 1254 BalrRight3Prev2X_L_Actl 1;
BA_ "GenSigStartValueInteger" SG_ 1254 BalrRight3Prev2X_L_Actl 64;
BA_ "U_CD542_MY2021_Rx" SG_ 1254 BalrRight3Prev1Y_L_Actl 1;
BA_ "U_T6_MCA_MY2020_Rx" SG_ 1254 BalrRight3Prev1Y_L_Actl 1;
BA_ "GenSigStartValueInteger" SG_ 1254 BalrRight3Prev1Y_L_Actl 64;
BA_ "U_CD542_MY2021_Rx" SG_ 1254 BalrRight3Prev1X_L_Actl 1;
BA_ "U_T6_MCA_MY2020_Rx" SG_ 1254 BalrRight3Prev1X_L_Actl 1;
BA_ "GenSigStartValueInteger" SG_ 1254 BalrRight3Prev1X_L_Actl 64;
BA_ "U_CD542_MY2021_Rx" SG_ 1254 BalrRight3Fast_B_Stat 1;
BA_ "U_T6_MCA_MY2020_Rx" SG_ 1254 BalrRight3Fast_B_Stat 1;
BA_ "U_CD542_MY2021_Rx" SG_ 1254 BalrRight3Dsply_B_Stat 1;
BA_ "U_T6_MCA_MY2020_Rx" SG_ 1254 BalrRight3Dsply_B_Stat 1;
BA_ "U_CD542_MY2021_Rx" SG_ 1254 BalrRight3CurntY_L_Actl 1;
BA_ "U_T6_MCA_MY2020_Rx" SG_ 1254 BalrRight3CurntY_L_Actl 1;
BA_ "GenSigStartValueInteger" SG_ 1254 BalrRight3CurntY_L_Actl 64;
BA_ "U_CD542_MY2021_Rx" SG_ 1254 BalrRight3CurntX_L_Actl 1;
BA_ "U_T6_MCA_MY2020_Rx" SG_ 1254 BalrRight3CurntX_L_Actl 1;
BA_ "GenSigStartValueInteger" SG_ 1254 BalrRight3CurntX_L_Actl 64;
BA_ "U_CD542_MY2021_Rx" SG_ 1253 BalrRight2Prev3Y_L_Actl 1;
BA_ "U_T6_MCA_MY2020_Rx" SG_ 1253 BalrRight2Prev3Y_L_Actl 1;
BA_ "GenSigStartValueInteger" SG_ 1253 BalrRight2Prev3Y_L_Actl 64;
BA_ "U_CD542_MY2021_Rx" SG_ 1253 BalrRight2Prev3X_L_Actl 1;
BA_ "U_T6_MCA_MY2020_Rx" SG_ 1253 BalrRight2Prev3X_L_Actl 1;
BA_ "GenSigStartValueInteger" SG_ 1253 BalrRight2Prev3X_L_Actl 64;
BA_ "U_CD542_MY2021_Rx" SG_ 1253 BalrRight2Threat_D_Stat 1;
BA_ "U_T6_MCA_MY2020_Rx" SG_ 1253 BalrRight2Threat_D_Stat 1;
BA_ "U_CD542_MY2021_Rx" SG_ 1253 BalrRight2Prev2Y_L_Actl 1;
BA_ "U_T6_MCA_MY2020_Rx" SG_ 1253 BalrRight2Prev2Y_L_Actl 1;
BA_ "GenSigStartValueInteger" SG_ 1253 BalrRight2Prev2Y_L_Actl 64;
BA_ "U_CD542_MY2021_Rx" SG_ 1253 BalrRight2Prev2X_L_Actl 1;
BA_ "U_T6_MCA_MY2020_Rx" SG_ 1253 BalrRight2Prev2X_L_Actl 1;
BA_ "GenSigStartValueInteger" SG_ 1253 BalrRight2Prev2X_L_Actl 64;
BA_ "U_CD542_MY2021_Rx" SG_ 1253 BalrRight2Prev1Y_L_Actl 1;
BA_ "U_T6_MCA_MY2020_Rx" SG_ 1253 BalrRight2Prev1Y_L_Actl 1;
BA_ "GenSigStartValueInteger" SG_ 1253 BalrRight2Prev1Y_L_Actl 64;
BA_ "U_CD542_MY2021_Rx" SG_ 1253 BalrRight2Prev1X_L_Actl 1;
BA_ "U_T6_MCA_MY2020_Rx" SG_ 1253 BalrRight2Prev1X_L_Actl 1;
BA_ "GenSigStartValueInteger" SG_ 1253 BalrRight2Prev1X_L_Actl 64;
BA_ "U_CD542_MY2021_Rx" SG_ 1253 BalrRight2Fast_B_Stat 1;
BA_ "U_T6_MCA_MY2020_Rx" SG_ 1253 BalrRight2Fast_B_Stat 1;
BA_ "U_CD542_MY2021_Rx" SG_ 1253 BalrRight2Dsply_B_Stat 1;
BA_ "U_T6_MCA_MY2020_Rx" SG_ 1253 BalrRight2Dsply_B_Stat 1;
BA_ "U_CD542_MY2021_Rx" SG_ 1253 BalrRight2CurntY_L_Actl 1;
BA_ "U_T6_MCA_MY2020_Rx" SG_ 1253 BalrRight2CurntY_L_Actl 1;
BA_ "GenSigStartValueInteger" SG_ 1253 BalrRight2CurntY_L_Actl 64;
BA_ "U_CD542_MY2021_Rx" SG_ 1253 BalrRight2CurntX_L_Actl 1;
BA_ "U_T6_MCA_MY2020_Rx" SG_ 1253 BalrRight2CurntX_L_Actl 1;
BA_ "GenSigStartValueInteger" SG_ 1253 BalrRight2CurntX_L_Actl 64;
BA_ "U_CD542_MY2021_Rx" SG_ 1252 BalrRight1Prev3Y_L_Actl 1;
BA_ "U_T6_MCA_MY2020_Rx" SG_ 1252 BalrRight1Prev3Y_L_Actl 1;
BA_ "GenSigStartValueInteger" SG_ 1252 BalrRight1Prev3Y_L_Actl 64;
BA_ "U_CD542_MY2021_Rx" SG_ 1252 BalrRight1Prev3X_L_Actl 1;
BA_ "U_T6_MCA_MY2020_Rx" SG_ 1252 BalrRight1Prev3X_L_Actl 1;
BA_ "GenSigStartValueInteger" SG_ 1252 BalrRight1Prev3X_L_Actl 64;
BA_ "U_CD542_MY2021_Rx" SG_ 1252 BalrRight1Threat_D_Stat 1;
BA_ "U_T6_MCA_MY2020_Rx" SG_ 1252 BalrRight1Threat_D_Stat 1;
BA_ "U_CD542_MY2021_Rx" SG_ 1252 BalrRight1Prev2Y_L_Actl 1;
BA_ "U_T6_MCA_MY2020_Rx" SG_ 1252 BalrRight1Prev2Y_L_Actl 1;
BA_ "GenSigStartValueInteger" SG_ 1252 BalrRight1Prev2Y_L_Actl 64;
BA_ "U_CD542_MY2021_Rx" SG_ 1252 BalrRight1Prev2X_L_Actl 1;
BA_ "U_T6_MCA_MY2020_Rx" SG_ 1252 BalrRight1Prev2X_L_Actl 1;
BA_ "GenSigStartValueInteger" SG_ 1252 BalrRight1Prev2X_L_Actl 64;
BA_ "U_CD542_MY2021_Rx" SG_ 1252 BalrRight1Prev1Y_L_Actl 1;
BA_ "U_T6_MCA_MY2020_Rx" SG_ 1252 BalrRight1Prev1Y_L_Actl 1;
BA_ "GenSigStartValueInteger" SG_ 1252 BalrRight1Prev1Y_L_Actl 64;
BA_ "U_CD542_MY2021_Rx" SG_ 1252 BalrRight1Prev1X_L_Actl 1;
BA_ "U_T6_MCA_MY2020_Rx" SG_ 1252 BalrRight1Prev1X_L_Actl 1;
BA_ "GenSigStartValueInteger" SG_ 1252 BalrRight1Prev1X_L_Actl 64;
BA_ "U_CD542_MY2021_Rx" SG_ 1252 BalrRight1Fast_B_Stat 1;
BA_ "U_T6_MCA_MY2020_Rx" SG_ 1252 BalrRight1Fast_B_Stat 1;
BA_ "U_CD542_MY2021_Rx" SG_ 1252 BalrRight1Dsply_B_Stat 1;
BA_ "U_T6_MCA_MY2020_Rx" SG_ 1252 BalrRight1Dsply_B_Stat 1;
BA_ "U_CD542_MY2021_Rx" SG_ 1252 BalrRight1CurntY_L_Actl 1;
BA_ "U_T6_MCA_MY2020_Rx" SG_ 1252 BalrRight1CurntY_L_Actl 1;
BA_ "GenSigStartValueInteger" SG_ 1252 BalrRight1CurntY_L_Actl 64;
BA_ "U_CD542_MY2021_Rx" SG_ 1252 BalrRight1CurntX_L_Actl 1;
BA_ "U_T6_MCA_MY2020_Rx" SG_ 1252 BalrRight1CurntX_L_Actl 1;
BA_ "GenSigStartValueInteger" SG_ 1252 BalrRight1CurntX_L_Actl 64;
BA_ "U_CD542_MY2021_Rx" SG_ 1251 BalrLeft4Threat_D_Stat 1;
BA_ "U_T6_MCA_MY2020_Rx" SG_ 1251 BalrLeft4Threat_D_Stat 1;
BA_ "U_CD542_MY2021_Rx" SG_ 1251 BalrLeft4Prev3Y_L_Actl 1;
BA_ "U_T6_MCA_MY2020_Rx" SG_ 1251 BalrLeft4Prev3Y_L_Actl 1;
BA_ "GenSigStartValueInteger" SG_ 1251 BalrLeft4Prev3Y_L_Actl 64;
BA_ "U_CD542_MY2021_Rx" SG_ 1251 BalrLeft4Prev3X_L_Actl 1;
BA_ "U_T6_MCA_MY2020_Rx" SG_ 1251 BalrLeft4Prev3X_L_Actl 1;
BA_ "GenSigStartValueInteger" SG_ 1251 BalrLeft4Prev3X_L_Actl 64;
BA_ "U_CD542_MY2021_Rx" SG_ 1251 BalrLeft4Prev2Y_L_Actl 1;
BA_ "U_T6_MCA_MY2020_Rx" SG_ 1251 BalrLeft4Prev2Y_L_Actl 1;
BA_ "GenSigStartValueInteger" SG_ 1251 BalrLeft4Prev2Y_L_Actl 64;
BA_ "U_CD542_MY2021_Rx" SG_ 1251 BalrLeft4Prev2X_L_Actl 1;
BA_ "U_T6_MCA_MY2020_Rx" SG_ 1251 BalrLeft4Prev2X_L_Actl 1;
BA_ "GenSigStartValueInteger" SG_ 1251 BalrLeft4Prev2X_L_Actl 64;
BA_ "U_CD542_MY2021_Rx" SG_ 1251 BalrLeft4Prev1Y_L_Actl 1;
BA_ "U_T6_MCA_MY2020_Rx" SG_ 1251 BalrLeft4Prev1Y_L_Actl 1;
BA_ "GenSigStartValueInteger" SG_ 1251 BalrLeft4Prev1Y_L_Actl 64;
BA_ "U_CD542_MY2021_Rx" SG_ 1251 BalrLeft4Prev1X_L_Actl 1;
BA_ "U_T6_MCA_MY2020_Rx" SG_ 1251 BalrLeft4Prev1X_L_Actl 1;
BA_ "GenSigStartValueInteger" SG_ 1251 BalrLeft4Prev1X_L_Actl 64;
BA_ "U_CD542_MY2021_Rx" SG_ 1251 BalrLeft4Fast_B_Stat 1;
BA_ "U_T6_MCA_MY2020_Rx" SG_ 1251 BalrLeft4Fast_B_Stat 1;
BA_ "U_CD542_MY2021_Rx" SG_ 1251 BalrLeft4Dsply_B_Stat 1;
BA_ "U_T6_MCA_MY2020_Rx" SG_ 1251 BalrLeft4Dsply_B_Stat 1;
BA_ "U_CD542_MY2021_Rx" SG_ 1251 BalrLeft4CurntY_L_Actl 1;
BA_ "U_T6_MCA_MY2020_Rx" SG_ 1251 BalrLeft4CurntY_L_Actl 1;
BA_ "GenSigStartValueInteger" SG_ 1251 BalrLeft4CurntY_L_Actl 64;
BA_ "U_CD542_MY2021_Rx" SG_ 1251 BalrLeft4CurntX_L_Actl 1;
BA_ "U_T6_MCA_MY2020_Rx" SG_ 1251 BalrLeft4CurntX_L_Actl 1;
BA_ "GenSigStartValueInteger" SG_ 1251 BalrLeft4CurntX_L_Actl 64;
BA_ "U_CD542_MY2021_Rx" SG_ 1250 BalrLeft3Threat_D_Stat 1;
BA_ "U_T6_MCA_MY2020_Rx" SG_ 1250 BalrLeft3Threat_D_Stat 1;
BA_ "U_CD542_MY2021_Rx" SG_ 1250 BalrLeft3Prev3Y_L_Actl 1;
BA_ "U_T6_MCA_MY2020_Rx" SG_ 1250 BalrLeft3Prev3Y_L_Actl 1;
BA_ "GenSigStartValueInteger" SG_ 1250 BalrLeft3Prev3Y_L_Actl 64;
BA_ "U_CD542_MY2021_Rx" SG_ 1250 BalrLeft3Prev3X_L_Actl 1;
BA_ "U_T6_MCA_MY2020_Rx" SG_ 1250 BalrLeft3Prev3X_L_Actl 1;
BA_ "GenSigStartValueInteger" SG_ 1250 BalrLeft3Prev3X_L_Actl 64;
BA_ "U_CD542_MY2021_Rx" SG_ 1250 BalrLeft3Prev2Y_L_Actl 1;
BA_ "U_T6_MCA_MY2020_Rx" SG_ 1250 BalrLeft3Prev2Y_L_Actl 1;
BA_ "GenSigStartValueInteger" SG_ 1250 BalrLeft3Prev2Y_L_Actl 64;
BA_ "U_CD542_MY2021_Rx" SG_ 1250 BalrLeft3Prev2X_L_Actl 1;
BA_ "U_T6_MCA_MY2020_Rx" SG_ 1250 BalrLeft3Prev2X_L_Actl 1;
BA_ "GenSigStartValueInteger" SG_ 1250 BalrLeft3Prev2X_L_Actl 64;
BA_ "U_CD542_MY2021_Rx" SG_ 1250 BalrLeft3Prev1Y_L_Actl 1;
BA_ "U_T6_MCA_MY2020_Rx" SG_ 1250 BalrLeft3Prev1Y_L_Actl 1;
BA_ "GenSigStartValueInteger" SG_ 1250 BalrLeft3Prev1Y_L_Actl 64;
BA_ "U_CD542_MY2021_Rx" SG_ 1250 BalrLeft3Prev1X_L_Actl 1;
BA_ "U_T6_MCA_MY2020_Rx" SG_ 1250 BalrLeft3Prev1X_L_Actl 1;
BA_ "GenSigStartValueInteger" SG_ 1250 BalrLeft3Prev1X_L_Actl 64;
BA_ "U_CD542_MY2021_Rx" SG_ 1250 BalrLeft3Fast_B_Stat 1;
BA_ "U_T6_MCA_MY2020_Rx" SG_ 1250 BalrLeft3Fast_B_Stat 1;
BA_ "U_CD542_MY2021_Rx" SG_ 1250 BalrLeft3Dsply_B_Stat 1;
BA_ "U_T6_MCA_MY2020_Rx" SG_ 1250 BalrLeft3Dsply_B_Stat 1;
BA_ "U_CD542_MY2021_Rx" SG_ 1250 BalrLeft3CurntY_L_Actl 1;
BA_ "U_T6_MCA_MY2020_Rx" SG_ 1250 BalrLeft3CurntY_L_Actl 1;
BA_ "GenSigStartValueInteger" SG_ 1250 BalrLeft3CurntY_L_Actl 64;
BA_ "U_CD542_MY2021_Rx" SG_ 1250 BalrLeft3CurntX_L_Actl 1;
BA_ "U_T6_MCA_MY2020_Rx" SG_ 1250 BalrLeft3CurntX_L_Actl 1;
BA_ "GenSigStartValueInteger" SG_ 1250 BalrLeft3CurntX_L_Actl 64;
BA_ "U_CD542_MY2021_Rx" SG_ 1249 BalrLeft2Prev3Y_L_Actl 1;
BA_ "U_T6_MCA_MY2020_Rx" SG_ 1249 BalrLeft2Prev3Y_L_Actl 1;
BA_ "GenSigStartValueInteger" SG_ 1249 BalrLeft2Prev3Y_L_Actl 64;
BA_ "U_CD542_MY2021_Rx" SG_ 1249 BalrLeft2Prev3X_L_Actl 1;
BA_ "U_T6_MCA_MY2020_Rx" SG_ 1249 BalrLeft2Prev3X_L_Actl 1;
BA_ "GenSigStartValueInteger" SG_ 1249 BalrLeft2Prev3X_L_Actl 64;
BA_ "U_CD542_MY2021_Rx" SG_ 1249 BalrLeft2Threat_D_Stat 1;
BA_ "U_T6_MCA_MY2020_Rx" SG_ 1249 BalrLeft2Threat_D_Stat 1;
BA_ "U_CD542_MY2021_Rx" SG_ 1249 BalrLeft2Prev2Y_L_Actl 1;
BA_ "U_T6_MCA_MY2020_Rx" SG_ 1249 BalrLeft2Prev2Y_L_Actl 1;
BA_ "GenSigStartValueInteger" SG_ 1249 BalrLeft2Prev2Y_L_Actl 64;
BA_ "U_CD542_MY2021_Rx" SG_ 1249 BalrLeft2Prev2X_L_Actl 1;
BA_ "U_T6_MCA_MY2020_Rx" SG_ 1249 BalrLeft2Prev2X_L_Actl 1;
BA_ "GenSigStartValueInteger" SG_ 1249 BalrLeft2Prev2X_L_Actl 64;
BA_ "U_CD542_MY2021_Rx" SG_ 1249 BalrLeft2Prev1Y_L_Actl 1;
BA_ "U_T6_MCA_MY2020_Rx" SG_ 1249 BalrLeft2Prev1Y_L_Actl 1;
BA_ "GenSigStartValueInteger" SG_ 1249 BalrLeft2Prev1Y_L_Actl 64;
BA_ "U_CD542_MY2021_Rx" SG_ 1249 BalrLeft2Prev1X_L_Actl 1;
BA_ "U_T6_MCA_MY2020_Rx" SG_ 1249 BalrLeft2Prev1X_L_Actl 1;
BA_ "GenSigStartValueInteger" SG_ 1249 BalrLeft2Prev1X_L_Actl 64;
BA_ "U_CD542_MY2021_Rx" SG_ 1249 BalrLeft2Fast_B_Stat 1;
BA_ "U_T6_MCA_MY2020_Rx" SG_ 1249 BalrLeft2Fast_B_Stat 1;
BA_ "U_CD542_MY2021_Rx" SG_ 1249 BalrLeft2Dsply_B_Stat 1;
BA_ "U_T6_MCA_MY2020_Rx" SG_ 1249 BalrLeft2Dsply_B_Stat 1;
BA_ "U_CD542_MY2021_Rx" SG_ 1249 BalrLeft2CurntY_L_Actl 1;
BA_ "U_T6_MCA_MY2020_Rx" SG_ 1249 BalrLeft2CurntY_L_Actl 1;
BA_ "GenSigStartValueInteger" SG_ 1249 BalrLeft2CurntY_L_Actl 64;
BA_ "U_CD542_MY2021_Rx" SG_ 1249 BalrLeft2CurntX_L_Actl 1;
BA_ "U_T6_MCA_MY2020_Rx" SG_ 1249 BalrLeft2CurntX_L_Actl 1;
BA_ "GenSigStartValueInteger" SG_ 1249 BalrLeft2CurntX_L_Actl 64;
BA_ "U_CD542_MY2021_Rx" SG_ 1248 BalrLeft1Threat_D_Stat 1;
BA_ "U_T6_MCA_MY2020_Rx" SG_ 1248 BalrLeft1Threat_D_Stat 1;
BA_ "U_CD542_MY2021_Rx" SG_ 1248 BalrLeft1Prev3Y_L_Actl 1;
BA_ "U_T6_MCA_MY2020_Rx" SG_ 1248 BalrLeft1Prev3Y_L_Actl 1;
BA_ "GenSigStartValueInteger" SG_ 1248 BalrLeft1Prev3Y_L_Actl 64;
BA_ "U_CD542_MY2021_Rx" SG_ 1248 BalrLeft1Prev3X_L_Actl 1;
BA_ "U_T6_MCA_MY2020_Rx" SG_ 1248 BalrLeft1Prev3X_L_Actl 1;
BA_ "GenSigStartValueInteger" SG_ 1248 BalrLeft1Prev3X_L_Actl 64;
BA_ "U_CD542_MY2021_Rx" SG_ 1248 BalrLeft1Prev2Y_L_Actl 1;
BA_ "U_T6_MCA_MY2020_Rx" SG_ 1248 BalrLeft1Prev2Y_L_Actl 1;
BA_ "GenSigStartValueInteger" SG_ 1248 BalrLeft1Prev2Y_L_Actl 64;
BA_ "U_CD542_MY2021_Rx" SG_ 1248 BalrLeft1Prev2X_L_Actl 1;
BA_ "U_T6_MCA_MY2020_Rx" SG_ 1248 BalrLeft1Prev2X_L_Actl 1;
BA_ "GenSigStartValueInteger" SG_ 1248 BalrLeft1Prev2X_L_Actl 64;
BA_ "U_CD542_MY2021_Rx" SG_ 1248 BalrLeft1Prev1Y_L_Actl 1;
BA_ "U_T6_MCA_MY2020_Rx" SG_ 1248 BalrLeft1Prev1Y_L_Actl 1;
BA_ "GenSigStartValueInteger" SG_ 1248 BalrLeft1Prev1Y_L_Actl 64;
BA_ "U_CD542_MY2021_Rx" SG_ 1248 BalrLeft1Prev1X_L_Actl 1;
BA_ "U_T6_MCA_MY2020_Rx" SG_ 1248 BalrLeft1Prev1X_L_Actl 1;
BA_ "GenSigStartValueInteger" SG_ 1248 BalrLeft1Prev1X_L_Actl 64;
BA_ "U_CD542_MY2021_Rx" SG_ 1248 BalrLeft1Fast_B_Stat 1;
BA_ "U_T6_MCA_MY2020_Rx" SG_ 1248 BalrLeft1Fast_B_Stat 1;
BA_ "U_CD542_MY2021_Rx" SG_ 1248 BalrLeft1Dsply_B_Stat 1;
BA_ "U_T6_MCA_MY2020_Rx" SG_ 1248 BalrLeft1Dsply_B_Stat 1;
BA_ "U_CD542_MY2021_Rx" SG_ 1248 BalrLeft1CurntY_L_Actl 1;
BA_ "U_T6_MCA_MY2020_Rx" SG_ 1248 BalrLeft1CurntY_L_Actl 1;
BA_ "GenSigStartValueInteger" SG_ 1248 BalrLeft1CurntY_L_Actl 64;
BA_ "U_CD542_MY2021_Rx" SG_ 1248 BalrLeft1CurntX_L_Actl 1;
BA_ "U_T6_MCA_MY2020_Rx" SG_ 1248 BalrLeft1CurntX_L_Actl 1;
BA_ "GenSigStartValueInteger" SG_ 1248 BalrLeft1CurntX_L_Actl 64;
BA_ "U_CD542_MY2021_Rx" SG_ 1256 BalrMdeRight_D_Stat_UB 1;
BA_ "U_T6_MCA_MY2020_Rx" SG_ 1256 BalrMdeRight_D_Stat_UB 1;
BA_ "U_CD542_MY2021_Rx" SG_ 1256 BalrMdeSelRight_B_Stat_UB 1;
BA_ "U_T6_MCA_MY2020_Rx" SG_ 1256 BalrMdeSelRight_B_Stat_UB 1;
BA_ "U_CD542_MY2021_Rx" SG_ 1256 BalrRight_D_Stat_UB 1;
BA_ "U_T6_MCA_MY2020_Rx" SG_ 1256 BalrRight_D_Stat_UB 1;
BA_ "U_CD542_MY2021_Rx" SG_ 1256 BalrLckRight_B_Stat_UB 1;
BA_ "U_T6_MCA_MY2020_Rx" SG_ 1256 BalrLckRight_B_Stat_UB 1;
BA_ "U_CD542_MY2021_Rx" SG_ 1256 BalrChimeRight_D_Rq_UB 1;
BA_ "U_T6_MCA_MY2020_Rx" SG_ 1256 BalrChimeRight_D_Rq_UB 1;
BA_ "U_CD542_MY2021_Rx" SG_ 1256 BalrSnsRight_D_Falt_UB 1;
BA_ "U_T6_MCA_MY2020_Rx" SG_ 1256 BalrSnsRight_D_Falt_UB 1;
BA_ "U_CD542_MY2021_Rx" SG_ 1256 BalrWndwRight_B_Stat_UB 1;
BA_ "U_T6_MCA_MY2020_Rx" SG_ 1256 BalrWndwRight_B_Stat_UB 1;
BA_ "U_CD542_MY2021_Rx" SG_ 1256 BalrLckRight_B_Stat 1;
BA_ "U_T6_MCA_MY2020_Rx" SG_ 1256 BalrLckRight_B_Stat 1;
BA_ "GenSigSendType" SG_ 1256 BalrLckRight_B_Stat 3;
BA_ "U_CD542_MY2021_Rx" SG_ 1256 BalrWndwRight_B_Stat 1;
BA_ "U_T6_MCA_MY2020_Rx" SG_ 1256 BalrWndwRight_B_Stat 1;
BA_ "GenSigSendType" SG_ 1256 BalrWndwRight_B_Stat 3;
BA_ "U_CD542_MY2021_Rx" SG_ 1256 BalrMdeSelRight_B_Stat 1;
BA_ "U_T6_MCA_MY2020_Rx" SG_ 1256 BalrMdeSelRight_B_Stat 1;
BA_ "GenSigSendType" SG_ 1256 BalrMdeSelRight_B_Stat 3;
BA_ "U_CD542_MY2021_Rx" SG_ 1256 BalrSnsRight_D_Falt 1;
BA_ "U_T6_MCA_MY2020_Rx" SG_ 1256 BalrSnsRight_D_Falt 1;
BA_ "GenSigSendType" SG_ 1256 BalrSnsRight_D_Falt 3;
BA_ "U_CD542_MY2021_Rx" SG_ 1256 BalrChimeRight_D_Rq 1;
BA_ "U_T6_MCA_MY2020_Rx" SG_ 1256 BalrChimeRight_D_Rq 1;
BA_ "GenSigSendType" SG_ 1256 BalrChimeRight_D_Rq 3;
BA_ "U_CD542_MY2021_Rx" SG_ 1256 BalrMdeRight_D_Stat 1;
BA_ "U_T6_MCA_MY2020_Rx" SG_ 1256 BalrMdeRight_D_Stat 1;
BA_ "GenSigSendType" SG_ 1256 BalrMdeRight_D_Stat 3;
BA_ "GenSigStartValue" SG_ 1256 BalrMdeRight_D_Stat 1;
BA_ "GenSigStartValueInteger" SG_ 1256 BalrMdeRight_D_Stat 1;
BA_ "U_CD542_MY2021_Rx" SG_ 1256 BalrRight_D_Stat 1;
BA_ "U_T6_MCA_MY2020_Rx" SG_ 1256 BalrRight_D_Stat 1;
BA_ "GenSigSendType" SG_ 1256 BalrRight_D_Stat 3;
BA_ "GenSigStartValue" SG_ 1256 BalrRight_D_Stat 2;
BA_ "GenSigStartValueInteger" SG_ 1256 BalrRight_D_Stat 2;
BA_ "U_CD542_MY2021_Rx" SG_ 1256 BalrWndwLeft_B_Stat_UB 1;
BA_ "U_T6_MCA_MY2020_Rx" SG_ 1256 BalrWndwLeft_B_Stat_UB 1;
BA_ "U_CD542_MY2021_Rx" SG_ 1256 BalrSnsLeft_D_Falt_UB 1;
BA_ "U_T6_MCA_MY2020_Rx" SG_ 1256 BalrSnsLeft_D_Falt_UB 1;
BA_ "U_CD542_MY2021_Rx" SG_ 1256 BalrMdeSelLeft_B_Stat_UB 1;
BA_ "U_T6_MCA_MY2020_Rx" SG_ 1256 BalrMdeSelLeft_B_Stat_UB 1;
BA_ "U_CD542_MY2021_Rx" SG_ 1256 BalrMdeLeft_D_Stat_UB 1;
BA_ "U_T6_MCA_MY2020_Rx" SG_ 1256 BalrMdeLeft_D_Stat_UB 1;
BA_ "U_CD542_MY2021_Rx" SG_ 1256 BalrLeft_D_Stat_UB 1;
BA_ "U_T6_MCA_MY2020_Rx" SG_ 1256 BalrLeft_D_Stat_UB 1;
BA_ "U_CD542_MY2021_Rx" SG_ 1256 BalrLckLeft_B_Stat_UB 1;
BA_ "U_T6_MCA_MY2020_Rx" SG_ 1256 BalrLckLeft_B_Stat_UB 1;
BA_ "U_CD542_MY2021_Rx" SG_ 1256 BalrChimeLeft_D_Rq_UB 1;
BA_ "U_T6_MCA_MY2020_Rx" SG_ 1256 BalrChimeLeft_D_Rq_UB 1;
BA_ "U_CD542_MY2021_Rx" SG_ 1256 BalrLeft_D_Stat 1;
BA_ "U_T6_MCA_MY2020_Rx" SG_ 1256 BalrLeft_D_Stat 1;
BA_ "GenSigSendType" SG_ 1256 BalrLeft_D_Stat 3;
BA_ "GenSigStartValue" SG_ 1256 BalrLeft_D_Stat 2;
BA_ "GenSigStartValueInteger" SG_ 1256 BalrLeft_D_Stat 2;
BA_ "U_CD542_MY2021_Rx" SG_ 1256 BalrMdeSelLeft_B_Stat 1;
BA_ "U_T6_MCA_MY2020_Rx" SG_ 1256 BalrMdeSelLeft_B_Stat 1;
BA_ "GenSigSendType" SG_ 1256 BalrMdeSelLeft_B_Stat 3;
BA_ "U_CD542_MY2021_Rx" SG_ 1256 BalrLckLeft_B_Stat 1;
BA_ "U_T6_MCA_MY2020_Rx" SG_ 1256 BalrLckLeft_B_Stat 1;
BA_ "GenSigSendType" SG_ 1256 BalrLckLeft_B_Stat 3;
BA_ "U_CD542_MY2021_Rx" SG_ 1256 BalrWndwLeft_B_Stat 1;
BA_ "U_T6_MCA_MY2020_Rx" SG_ 1256 BalrWndwLeft_B_Stat 1;
BA_ "GenSigSendType" SG_ 1256 BalrWndwLeft_B_Stat 3;
BA_ "U_CD542_MY2021_Rx" SG_ 1256 BalrMdeLeft_D_Stat 1;
BA_ "U_T6_MCA_MY2020_Rx" SG_ 1256 BalrMdeLeft_D_Stat 1;
BA_ "GenSigSendType" SG_ 1256 BalrMdeLeft_D_Stat 3;
BA_ "GenSigStartValue" SG_ 1256 BalrMdeLeft_D_Stat 1;
BA_ "GenSigStartValueInteger" SG_ 1256 BalrMdeLeft_D_Stat 1;
BA_ "U_CD542_MY2021_Rx" SG_ 1256 BalrSnsLeft_D_Falt 1;
BA_ "U_T6_MCA_MY2020_Rx" SG_ 1256 BalrSnsLeft_D_Falt 1;
BA_ "GenSigSendType" SG_ 1256 BalrSnsLeft_D_Falt 3;
BA_ "U_CD542_MY2021_Rx" SG_ 1256 BalrChimeLeft_D_Rq 1;
BA_ "U_T6_MCA_MY2020_Rx" SG_ 1256 BalrChimeLeft_D_Rq 1;
BA_ "GenSigSendType" SG_ 1256 BalrChimeLeft_D_Rq 3;
BA_ "GenSigSendType" SG_ 1256 WakeAlarm2_D_Stat 3;
BA_ "GenSigStartValue" SG_ 1256 WakeAlarm2_D_Stat 3;
BA_ "GenSigStartValueInteger" SG_ 1256 WakeAlarm2_D_Stat 3;
BA_ "U_CD542_MY2021_Tx" SG_ 529 OnbChrgToPcWknd_D_Actl 1;
BA_ "U_T6_MCA_MY2020_Tx" SG_ 529 OnbChrgToPcWknd_D_Actl 1;
BA_ "U_P702_MY2021_Tx" SG_ 529 OnbChrgToPcWknd_D_Actl 1;
BA_ "U_CD542_MY2021_Tx" SG_ 529 OnbChrgToPcWkdy_D_Actl 1;
BA_ "U_T6_MCA_MY2020_Tx" SG_ 529 OnbChrgToPcWkdy_D_Actl 1;
BA_ "U_P702_MY2021_Tx" SG_ 529 OnbChrgToPcWkdy_D_Actl 1;
BA_ "U_CD542_MY2021_Tx" SG_ 529 OnbChrgSetNow_D_Rq 1;
BA_ "U_T6_MCA_MY2020_Tx" SG_ 529 OnbChrgSetNow_D_Rq 1;
BA_ "U_P702_MY2021_Tx" SG_ 529 OnbChrgSetNow_D_Rq 1;
BA_ "U_CD542_MY2021_Tx" SG_ 529 OnbChrgSetDelete_B_Rq 1;
BA_ "U_T6_MCA_MY2020_Tx" SG_ 529 OnbChrgSetDelete_B_Rq 1;
BA_ "U_P702_MY2021_Tx" SG_ 529 OnbChrgSetDelete_B_Rq 1;
BA_ "U_CD542_MY2021_Tx" SG_ 529 OnbChrgPrflWknd_No_Rq 1;
BA_ "U_T6_MCA_MY2020_Tx" SG_ 529 OnbChrgPrflWknd_No_Rq 1;
BA_ "U_P702_MY2021_Tx" SG_ 529 OnbChrgPrflWknd_No_Rq 1;
BA_ "U_CD542_MY2021_Tx" SG_ 529 OnbChrgPrflWkdy_No_Rq 1;
BA_ "U_T6_MCA_MY2020_Tx" SG_ 529 OnbChrgPrflWkdy_No_Rq 1;
BA_ "U_P702_MY2021_Tx" SG_ 529 OnbChrgPrflWkdy_No_Rq 1;
BA_ "U_CD542_MY2021_Tx" SG_ 529 OnbChrgPrflUpdate_B_Rq 1;
BA_ "U_T6_MCA_MY2020_Tx" SG_ 529 OnbChrgPrflUpdate_B_Rq 1;
BA_ "U_P702_MY2021_Tx" SG_ 529 OnbChrgPrflUpdate_B_Rq 1;
BA_ "U_U55X_MY2022_Rx" SG_ 529 OnbChrgPrflUpdate_B_Rq 1;
BA_ "ECGUsedRxSignal" SG_ 529 OnbChrgPrflUpdate_B_Rq 1;
BA_ "U_T6_MCA_MY2020_Rx" SG_ 529 OnbChrgPrflUpdate_B_Rq 1;
BA_ "GenSigSendType" SG_ 529 OnbChrgPrflUpdate_B_Rq 3;
BA_ "U_CD542_MY2021_Tx" SG_ 529 OnbChrgLocIdUns_B_Rq 1;
BA_ "U_T6_MCA_MY2020_Tx" SG_ 529 OnbChrgLocIdUns_B_Rq 1;
BA_ "U_P702_MY2021_Tx" SG_ 529 OnbChrgLocIdUns_B_Rq 1;
BA_ "U_CD542_MY2021_Tx" SG_ 529 OnbChrgLocIdTrgt_No_Rq 1;
BA_ "U_T6_MCA_MY2020_Tx" SG_ 529 OnbChrgLocIdTrgt_No_Rq 1;
BA_ "U_P702_MY2021_Tx" SG_ 529 OnbChrgLocIdTrgt_No_Rq 1;
BA_ "GenSigSendType" SG_ 529 OnbChrgLocIdTrgt_No_Rq 3;
BA_ "U_CD542_MY2021_Rx" SG_ 642 SldrrMsgTxt_D2_Rq_UB 1;
BA_ "U_T6_MCA_MY2020_Rx" SG_ 642 SldrrMsgTxt_D2_Rq_UB 1;
BA_ "U_CD542_MY2021_Rx" SG_ 642 SldrrMsgTxt_D2_Rq 1;
BA_ "U_T6_MCA_MY2020_Rx" SG_ 642 SldrrMsgTxt_D2_Rq 1;
BA_ "GenSigSendType" SG_ 642 SldrrMsgTxt_D2_Rq 3;
BA_ "WakeupSignal" SG_ 642 SldrrMsgTxt_D2_Rq 1;
BA_ "U_CD542_MY2021_Rx" SG_ 642 SldrrChime_D_Rq_UB 1;
BA_ "U_T6_MCA_MY2020_Rx" SG_ 642 SldrrChime_D_Rq_UB 1;
BA_ "U_CD542_MY2021_Rx" SG_ 642 SldrrChime_D_Rq 1;
BA_ "U_T6_MCA_MY2020_Rx" SG_ 642 SldrrChime_D_Rq 1;
BA_ "GenSigSendType" SG_ 642 SldrrChime_D_Rq 3;
BA_ "WakeupSignal" SG_ 642 SldrrChime_D_Rq 1;
BA_ "U_CD542_MY2021_Rx" SG_ 642 SldrlMsgTxt_D2_Rq_UB 1;
BA_ "U_T6_MCA_MY2020_Rx" SG_ 642 SldrlMsgTxt_D2_Rq_UB 1;
BA_ "U_CD542_MY2021_Rx" SG_ 642 SldrlMsgTxt_D2_Rq 1;
BA_ "U_T6_MCA_MY2020_Rx" SG_ 642 SldrlMsgTxt_D2_Rq 1;
BA_ "GenSigSendType" SG_ 642 SldrlMsgTxt_D2_Rq 3;
BA_ "WakeupSignal" SG_ 642 SldrlMsgTxt_D2_Rq 1;
BA_ "U_CD542_MY2021_Rx" SG_ 642 SldrlChime_D_Rq_UB 1;
BA_ "U_T6_MCA_MY2020_Rx" SG_ 642 SldrlChime_D_Rq_UB 1;
BA_ "U_CD542_MY2021_Rx" SG_ 642 SldrlChime_D_Rq 1;
BA_ "U_T6_MCA_MY2020_Rx" SG_ 642 SldrlChime_D_Rq 1;
BA_ "GenSigSendType" SG_ 642 SldrlChime_D_Rq 3;
BA_ "WakeupSignal" SG_ 642 SldrlChime_D_Rq 1;
BA_ "U_T6_MCA_MY2020_Rx" SG_ 642 PaakMyKeySearch_D_Stat_UB 1;
BA_ "U_P702_MY2021_Rx" SG_ 642 PaakMyKeySearch_D_Stat_UB 1;
BA_ "U_CD542_MY2021_Rx" SG_ 642 UreaLvlQlty_D_RqDsply_UB 1;
BA_ "U_T6_MCA_MY2020_Rx" SG_ 642 UreaLvlQlty_D_RqDsply_UB 1;
BA_ "U_P702_MY2021_Rx" SG_ 642 UreaLvlQlty_D_RqDsply_UB 1;
BA_ "U_CD542_MY2021_Rx" SG_ 642 DieslPrtcWarn_D_Rq_UB 1;
BA_ "U_T6_MCA_MY2020_Rx" SG_ 642 DieslPrtcWarn_D_Rq_UB 1;
BA_ "U_CD542_MY2021_Rx" SG_ 642 UreaQltySysWarn_D_Rq_UB 1;
BA_ "U_T6_MCA_MY2020_Rx" SG_ 642 UreaQltySysWarn_D_Rq_UB 1;
BA_ "U_P702_MY2021_Rx" SG_ 642 UreaQltySysWarn_D_Rq_UB 1;
BA_ "U_CD542_MY2021_Rx" SG_ 642 UreaLvlTxtWarn_D_Rq_UB 1;
BA_ "U_T6_MCA_MY2020_Rx" SG_ 642 UreaLvlTxtWarn_D_Rq_UB 1;
BA_ "U_P702_MY2021_Rx" SG_ 642 UreaLvlTxtWarn_D_Rq_UB 1;
BA_ "U_CD542_MY2021_Rx" SG_ 642 UreaLvlQlty_D_RqDsply 1;
BA_ "U_T6_MCA_MY2020_Rx" SG_ 642 UreaLvlQlty_D_RqDsply 1;
BA_ "U_P702_MY2021_Rx" SG_ 642 UreaLvlQlty_D_RqDsply 1;
BA_ "GenSigSendType" SG_ 642 UreaLvlQlty_D_RqDsply 3;
BA_ "U_CD542_MY2021_Rx" SG_ 642 UreaLvlTxtWarn_D_Rq 1;
BA_ "U_T6_MCA_MY2020_Rx" SG_ 642 UreaLvlTxtWarn_D_Rq 1;
BA_ "U_P702_MY2021_Rx" SG_ 642 UreaLvlTxtWarn_D_Rq 1;
BA_ "GenSigSendType" SG_ 642 UreaLvlTxtWarn_D_Rq 3;
BA_ "U_CD542_MY2021_Rx" SG_ 642 UreaQltySysWarn_D_Rq 1;
BA_ "U_T6_MCA_MY2020_Rx" SG_ 642 UreaQltySysWarn_D_Rq 1;
BA_ "U_P702_MY2021_Rx" SG_ 642 UreaQltySysWarn_D_Rq 1;
BA_ "GenSigSendType" SG_ 642 UreaQltySysWarn_D_Rq 3;
BA_ "U_CD542_MY2021_Rx" SG_ 642 DieslPrtcWarn_D_Rq 1;
BA_ "U_T6_MCA_MY2020_Rx" SG_ 642 DieslPrtcWarn_D_Rq 1;
BA_ "GenSigSendType" SG_ 642 DieslPrtcWarn_D_Rq 3;
BA_ "U_CD542_MY2021_Rx" SG_ 642 KeyMyKeyTot_No2_Cnt_UB 1;
BA_ "U_T6_MCA_MY2020_Rx" SG_ 642 KeyMyKeyTot_No2_Cnt_UB 1;
BA_ "U_P702_MY2021_Rx" SG_ 642 KeyMyKeyTot_No2_Cnt_UB 1;
BA_ "U_CD542_MY2021_Rx" SG_ 642 KeyAdmnTot_No2_Cnt_UB 1;
BA_ "U_T6_MCA_MY2020_Rx" SG_ 642 KeyAdmnTot_No2_Cnt_UB 1;
BA_ "U_P702_MY2021_Rx" SG_ 642 KeyAdmnTot_No2_Cnt_UB 1;
BA_ "U_T6_MCA_MY2020_Rx" SG_ 642 KeyMyKeyTot_No2_Cnt 1;
BA_ "U_P702_MY2021_Rx" SG_ 642 KeyMyKeyTot_No2_Cnt 1;
BA_ "U_CD542_MY2021_Rx" SG_ 642 KeyAdmnTot_No2_Cnt 1;
BA_ "U_T6_MCA_MY2020_Rx" SG_ 642 KeyAdmnTot_No2_Cnt 1;
BA_ "U_P702_MY2021_Rx" SG_ 642 KeyAdmnTot_No2_Cnt 1;
BA_ "U_CD542_MY2021_Rx" SG_ 642 DcChrgSrvcRqd_B_Rq_UB 1;
BA_ "U_T6_MCA_MY2020_Rx" SG_ 642 DcChrgSrvcRqd_B_Rq_UB 1;
BA_ "U_CD542_MY2021_Rx" SG_ 642 DcChrgSrvcRqd_B_Rq 1;
BA_ "U_T6_MCA_MY2020_Rx" SG_ 642 DcChrgSrvcRqd_B_Rq 1;
BA_ "GenSigSendType" SG_ 642 DcChrgSrvcRqd_B_Rq 3;
BA_ "U_CD542_MY2021_Rx" SG_ 642 PaakMyKeySearch_D_Stat 1;
BA_ "U_T6_MCA_MY2020_Rx" SG_ 642 PaakMyKeySearch_D_Stat 1;
BA_ "U_P702_MY2021_Rx" SG_ 642 PaakMyKeySearch_D_Stat 1;
BA_ "GenSigSendType" SG_ 642 PaakMyKeySearch_D_Stat 3;
BA_ "U_CD542_MY2021_Rx" SG_ 642 GrdAsstActv_B_Stat_UB 1;
BA_ "U_CD542_MY2021_Rx" SG_ 642 GrdAsstActv_B_Stat 1;
BA_ "GenSigSendType" SG_ 642 GrdAsstActv_B_Stat 3;
BA_ "U_CD542_MY2021_Rx" SG_ 642 TrlrAidTrlrId_No_Rq_UB 1;
BA_ "U_T6_MCA_MY2020_Rx" SG_ 642 TrlrAidTrlrId_No_Rq_UB 1;
BA_ "U_CD542_MY2021_Rx" SG_ 642 TrlrAidTrlrId_No_Rq 1;
BA_ "U_T6_MCA_MY2020_Rx" SG_ 642 TrlrAidTrlrId_No_Rq 1;
BA_ "GenSigSendType" SG_ 642 TrlrAidTrlrId_No_Rq 3;
BA_ "U_CD542_MY2021_Rx" SG_ 893 RngImpctClim_L_Dsply_UB 1;
BA_ "U_T6_MCA_MY2020_Rx" SG_ 893 RngImpctClim_L_Dsply_UB 1;
BA_ "U_CD542_MY2021_Rx" SG_ 893 RngImpctDrv_L_Dsply_UB 1;
BA_ "U_T6_MCA_MY2020_Rx" SG_ 893 RngImpctDrv_L_Dsply_UB 1;
BA_ "U_CD542_MY2021_Rx" SG_ 893 RngImpctDrv_L_Dsply 1;
BA_ "U_T6_MCA_MY2020_Rx" SG_ 893 RngImpctDrv_L_Dsply 1;
BA_ "GenSigStartValueInteger" SG_ 893 RngImpctDrv_L_Dsply 255;
BA_ "U_CD542_MY2021_Rx" SG_ 893 RngImpctClim_L_Dsply 1;
BA_ "U_T6_MCA_MY2020_Rx" SG_ 893 RngImpctClim_L_Dsply 1;
BA_ "GenSigStartValueInteger" SG_ 893 RngImpctClim_L_Dsply 255;
BA_ "U_CD542_MY2021_Rx" SG_ 893 VehElEffAvg_No_Dsply_UB 1;
BA_ "U_T6_MCA_MY2020_Rx" SG_ 893 VehElEffAvg_No_Dsply_UB 1;
BA_ "U_CD542_MY2021_Rx" SG_ 893 VehElEffAvg_No_Dsply 1;
BA_ "U_T6_MCA_MY2020_Rx" SG_ 893 VehElEffAvg_No_Dsply 1;
BA_ "GenSigStartValue" SG_ 893 VehElEffAvg_No_Dsply 126;
BA_ "GenSigStartValueInteger" SG_ 893 VehElEffAvg_No_Dsply 126;
BA_ "U_T6_MCA_MY2020_Rx" SG_ 893 TrnAout2_W_ActlUnfilt_UB 1;
BA_ "U_T6_MCA_MY2020_Rx" SG_ 893 TrnAout2_W_ActlUnfilt 1;
BA_ "GenSigStartValue" SG_ 893 TrnAout2_W_ActlUnfilt 65534;
BA_ "GenSigStartValueInteger" SG_ 893 TrnAout2_W_ActlUnfilt 65534;
BA_ "U_CD542_MY2021_Tx" SG_ 500 Dsp_SourceSetTrack_Rq 1;
BA_ "U_T6_MCA_MY2020_Tx" SG_ 500 Dsp_SourceSetTrack_Rq 1;
BA_ "U_P702_MY2021_Tx" SG_ 500 Dsp_SourceSetTrack_Rq 1;
BA_ "U_CD542_MY2021_Rx" SG_ 500 Dsp_SourceSetTrack_Rq 1;
BA_ "U_T6_MCA_MY2020_Rx" SG_ 500 Dsp_SourceSetTrack_Rq 1;
BA_ "U_P702_MY2021_Rx" SG_ 500 Dsp_SourceSetTrack_Rq 1;
BA_ "U_CD542_MY2021_Tx" SG_ 500 Dsp_ItemNameLength_Rq 1;
BA_ "U_T6_MCA_MY2020_Tx" SG_ 500 Dsp_ItemNameLength_Rq 1;
BA_ "U_P702_MY2021_Tx" SG_ 500 Dsp_ItemNameLength_Rq 1;
BA_ "U_CD542_MY2021_Rx" SG_ 500 Dsp_ItemNameLength_Rq 1;
BA_ "U_T6_MCA_MY2020_Rx" SG_ 500 Dsp_ItemNameLength_Rq 1;
BA_ "U_P702_MY2021_Rx" SG_ 500 Dsp_ItemNameLength_Rq 1;
BA_ "U_CD542_MY2021_Tx" SG_ 500 Dsp_GetCDTOCDData_Rq 1;
BA_ "U_T6_MCA_MY2020_Tx" SG_ 500 Dsp_GetCDTOCDData_Rq 1;
BA_ "U_P702_MY2021_Tx" SG_ 500 Dsp_GetCDTOCDData_Rq 1;
BA_ "U_CD542_MY2021_Rx" SG_ 500 Dsp_GetCDTOCDData_Rq 1;
BA_ "U_T6_MCA_MY2020_Rx" SG_ 500 Dsp_GetCDTOCDData_Rq 1;
BA_ "U_P702_MY2021_Rx" SG_ 500 Dsp_GetCDTOCDData_Rq 1;
BA_ "GenSigSendType" SG_ 500 Dsp_GetCDTOCDData_Rq 3;
BA_ "U_CD542_MY2021_Tx" SG_ 500 Dsp_FolderNumber_Rq 1;
BA_ "U_T6_MCA_MY2020_Tx" SG_ 500 Dsp_FolderNumber_Rq 1;
BA_ "U_P702_MY2021_Tx" SG_ 500 Dsp_FolderNumber_Rq 1;
BA_ "U_CD542_MY2021_Rx" SG_ 500 Dsp_FolderNumber_Rq 1;
BA_ "U_T6_MCA_MY2020_Rx" SG_ 500 Dsp_FolderNumber_Rq 1;
BA_ "U_P702_MY2021_Rx" SG_ 500 Dsp_FolderNumber_Rq 1;
BA_ "U_CD542_MY2021_Tx" SG_ 500 Dsp_CutItem_Rq 1;
BA_ "U_T6_MCA_MY2020_Tx" SG_ 500 Dsp_CutItem_Rq 1;
BA_ "U_P702_MY2021_Tx" SG_ 500 Dsp_CutItem_Rq 1;
BA_ "U_CD542_MY2021_Rx" SG_ 500 Dsp_CutItem_Rq 1;
BA_ "U_T6_MCA_MY2020_Rx" SG_ 500 Dsp_CutItem_Rq 1;
BA_ "U_P702_MY2021_Rx" SG_ 500 Dsp_CutItem_Rq 1;
BA_ "U_CD542_MY2021_Tx" SG_ 500 Dsp_AudioSourceSel_Rq 1;
BA_ "U_T6_MCA_MY2020_Tx" SG_ 500 Dsp_AudioSourceSel_Rq 1;
BA_ "U_P702_MY2021_Tx" SG_ 500 Dsp_AudioSourceSel_Rq 1;
BA_ "U_CD542_MY2021_Rx" SG_ 500 Dsp_AudioSourceSel_Rq 1;
BA_ "U_T6_MCA_MY2020_Rx" SG_ 500 Dsp_AudioSourceSel_Rq 1;
BA_ "U_P702_MY2021_Rx" SG_ 500 Dsp_AudioSourceSel_Rq 1;
BA_ "GenSigSendType" SG_ 500 Dsp_AudioSourceSel_Rq 3;
BA_ "U_CD542_MY2021_Tx" SG_ 503 Dsp_PlayFrstTrInFldr_Rq 1;
BA_ "U_T6_MCA_MY2020_Tx" SG_ 503 Dsp_PlayFrstTrInFldr_Rq 1;
BA_ "U_P702_MY2021_Tx" SG_ 503 Dsp_PlayFrstTrInFldr_Rq 1;
BA_ "U_CD542_MY2021_Rx" SG_ 503 Dsp_PlayFrstTrInFldr_Rq 1;
BA_ "U_T6_MCA_MY2020_Rx" SG_ 503 Dsp_PlayFrstTrInFldr_Rq 1;
BA_ "U_P702_MY2021_Rx" SG_ 503 Dsp_PlayFrstTrInFldr_Rq 1;
BA_ "U_CD542_MY2021_Tx" SG_ 503 Dsp_ItemIndex_Rq 1;
BA_ "U_T6_MCA_MY2020_Tx" SG_ 503 Dsp_ItemIndex_Rq 1;
BA_ "U_P702_MY2021_Tx" SG_ 503 Dsp_ItemIndex_Rq 1;
BA_ "U_CD542_MY2021_Rx" SG_ 503 Dsp_ItemIndex_Rq 1;
BA_ "U_T6_MCA_MY2020_Rx" SG_ 503 Dsp_ItemIndex_Rq 1;
BA_ "U_P702_MY2021_Rx" SG_ 503 Dsp_ItemIndex_Rq 1;
BA_ "U_CD542_MY2021_Tx" SG_ 503 Dsp_FolderNumber3_Rq 1;
BA_ "U_T6_MCA_MY2020_Tx" SG_ 503 Dsp_FolderNumber3_Rq 1;
BA_ "U_P702_MY2021_Tx" SG_ 503 Dsp_FolderNumber3_Rq 1;
BA_ "U_CD542_MY2021_Rx" SG_ 503 Dsp_FolderNumber3_Rq 1;
BA_ "U_T6_MCA_MY2020_Rx" SG_ 503 Dsp_FolderNumber3_Rq 1;
BA_ "U_P702_MY2021_Rx" SG_ 503 Dsp_FolderNumber3_Rq 1;
BA_ "U_CD542_MY2021_Tx" SG_ 503 Dsp_AudioSourceSel3_Rq 1;
BA_ "U_T6_MCA_MY2020_Tx" SG_ 503 Dsp_AudioSourceSel3_Rq 1;
BA_ "U_P702_MY2021_Tx" SG_ 503 Dsp_AudioSourceSel3_Rq 1;
BA_ "U_CD542_MY2021_Rx" SG_ 503 Dsp_AudioSourceSel3_Rq 1;
BA_ "U_T6_MCA_MY2020_Rx" SG_ 503 Dsp_AudioSourceSel3_Rq 1;
BA_ "U_P702_MY2021_Rx" SG_ 503 Dsp_AudioSourceSel3_Rq 1;
BA_ "GenSigSendType" SG_ 503 Dsp_AudioSourceSel3_Rq 3;
BA_ "U_CD542_MY2021_Tx" SG_ 412 LBC2_StartItemInd 1;
BA_ "U_T6_MCA_MY2020_Tx" SG_ 412 LBC2_StartItemInd 1;
BA_ "U_P702_MY2021_Tx" SG_ 412 LBC2_StartItemInd 1;
BA_ "U_CD542_MY2021_Rx" SG_ 412 LBC2_StartItemInd 1;
BA_ "U_T6_MCA_MY2020_Rx" SG_ 412 LBC2_StartItemInd 1;
BA_ "U_P702_MY2021_Rx" SG_ 412 LBC2_StartItemInd 1;
BA_ "U_CD542_MY2021_Tx" SG_ 412 LBC2_SetListServ 1;
BA_ "U_T6_MCA_MY2020_Tx" SG_ 412 LBC2_SetListServ 1;
BA_ "U_P702_MY2021_Tx" SG_ 412 LBC2_SetListServ 1;
BA_ "U_CD542_MY2021_Rx" SG_ 412 LBC2_SetListServ 1;
BA_ "U_T6_MCA_MY2020_Rx" SG_ 412 LBC2_SetListServ 1;
BA_ "U_P702_MY2021_Rx" SG_ 412 LBC2_SetListServ 1;
BA_ "U_CD542_MY2021_Tx" SG_ 412 LBC2_Opcode 1;
BA_ "U_T6_MCA_MY2020_Tx" SG_ 412 LBC2_Opcode 1;
BA_ "U_P702_MY2021_Tx" SG_ 412 LBC2_Opcode 1;
BA_ "U_CD542_MY2021_Rx" SG_ 412 LBC2_Opcode 1;
BA_ "U_T6_MCA_MY2020_Rx" SG_ 412 LBC2_Opcode 1;
BA_ "U_P702_MY2021_Rx" SG_ 412 LBC2_Opcode 1;
BA_ "GenSigSendType" SG_ 412 LBC2_Opcode 3;
BA_ "U_CD542_MY2021_Tx" SG_ 412 LBC2_NbrOfItems 1;
BA_ "U_T6_MCA_MY2020_Tx" SG_ 412 LBC2_NbrOfItems 1;
BA_ "U_P702_MY2021_Tx" SG_ 412 LBC2_NbrOfItems 1;
BA_ "U_CD542_MY2021_Rx" SG_ 412 LBC2_NbrOfItems 1;
BA_ "U_T6_MCA_MY2020_Rx" SG_ 412 LBC2_NbrOfItems 1;
BA_ "U_P702_MY2021_Rx" SG_ 412 LBC2_NbrOfItems 1;
BA_ "U_CD542_MY2021_Tx" SG_ 412 LBC2_ItemIndex 1;
BA_ "U_T6_MCA_MY2020_Tx" SG_ 412 LBC2_ItemIndex 1;
BA_ "U_P702_MY2021_Tx" SG_ 412 LBC2_ItemIndex 1;
BA_ "U_CD542_MY2021_Rx" SG_ 412 LBC2_ItemIndex 1;
BA_ "U_T6_MCA_MY2020_Rx" SG_ 412 LBC2_ItemIndex 1;
BA_ "U_CD542_MY2021_Tx" SG_ 412 LBC2_ActiveListID 1;
BA_ "U_T6_MCA_MY2020_Tx" SG_ 412 LBC2_ActiveListID 1;
BA_ "U_P702_MY2021_Tx" SG_ 412 LBC2_ActiveListID 1;
BA_ "U_CD542_MY2021_Rx" SG_ 412 LBC2_ActiveListID 1;
BA_ "U_T6_MCA_MY2020_Rx" SG_ 412 LBC2_ActiveListID 1;
BA_ "U_P702_MY2021_Rx" SG_ 412 LBC2_ActiveListID 1;
BA_ "U_CD542_MY2021_Tx" SG_ 493 Dsp_StatLiScanCancel_Rq 1;
BA_ "U_T6_MCA_MY2020_Tx" SG_ 493 Dsp_StatLiScanCancel_Rq 1;
BA_ "U_P702_MY2021_Tx" SG_ 493 Dsp_StatLiScanCancel_Rq 1;
BA_ "U_CD542_MY2021_Rx" SG_ 493 Dsp_StatLiScanCancel_Rq 1;
BA_ "U_T6_MCA_MY2020_Rx" SG_ 493 Dsp_StatLiScanCancel_Rq 1;
BA_ "U_P702_MY2021_Rx" SG_ 493 Dsp_StatLiScanCancel_Rq 1;
BA_ "GenSigSendType" SG_ 493 Dsp_StatLiScanCancel_Rq 3;
BA_ "U_CD542_MY2021_Tx" SG_ 493 Dsp_StationList_Rq 1;
BA_ "U_T6_MCA_MY2020_Tx" SG_ 493 Dsp_StationList_Rq 1;
BA_ "U_P702_MY2021_Tx" SG_ 493 Dsp_StationList_Rq 1;
BA_ "U_CD542_MY2021_Rx" SG_ 493 Dsp_StationList_Rq 1;
BA_ "U_T6_MCA_MY2020_Rx" SG_ 493 Dsp_StationList_Rq 1;
BA_ "U_P702_MY2021_Rx" SG_ 493 Dsp_StationList_Rq 1;
BA_ "GenSigSendType" SG_ 493 Dsp_StationList_Rq 3;
BA_ "U_CD542_MY2021_Tx" SG_ 493 Dsp_StartIndex3_Rq 1;
BA_ "U_T6_MCA_MY2020_Tx" SG_ 493 Dsp_StartIndex3_Rq 1;
BA_ "U_P702_MY2021_Tx" SG_ 493 Dsp_StartIndex3_Rq 1;
BA_ "U_CD542_MY2021_Rx" SG_ 493 Dsp_StartIndex3_Rq 1;
BA_ "U_T6_MCA_MY2020_Rx" SG_ 493 Dsp_StartIndex3_Rq 1;
BA_ "U_P702_MY2021_Rx" SG_ 493 Dsp_StartIndex3_Rq 1;
BA_ "U_CD542_MY2021_Tx" SG_ 493 Dsp_RefreshFlag 1;
BA_ "U_T6_MCA_MY2020_Tx" SG_ 493 Dsp_RefreshFlag 1;
BA_ "U_P702_MY2021_Tx" SG_ 493 Dsp_RefreshFlag 1;
BA_ "U_CD542_MY2021_Rx" SG_ 493 Dsp_RefreshFlag 1;
BA_ "U_T6_MCA_MY2020_Rx" SG_ 493 Dsp_RefreshFlag 1;
BA_ "U_P702_MY2021_Rx" SG_ 493 Dsp_RefreshFlag 1;
BA_ "U_CD542_MY2021_Tx" SG_ 493 Dsp_PTYCode_Rq 1;
BA_ "U_T6_MCA_MY2020_Tx" SG_ 493 Dsp_PTYCode_Rq 1;
BA_ "U_P702_MY2021_Tx" SG_ 493 Dsp_PTYCode_Rq 1;
BA_ "U_CD542_MY2021_Rx" SG_ 493 Dsp_PTYCode_Rq 1;
BA_ "U_T6_MCA_MY2020_Rx" SG_ 493 Dsp_PTYCode_Rq 1;
BA_ "U_P702_MY2021_Rx" SG_ 493 Dsp_PTYCode_Rq 1;
BA_ "U_CD542_MY2021_Tx" SG_ 493 Dsp_ListSize_Rq 1;
BA_ "U_T6_MCA_MY2020_Tx" SG_ 493 Dsp_ListSize_Rq 1;
BA_ "U_P702_MY2021_Tx" SG_ 493 Dsp_ListSize_Rq 1;
BA_ "U_CD542_MY2021_Rx" SG_ 493 Dsp_ListSize_Rq 1;
BA_ "U_T6_MCA_MY2020_Rx" SG_ 493 Dsp_ListSize_Rq 1;
BA_ "U_P702_MY2021_Rx" SG_ 493 Dsp_ListSize_Rq 1;
BA_ "U_CD542_MY2021_Tx" SG_ 493 Dsp_AFJump_Rq 1;
BA_ "U_T6_MCA_MY2020_Tx" SG_ 493 Dsp_AFJump_Rq 1;
BA_ "U_P702_MY2021_Tx" SG_ 493 Dsp_AFJump_Rq 1;
BA_ "U_CD542_MY2021_Rx" SG_ 493 Dsp_AFJump_Rq 1;
BA_ "U_T6_MCA_MY2020_Rx" SG_ 493 Dsp_AFJump_Rq 1;
BA_ "U_P702_MY2021_Rx" SG_ 493 Dsp_AFJump_Rq 1;
BA_ "GenSigSendType" SG_ 493 Dsp_AFJump_Rq 3;
BA_ "GenSigSendType" SG_ 511 SdarsAudioRtng_D_Rq 3;
BA_ "U_CD542_MY2021_Tx" SG_ 511 Dsp_TUStartIndex2_Rq 1;
BA_ "U_T6_MCA_MY2020_Tx" SG_ 511 Dsp_TUStartIndex2_Rq 1;
BA_ "U_P702_MY2021_Tx" SG_ 511 Dsp_TUStartIndex2_Rq 1;
BA_ "U_CD542_MY2021_Rx" SG_ 511 Dsp_TUStartIndex2_Rq 1;
BA_ "U_T6_MCA_MY2020_Rx" SG_ 511 Dsp_TUStartIndex2_Rq 1;
BA_ "U_P702_MY2021_Rx" SG_ 511 Dsp_TUStartIndex2_Rq 1;
BA_ "U_CD542_MY2021_Tx" SG_ 511 Dsp_TUPresetArea_Rq 1;
BA_ "U_T6_MCA_MY2020_Tx" SG_ 511 Dsp_TUPresetArea_Rq 1;
BA_ "U_P702_MY2021_Tx" SG_ 511 Dsp_TUPresetArea_Rq 1;
BA_ "U_CD542_MY2021_Rx" SG_ 511 Dsp_TUPresetArea_Rq 1;
BA_ "U_T6_MCA_MY2020_Rx" SG_ 511 Dsp_TUPresetArea_Rq 1;
BA_ "U_P702_MY2021_Rx" SG_ 511 Dsp_TUPresetArea_Rq 1;
BA_ "GenSigSendType" SG_ 511 Dsp_TUPresetArea_Rq 3;
BA_ "U_CD542_MY2021_Tx" SG_ 511 Dsp_TUNbrOfPresets_Rq 1;
BA_ "U_T6_MCA_MY2020_Tx" SG_ 511 Dsp_TUNbrOfPresets_Rq 1;
BA_ "U_P702_MY2021_Tx" SG_ 511 Dsp_TUNbrOfPresets_Rq 1;
BA_ "U_CD542_MY2021_Rx" SG_ 511 Dsp_TUNbrOfPresets_Rq 1;
BA_ "U_T6_MCA_MY2020_Rx" SG_ 511 Dsp_TUNbrOfPresets_Rq 1;
BA_ "U_P702_MY2021_Rx" SG_ 511 Dsp_TUNbrOfPresets_Rq 1;
BA_ "U_CD542_MY2021_Tx" SG_ 511 Dsp_SetCurrTUPreset_Rq 1;
BA_ "U_T6_MCA_MY2020_Tx" SG_ 511 Dsp_SetCurrTUPreset_Rq 1;
BA_ "U_P702_MY2021_Tx" SG_ 511 Dsp_SetCurrTUPreset_Rq 1;
BA_ "U_CD542_MY2021_Rx" SG_ 511 Dsp_SetCurrTUPreset_Rq 1;
BA_ "U_T6_MCA_MY2020_Rx" SG_ 511 Dsp_SetCurrTUPreset_Rq 1;
BA_ "U_P702_MY2021_Rx" SG_ 511 Dsp_SetCurrTUPreset_Rq 1;
BA_ "GenSigSendType" SG_ 511 Dsp_SetCurrTUPreset_Rq 3;
BA_ "U_CD542_MY2021_Tx" SG_ 511 Dsp_SetCurrTUBand_Rq 1;
BA_ "U_T6_MCA_MY2020_Tx" SG_ 511 Dsp_SetCurrTUBand_Rq 1;
BA_ "U_P702_MY2021_Tx" SG_ 511 Dsp_SetCurrTUBand_Rq 1;
BA_ "U_CD542_MY2021_Rx" SG_ 511 Dsp_SetCurrTUBand_Rq 1;
BA_ "U_T6_MCA_MY2020_Rx" SG_ 511 Dsp_SetCurrTUBand_Rq 1;
BA_ "U_P702_MY2021_Rx" SG_ 511 Dsp_SetCurrTUBand_Rq 1;
BA_ "GenSigSendType" SG_ 511 Dsp_SetCurrTUBand_Rq 3;
BA_ "U_CD542_MY2021_Tx" SG_ 257 MFD_SetTagMode 1;
BA_ "U_T6_MCA_MY2020_Tx" SG_ 257 MFD_SetTagMode 1;
BA_ "U_P702_MY2021_Tx" SG_ 257 MFD_SetTagMode 1;
BA_ "U_CD542_MY2021_Rx" SG_ 257 MFD_SetTagMode 1;
BA_ "U_T6_MCA_MY2020_Rx" SG_ 257 MFD_SetTagMode 1;
BA_ "U_P702_MY2021_Rx" SG_ 257 MFD_SetTagMode 1;
BA_ "GenSigSendType" SG_ 257 MFD_SetTagMode 3;
BA_ "U_CD542_MY2021_Tx" SG_ 257 MFD_SetRBDSMode 1;
BA_ "U_T6_MCA_MY2020_Tx" SG_ 257 MFD_SetRBDSMode 1;
BA_ "U_P702_MY2021_Tx" SG_ 257 MFD_SetRBDSMode 1;
BA_ "U_CD542_MY2021_Rx" SG_ 257 MFD_SetRBDSMode 1;
BA_ "U_T6_MCA_MY2020_Rx" SG_ 257 MFD_SetRBDSMode 1;
BA_ "U_P702_MY2021_Rx" SG_ 257 MFD_SetRBDSMode 1;
BA_ "GenSigSendType" SG_ 257 MFD_SetRBDSMode 3;
BA_ "U_CD542_MY2021_Tx" SG_ 257 MFD_SetHDModeRq 1;
BA_ "U_T6_MCA_MY2020_Tx" SG_ 257 MFD_SetHDModeRq 1;
BA_ "U_P702_MY2021_Tx" SG_ 257 MFD_SetHDModeRq 1;
BA_ "U_CD542_MY2021_Rx" SG_ 257 MFD_SetHDModeRq 1;
BA_ "U_T6_MCA_MY2020_Rx" SG_ 257 MFD_SetHDModeRq 1;
BA_ "U_P702_MY2021_Rx" SG_ 257 MFD_SetHDModeRq 1;
BA_ "GenSigSendType" SG_ 257 MFD_SetHDModeRq 3;
BA_ "U_CD542_MY2021_Tx" SG_ 257 MFD_GetTagInfo 1;
BA_ "U_T6_MCA_MY2020_Tx" SG_ 257 MFD_GetTagInfo 1;
BA_ "U_P702_MY2021_Tx" SG_ 257 MFD_GetTagInfo 1;
BA_ "U_CD542_MY2021_Rx" SG_ 257 MFD_GetTagInfo 1;
BA_ "U_T6_MCA_MY2020_Rx" SG_ 257 MFD_GetTagInfo 1;
BA_ "U_P702_MY2021_Rx" SG_ 257 MFD_GetTagInfo 1;
BA_ "GenSigSendType" SG_ 257 MFD_GetTagInfo 3;
BA_ "U_CD542_MY2021_Tx" SG_ 713 SDARS_RDISP_WORD_Rx 1;
BA_ "U_T6_MCA_MY2020_Tx" SG_ 713 SDARS_RDISP_WORD_Rx 1;
BA_ "U_P702_MY2021_Tx" SG_ 713 SDARS_RDISP_WORD_Rx 1;
BA_ "U_CD542_MY2021_Rx" SG_ 713 SDARS_RDISP_WORD_Rx 1;
BA_ "U_T6_MCA_MY2020_Rx" SG_ 713 SDARS_RDISP_WORD_Rx 1;
BA_ "U_P702_MY2021_Rx" SG_ 713 SDARS_RDISP_WORD_Rx 1;
BA_ "U_CD542_MY2021_Rx" SG_ 382 EngMnfldChrg_Te_Actl 1;
BA_ "U_T6_MCA_MY2020_Rx" SG_ 382 EngMnfldChrg_Te_Actl 1;
BA_ "GenSigStartValue" SG_ 382 EngMnfldChrg_Te_Actl 126;
BA_ "GenSigStartValueInteger" SG_ 382 EngMnfldChrg_Te_Actl 126;
BA_ "U_CD542_MY2021_Rx" SG_ 382 EngInnrClnt_Te_Actl 1;
BA_ "GenSigStartValue" SG_ 382 EngInnrClnt_Te_Actl 126;
BA_ "GenSigStartValueInteger" SG_ 382 EngInnrClnt_Te_Actl 56;
BA_ "U_CD542_MY2021_Rx" SG_ 877 Rr_Third_Power_Btn_Stt 1;
BA_ "U_T6_MCA_MY2020_Rx" SG_ 877 Rr_Third_Power_Btn_Stt 1;
BA_ "U_P702_MY2021_Rx" SG_ 877 Rr_Third_Power_Btn_Stt 1;
BA_ "GenSigStartValue" SG_ 877 Rr_Third_Power_Btn_Stt 2;
BA_ "GenSigStartValueInteger" SG_ 877 Rr_Third_Power_Btn_Stt 2;
BA_ "U_CD542_MY2021_Rx" SG_ 877 Rr_Third_Floor_Btn_Stt 1;
BA_ "U_T6_MCA_MY2020_Rx" SG_ 877 Rr_Third_Floor_Btn_Stt 1;
BA_ "U_P702_MY2021_Rx" SG_ 877 Rr_Third_Floor_Btn_Stt 1;
BA_ "GenSigStartValue" SG_ 877 Rr_Third_Floor_Btn_Stt 2;
BA_ "GenSigStartValueInteger" SG_ 877 Rr_Third_Floor_Btn_Stt 2;
BA_ "U_CD542_MY2021_Rx" SG_ 877 Rr_Third_Auto_Btn_Stt 1;
BA_ "U_T6_MCA_MY2020_Rx" SG_ 877 Rr_Third_Auto_Btn_Stt 1;
BA_ "U_P702_MY2021_Rx" SG_ 877 Rr_Third_Auto_Btn_Stt 1;
BA_ "GenSigStartValue" SG_ 877 Rr_Third_Auto_Btn_Stt 2;
BA_ "GenSigStartValueInteger" SG_ 877 Rr_Third_Auto_Btn_Stt 2;
BA_ "U_CD542_MY2021_Rx" SG_ 877 Rr_Lock_Btn_Stt 1;
BA_ "U_T6_MCA_MY2020_Rx" SG_ 877 Rr_Lock_Btn_Stt 1;
BA_ "U_P702_MY2021_Rx" SG_ 877 Rr_Lock_Btn_Stt 1;
BA_ "GenSigStartValue" SG_ 877 Rr_Lock_Btn_Stt 2;
BA_ "GenSigStartValueInteger" SG_ 877 Rr_Lock_Btn_Stt 2;
BA_ "U_CD542_MY2021_Rx" SG_ 877 Rr_RHS_Blower_Indicate 1;
BA_ "U_T6_MCA_MY2020_Rx" SG_ 877 Rr_RHS_Blower_Indicate 1;
BA_ "GenSigStartValue" SG_ 877 Rr_RHS_Blower_Indicate 15;
BA_ "GenSigStartValueInteger" SG_ 877 Rr_RHS_Blower_Indicate 15;
BA_ "U_CD542_MY2021_Rx" SG_ 877 Rr_Third_Panel_Btn_Stt 1;
BA_ "U_T6_MCA_MY2020_Rx" SG_ 877 Rr_Third_Panel_Btn_Stt 1;
BA_ "U_P702_MY2021_Rx" SG_ 877 Rr_Third_Panel_Btn_Stt 1;
BA_ "GenSigStartValue" SG_ 877 Rr_Third_Panel_Btn_Stt 2;
BA_ "GenSigStartValueInteger" SG_ 877 Rr_Third_Panel_Btn_Stt 2;
BA_ "U_CD542_MY2021_Rx" SG_ 877 Rr_Synch_Btn_Stt 1;
BA_ "U_T6_MCA_MY2020_Rx" SG_ 877 Rr_Synch_Btn_Stt 1;
BA_ "U_P702_MY2021_Rx" SG_ 877 Rr_Synch_Btn_Stt 1;
BA_ "GenSigStartValue" SG_ 877 Rr_Synch_Btn_Stt 2;
BA_ "GenSigStartValueInteger" SG_ 877 Rr_Synch_Btn_Stt 2;
BA_ "U_CD542_MY2021_Rx" SG_ 877 AAR_Btn_Stt 1;
BA_ "U_T6_MCA_MY2020_Rx" SG_ 877 AAR_Btn_Stt 1;
BA_ "U_P702_MY2021_Rx" SG_ 877 AAR_Btn_Stt 1;
BA_ "GenSigStartValue" SG_ 877 AAR_Btn_Stt 2;
BA_ "GenSigStartValueInteger" SG_ 877 AAR_Btn_Stt 2;
BA_ "U_CD542_MY2021_Rx" SG_ 877 Heat_Btn_Stt 1;
BA_ "U_T6_MCA_MY2020_Rx" SG_ 877 Heat_Btn_Stt 1;
BA_ "U_P702_MY2021_Rx" SG_ 877 Heat_Btn_Stt 1;
BA_ "GenSigStartValue" SG_ 877 Heat_Btn_Stt 2;
BA_ "GenSigStartValueInteger" SG_ 877 Heat_Btn_Stt 2;
BA_ "U_CD542_MY2021_Rx" SG_ 592 RFA_BLEM_APIM_Tx 1;
BA_ "U_T6_MCA_MY2020_Rx" SG_ 592 RFA_BLEM_APIM_Tx 1;
BA_ "U_P702_MY2021_Rx" SG_ 592 RFA_BLEM_APIM_Tx 1;
BA_ "U_CD542_MY2021_Tx" SG_ 600 APIM_RFA_BLEM_Tx 1;
BA_ "U_T6_MCA_MY2020_Tx" SG_ 600 APIM_RFA_BLEM_Tx 1;
BA_ "U_P702_MY2021_Tx" SG_ 600 APIM_RFA_BLEM_Tx 1;
BA_ "U_CD542_MY2021_Tx" SG_ 708 TMCSrvr_TMCClnt_WORD_Tx 1;
BA_ "U_T6_MCA_MY2020_Tx" SG_ 708 TMCSrvr_TMCClnt_WORD_Tx 1;
BA_ "U_P702_MY2021_Tx" SG_ 708 TMCSrvr_TMCClnt_WORD_Tx 1;
BA_ "U_CD542_MY2021_Rx" SG_ 708 TMCSrvr_TMCClnt_WORD_Tx 1;
BA_ "U_T6_MCA_MY2020_Rx" SG_ 708 TMCSrvr_TMCClnt_WORD_Tx 1;
BA_ "U_P702_MY2021_Rx" SG_ 708 TMCSrvr_TMCClnt_WORD_Tx 1;
BA_ "U_CD542_MY2021_Tx" SG_ 414 LBS2_ListStatus 1;
BA_ "U_T6_MCA_MY2020_Tx" SG_ 414 LBS2_ListStatus 1;
BA_ "U_P702_MY2021_Tx" SG_ 414 LBS2_ListStatus 1;
BA_ "U_P702_MY2021_Rx" SG_ 414 LBS2_ListStatus 1;
BA_ "U_CD542_MY2021_Rx" SG_ 414 LBS2_ListStatus 1;
BA_ "U_T6_MCA_MY2020_Rx" SG_ 414 LBS2_ListStatus 1;
BA_ "GenSigSendType" SG_ 414 LBS2_ListStatus 3;
BA_ "U_CD542_MY2021_Tx" SG_ 414 LBS2_ParentID 1;
BA_ "U_T6_MCA_MY2020_Tx" SG_ 414 LBS2_ParentID 1;
BA_ "U_P702_MY2021_Tx" SG_ 414 LBS2_ParentID 1;
BA_ "U_P702_MY2021_Rx" SG_ 414 LBS2_ParentID 1;
BA_ "U_CD542_MY2021_Rx" SG_ 414 LBS2_ParentID 1;
BA_ "U_T6_MCA_MY2020_Rx" SG_ 414 LBS2_ParentID 1;
BA_ "U_CD542_MY2021_Tx" SG_ 414 LBS2_ListServer 1;
BA_ "U_T6_MCA_MY2020_Tx" SG_ 414 LBS2_ListServer 1;
BA_ "U_P702_MY2021_Tx" SG_ 414 LBS2_ListServer 1;
BA_ "U_P702_MY2021_Rx" SG_ 414 LBS2_ListServer 1;
BA_ "U_CD542_MY2021_Rx" SG_ 414 LBS2_ListServer 1;
BA_ "U_T6_MCA_MY2020_Rx" SG_ 414 LBS2_ListServer 1;
BA_ "U_CD542_MY2021_Tx" SG_ 414 LBS2_ListID 1;
BA_ "U_T6_MCA_MY2020_Tx" SG_ 414 LBS2_ListID 1;
BA_ "U_P702_MY2021_Tx" SG_ 414 LBS2_ListID 1;
BA_ "U_P702_MY2021_Rx" SG_ 414 LBS2_ListID 1;
BA_ "U_CD542_MY2021_Rx" SG_ 414 LBS2_ListID 1;
BA_ "U_T6_MCA_MY2020_Rx" SG_ 414 LBS2_ListID 1;
BA_ "U_CD542_MY2021_Tx" SG_ 414 LBS2_EntryIndex 1;
BA_ "U_T6_MCA_MY2020_Tx" SG_ 414 LBS2_EntryIndex 1;
BA_ "U_P702_MY2021_Tx" SG_ 414 LBS2_EntryIndex 1;
BA_ "U_P702_MY2021_Rx" SG_ 414 LBS2_EntryIndex 1;
BA_ "U_CD542_MY2021_Rx" SG_ 414 LBS2_EntryIndex 1;
BA_ "U_T6_MCA_MY2020_Rx" SG_ 414 LBS2_EntryIndex 1;
BA_ "U_CD542_MY2021_Tx" SG_ 716 TMCSrvr_TMCClnt_WORD_Rx 1;
BA_ "U_T6_MCA_MY2020_Tx" SG_ 716 TMCSrvr_TMCClnt_WORD_Rx 1;
BA_ "U_P702_MY2021_Tx" SG_ 716 TMCSrvr_TMCClnt_WORD_Rx 1;
BA_ "U_CD542_MY2021_Rx" SG_ 716 TMCSrvr_TMCClnt_WORD_Rx 1;
BA_ "U_T6_MCA_MY2020_Rx" SG_ 716 TMCSrvr_TMCClnt_WORD_Rx 1;
BA_ "U_P702_MY2021_Rx" SG_ 716 TMCSrvr_TMCClnt_WORD_Rx 1;
BA_ "U_T6_MCA_MY2020_Rx" SG_ 1013 ChrgToPcWkndSav_D_Stat 1;
BA_ "U_P702_MY2021_Rx" SG_ 1013 ChrgToPcWkndSav_D_Stat 1;
BA_ "U_T6_MCA_MY2020_Rx" SG_ 1013 ChrgToPcWkdySav_D_Stat 1;
BA_ "U_P702_MY2021_Rx" SG_ 1013 ChrgToPcWkdySav_D_Stat 1;
BA_ "U_T6_MCA_MY2020_Rx" SG_ 1013 ChrgProgIdSaved_D_Stat 1;
BA_ "U_P702_MY2021_Rx" SG_ 1013 ChrgProgIdSaved_D_Stat 1;
BA_ "U_T6_MCA_MY2020_Rx" SG_ 1013 ChrgNowEnbl_B_Saved 1;
BA_ "U_P702_MY2021_Rx" SG_ 1013 ChrgNowEnbl_B_Saved 1;
BA_ "U_T6_MCA_MY2020_Rx" SG_ 1013 ChrgLocIdUnsAck_B_Stat 1;
BA_ "U_P702_MY2021_Rx" SG_ 1013 ChrgLocIdUnsAck_B_Stat 1;
BA_ "U_CD542_MY2021_Rx" SG_ 1013 ChrgLocIdCurnt_D_Sav 1;
BA_ "U_T6_MCA_MY2020_Rx" SG_ 1013 ChrgLocIdCurnt_D_Sav 1;
BA_ "U_P702_MY2021_Rx" SG_ 1013 ChrgLocIdCurnt_D_Sav 1;
BA_ "U_T6_MCA_MY2020_Rx" SG_ 1013 ChrgPrflWknd_No_Actl 1;
BA_ "U_P702_MY2021_Rx" SG_ 1013 ChrgPrflWknd_No_Actl 1;
BA_ "U_T6_MCA_MY2020_Rx" SG_ 1013 ChrgPrflWkdy_No_Actl 1;
BA_ "U_P702_MY2021_Rx" SG_ 1013 ChrgPrflWkdy_No_Actl 1;
BA_ "U_T6_MCA_MY2020_Rx" SG_ 641 ChrgGoTElement_B_Dsply_UB 1;
BA_ "U_P702_MY2021_Rx" SG_ 641 ChrgGoTElement_B_Dsply_UB 1;
BA_ "U_T6_MCA_MY2020_Rx" SG_ 641 ChrgGoTElement_B_Dsply 1;
BA_ "U_P702_MY2021_Rx" SG_ 641 ChrgGoTElement_B_Dsply 1;
BA_ "GenSigSendType" SG_ 641 ChrgGoTElement_B_Dsply 3;
BA_ "U_CD542_MY2021_Rx" SG_ 641 BattChrgTrgtSoC_D_Rq 1;
BA_ "U_T6_MCA_MY2020_Rx" SG_ 641 BattChrgTrgtSoC_D_Rq 1;
BA_ "U_CD542_MY2021_Rx" SG_ 641 BattChrgTrgtSoC_D_Rq_UB 1;
BA_ "U_T6_MCA_MY2020_Rx" SG_ 641 BattChrgTrgtSoC_D_Rq_UB 1;
BA_ "U_T6_MCA_MY2020_Rx" SG_ 641 ChrgLocIdCurnt_D_Uns_UB 1;
BA_ "U_P702_MY2021_Rx" SG_ 641 ChrgLocIdCurnt_D_Uns_UB 1;
BA_ "U_T6_MCA_MY2020_Rx" SG_ 641 ChrgLocIdCurnt_D_Uns 1;
BA_ "U_P702_MY2021_Rx" SG_ 641 ChrgLocIdCurnt_D_Uns 1;
BA_ "GenSigSendType" SG_ 641 ChrgLocIdCurnt_D_Uns 3;
BA_ "U_T6_MCA_MY2020_Rx" SG_ 641 IgnPsswrdActv_B_Stat_UB 1;
BA_ "U_P702_MY2021_Rx" SG_ 641 IgnPsswrdActv_B_Stat_UB 1;
BA_ "U_T6_MCA_MY2020_Rx" SG_ 641 IgnPsswrdSetup_B_Rq_UB 1;
BA_ "U_P702_MY2021_Rx" SG_ 641 IgnPsswrdSetup_B_Rq_UB 1;
BA_ "U_T6_MCA_MY2020_Rx" SG_ 641 IgnPsswrdLckout_B_Stat_UB 1;
BA_ "U_P702_MY2021_Rx" SG_ 641 IgnPsswrdLckout_B_Stat_UB 1;
BA_ "U_T6_MCA_MY2020_Rx" SG_ 641 IgnPsswrdSetup_B_Rq 1;
BA_ "U_P702_MY2021_Rx" SG_ 641 IgnPsswrdSetup_B_Rq 1;
BA_ "GenSigSendType" SG_ 641 IgnPsswrdSetup_B_Rq 3;
BA_ "U_T6_MCA_MY2020_Rx" SG_ 641 IgnPsswrdLckout_B_Stat 1;
BA_ "U_P702_MY2021_Rx" SG_ 641 IgnPsswrdLckout_B_Stat 1;
BA_ "GenSigSendType" SG_ 641 IgnPsswrdLckout_B_Stat 3;
BA_ "U_T6_MCA_MY2020_Rx" SG_ 641 PaakCnnct_D_Stat_UB 1;
BA_ "U_P702_MY2021_Rx" SG_ 641 PaakCnnct_D_Stat_UB 1;
BA_ "U_T6_MCA_MY2020_Rx" SG_ 641 PaakCnnct_D_Stat 1;
BA_ "U_P702_MY2021_Rx" SG_ 641 PaakCnnct_D_Stat 1;
BA_ "GenSigSendType" SG_ 641 PaakCnnct_D_Stat 3;
BA_ "U_T6_MCA_MY2020_Rx" SG_ 641 IgnPsswrdActv_B_Stat 1;
BA_ "U_P702_MY2021_Rx" SG_ 641 IgnPsswrdActv_B_Stat 1;
BA_ "GenSigSendType" SG_ 641 IgnPsswrdActv_B_Stat 3;
BA_ "U_T6_MCA_MY2020_Rx" SG_ 641 ChrgGoTTouch_B_Stat_UB 1;
BA_ "U_P702_MY2021_Rx" SG_ 641 ChrgGoTTouch_B_Stat_UB 1;
BA_ "U_T6_MCA_MY2020_Rx" SG_ 641 ChrgGoTTouch_B_Stat 1;
BA_ "U_P702_MY2021_Rx" SG_ 641 ChrgGoTTouch_B_Stat 1;
BA_ "GenSigSendType" SG_ 641 ChrgGoTTouch_B_Stat 3;
BA_ "U_T6_MCA_MY2020_Rx" SG_ 641 ChrgGoTPrcond_D_Stat_UB 1;
BA_ "U_P702_MY2021_Rx" SG_ 641 ChrgGoTPrcond_D_Stat_UB 1;
BA_ "U_T6_MCA_MY2020_Rx" SG_ 641 ChrgGoTPrcond_D_Stat 1;
BA_ "U_P702_MY2021_Rx" SG_ 641 ChrgGoTPrcond_D_Stat 1;
BA_ "U_T6_MCA_MY2020_Rx" SG_ 641 ChrgGoTNext_D_Stat_UB 1;
BA_ "U_P702_MY2021_Rx" SG_ 641 ChrgGoTNext_D_Stat_UB 1;
BA_ "U_T6_MCA_MY2020_Rx" SG_ 641 ChrgGoTNext_D_Stat 1;
BA_ "U_P702_MY2021_Rx" SG_ 641 ChrgGoTNext_D_Stat 1;
BA_ "GenSigSendType" SG_ 641 ChrgGoTNext_D_Stat 3;
BA_ "U_T6_MCA_MY2020_Rx" SG_ 641 ChrgGoTMnte_D_Stat_UB 1;
BA_ "U_P702_MY2021_Rx" SG_ 641 ChrgGoTMnte_D_Stat_UB 1;
BA_ "U_T6_MCA_MY2020_Rx" SG_ 641 ChrgGoTMnte_D_Stat 1;
BA_ "U_P702_MY2021_Rx" SG_ 641 ChrgGoTMnte_D_Stat 1;
BA_ "U_T6_MCA_MY2020_Rx" SG_ 641 ChrgGoTHr_T_Stat_UB 1;
BA_ "U_P702_MY2021_Rx" SG_ 641 ChrgGoTHr_T_Stat_UB 1;
BA_ "U_T6_MCA_MY2020_Rx" SG_ 641 ChrgGoTHr_T_Stat 1;
BA_ "U_P702_MY2021_Rx" SG_ 641 ChrgGoTHr_T_Stat 1;
BA_ "GenSigStartValue" SG_ 641 ChrgGoTHr_T_Stat 30;
BA_ "GenSigStartValueInteger" SG_ 641 ChrgGoTHr_T_Stat 30;
BA_ "U_T6_MCA_MY2020_Rx" SG_ 641 ChrgGoTExtHtr_B_Stat_UB 1;
BA_ "U_P702_MY2021_Rx" SG_ 641 ChrgGoTExtHtr_B_Stat_UB 1;
BA_ "U_T6_MCA_MY2020_Rx" SG_ 641 ChrgGoTExtHtr_B_Stat 1;
BA_ "U_P702_MY2021_Rx" SG_ 641 ChrgGoTExtHtr_B_Stat 1;
BA_ "GenSigSendType" SG_ 641 ChrgGoTExtHtr_B_Stat 3;
BA_ "U_T6_MCA_MY2020_Rx" SG_ 641 ChrgGoTElement_D_Stat_UB 1;
BA_ "U_P702_MY2021_Rx" SG_ 641 ChrgGoTElement_D_Stat_UB 1;
BA_ "U_T6_MCA_MY2020_Rx" SG_ 641 ChrgGoTElement_D_Stat 1;
BA_ "U_P702_MY2021_Rx" SG_ 641 ChrgGoTElement_D_Stat 1;
BA_ "GenSigSendType" SG_ 641 ChrgGoTElement_D_Stat 3;
BA_ "U_T6_MCA_MY2020_Rx" SG_ 641 ChrgGoTAllOn_B_Stat_UB 1;
BA_ "U_P702_MY2021_Rx" SG_ 641 ChrgGoTAllOn_B_Stat_UB 1;
BA_ "U_T6_MCA_MY2020_Rx" SG_ 641 ChrgGoTAllOn_B_Stat 1;
BA_ "U_P702_MY2021_Rx" SG_ 641 ChrgGoTAllOn_B_Stat 1;
BA_ "GenSigSendType" SG_ 641 ChrgGoTAllOn_B_Stat 3;
BA_ "U_CD542_MY2021_Rx" SG_ 641 TrlrAidMsgTxt_D2_Rq 1;
BA_ "U_T6_MCA_MY2020_Rx" SG_ 641 TrlrAidMsgTxt_D2_Rq 1;
BA_ "U_P702_MY2021_Rx" SG_ 641 TrlrAidMsgTxt_D2_Rq 1;
BA_ "GenSigSendType" SG_ 641 TrlrAidMsgTxt_D2_Rq 3;
BA_ "U_P702_MY2021_Rx" SG_ 641 TrlrAidEnbl_D2_Stat 1;
BA_ "U_CD542_MY2021_Rx" SG_ 641 TrlrAidEnbl_D2_Stat 1;
BA_ "U_T6_MCA_MY2020_Rx" SG_ 641 TrlrAidEnbl_D2_Stat 1;
BA_ "GenSigSendType" SG_ 641 TrlrAidEnbl_D2_Stat 3;
BA_ "U_CD542_MY2021_Rx" SG_ 641 TrlrAidMsgTxt_D2_Rq_UB 1;
BA_ "U_T6_MCA_MY2020_Rx" SG_ 641 TrlrAidMsgTxt_D2_Rq_UB 1;
BA_ "U_P702_MY2021_Rx" SG_ 641 TrlrAidMsgTxt_D2_Rq_UB 1;
BA_ "U_P702_MY2021_Rx" SG_ 641 TrlrAidEnbl_D2_Stat_UB 1;
BA_ "U_CD542_MY2021_Rx" SG_ 641 TrlrAidEnbl_D2_Stat_UB 1;
BA_ "U_T6_MCA_MY2020_Rx" SG_ 641 TrlrAidEnbl_D2_Stat_UB 1;
BA_ "U_CD542_MY2021_Rx" SG_ 1012 ChrgLocSaved_B_Dsply 1;
BA_ "U_T6_MCA_MY2020_Rx" SG_ 1012 ChrgLocSaved_B_Dsply 1;
BA_ "U_P702_MY2021_Rx" SG_ 1012 ChrgLocSaved_B_Dsply 1;
BA_ "U_T6_MCA_MY2020_Rx" SG_ 1012 ChrgLocLongPostv_B_Sav 1;
BA_ "U_P702_MY2021_Rx" SG_ 1012 ChrgLocLongPostv_B_Sav 1;
BA_ "U_T6_MCA_MY2020_Rx" SG_ 1012 ChrgLocLongFrct_An_Sav 1;
BA_ "U_P702_MY2021_Rx" SG_ 1012 ChrgLocLongFrct_An_Sav 1;
BA_ "GenSigStartValue" SG_ 1012 ChrgLocLongFrct_An_Sav 1048575;
BA_ "GenSigStartValueInteger" SG_ 1012 ChrgLocLongFrct_An_Sav 1048575;
BA_ "U_T6_MCA_MY2020_Rx" SG_ 1012 ChrgLocLongDeg_An_Sav 1;
BA_ "U_P702_MY2021_Rx" SG_ 1012 ChrgLocLongDeg_An_Sav 1;
BA_ "U_T6_MCA_MY2020_Rx" SG_ 1012 ChrgLocLattPostv_B_Sav 1;
BA_ "U_P702_MY2021_Rx" SG_ 1012 ChrgLocLattPostv_B_Sav 1;
BA_ "U_T6_MCA_MY2020_Rx" SG_ 1012 ChrgLocLattFrct_An_Sav 1;
BA_ "U_P702_MY2021_Rx" SG_ 1012 ChrgLocLattFrct_An_Sav 1;
BA_ "GenSigStartValue" SG_ 1012 ChrgLocLattFrct_An_Sav 1048575;
BA_ "GenSigStartValueInteger" SG_ 1012 ChrgLocLattFrct_An_Sav 1048575;
BA_ "U_T6_MCA_MY2020_Rx" SG_ 1012 ChrgLocLattDeg_An_Sav 1;
BA_ "U_P702_MY2021_Rx" SG_ 1012 ChrgLocLattDeg_An_Sav 1;
BA_ "U_T6_MCA_MY2020_Rx" SG_ 1012 ChrgLocId_D_Sav 1;
BA_ "U_P702_MY2021_Rx" SG_ 1012 ChrgLocId_D_Sav 1;
BA_ "U_CD542_MY2021_Rx" SG_ 1012 ChrgNowCurnt_B_Dsply 1;
BA_ "U_T6_MCA_MY2020_Rx" SG_ 1012 ChrgNowCurnt_B_Dsply 1;
BA_ "U_P702_MY2021_Rx" SG_ 1012 ChrgNowCurnt_B_Dsply 1;
BA_ "U_CD542_MY2021_Rx" SG_ 1011 ChrgLocLongPostv_B_Uns 1;
BA_ "U_T6_MCA_MY2020_Rx" SG_ 1011 ChrgLocLongPostv_B_Uns 1;
BA_ "U_P702_MY2021_Rx" SG_ 1011 ChrgLocLongPostv_B_Uns 1;
BA_ "U_CD542_MY2021_Rx" SG_ 1011 ChrgLocLongFrct_An_Uns 1;
BA_ "U_T6_MCA_MY2020_Rx" SG_ 1011 ChrgLocLongFrct_An_Uns 1;
BA_ "U_P702_MY2021_Rx" SG_ 1011 ChrgLocLongFrct_An_Uns 1;
BA_ "GenSigStartValue" SG_ 1011 ChrgLocLongFrct_An_Uns 1048575;
BA_ "GenSigStartValueInteger" SG_ 1011 ChrgLocLongFrct_An_Uns 1048575;
BA_ "U_CD542_MY2021_Rx" SG_ 1011 ChrgLocLongDeg_An_Uns 1;
BA_ "U_T6_MCA_MY2020_Rx" SG_ 1011 ChrgLocLongDeg_An_Uns 1;
BA_ "U_P702_MY2021_Rx" SG_ 1011 ChrgLocLongDeg_An_Uns 1;
BA_ "U_CD542_MY2021_Rx" SG_ 1011 ChrgLocLattPostv_B_Uns 1;
BA_ "U_T6_MCA_MY2020_Rx" SG_ 1011 ChrgLocLattPostv_B_Uns 1;
BA_ "U_P702_MY2021_Rx" SG_ 1011 ChrgLocLattPostv_B_Uns 1;
BA_ "U_CD542_MY2021_Rx" SG_ 1011 ChrgLocLattFrct_An_Uns 1;
BA_ "U_T6_MCA_MY2020_Rx" SG_ 1011 ChrgLocLattFrct_An_Uns 1;
BA_ "U_P702_MY2021_Rx" SG_ 1011 ChrgLocLattFrct_An_Uns 1;
BA_ "GenSigStartValue" SG_ 1011 ChrgLocLattFrct_An_Uns 1048575;
BA_ "GenSigStartValueInteger" SG_ 1011 ChrgLocLattFrct_An_Uns 1048575;
BA_ "U_CD542_MY2021_Rx" SG_ 1011 ChrgLocLattDeg_An_Uns 1;
BA_ "U_T6_MCA_MY2020_Rx" SG_ 1011 ChrgLocLattDeg_An_Uns 1;
BA_ "U_P702_MY2021_Rx" SG_ 1011 ChrgLocLattDeg_An_Uns 1;
BA_ "U_CD542_MY2021_Rx" SG_ 1011 ChrgLocId_D_Uns 1;
BA_ "U_T6_MCA_MY2020_Rx" SG_ 1011 ChrgLocId_D_Uns 1;
BA_ "U_P702_MY2021_Rx" SG_ 1011 ChrgLocId_D_Uns 1;
BA_ "U_CD542_MY2021_Tx" SG_ 533 AutoEpbZoomView_B_Stat 1;
BA_ "U_T6_MCA_MY2020_Tx" SG_ 533 AutoEpbZoomView_B_Stat 1;
BA_ "GenSigSendType" SG_ 533 AutoEpbZoomView_B_Stat 3;
BA_ "U_CD542_MY2021_Tx" SG_ 533 PaakMyKey_D_Rq 1;
BA_ "U_T6_MCA_MY2020_Tx" SG_ 533 PaakMyKey_D_Rq 1;
BA_ "U_P702_MY2021_Tx" SG_ 533 PaakMyKey_D_Rq 1;
BA_ "GenSigSendType" SG_ 533 PaakMyKey_D_Rq 3;
BA_ "U_CD542_MY2021_Tx" SG_ 533 AutoEpbButtn_B_Stat 1;
BA_ "U_T6_MCA_MY2020_Tx" SG_ 533 AutoEpbButtn_B_Stat 1;
BA_ "GenSigSendType" SG_ 533 AutoEpbButtn_B_Stat 3;
BA_ "U_CD542_MY2021_Tx" SG_ 533 TrlrAidMde_D_Rq 1;
BA_ "U_T6_MCA_MY2020_Tx" SG_ 533 TrlrAidMde_D_Rq 1;
BA_ "U_P702_MY2021_Tx" SG_ 533 TrlrAidMde_D_Rq 1;
BA_ "GenSigSendType" SG_ 533 TrlrAidMde_D_Rq 3;
BA_ "U_CD542_MY2021_Tx" SG_ 533 TCU_Init_Actvtn_St 1;
BA_ "U_T6_MCA_MY2020_Tx" SG_ 533 TCU_Init_Actvtn_St 1;
BA_ "U_P702_MY2021_Tx" SG_ 533 TCU_Init_Actvtn_St 1;
BA_ "GenSigSendType" SG_ 533 TCU_Init_Actvtn_St 3;
BA_ "U_CD542_MY2021_Tx" SG_ 533 TCU_Final_Actvtn_St 1;
BA_ "U_T6_MCA_MY2020_Tx" SG_ 533 TCU_Final_Actvtn_St 1;
BA_ "U_P702_MY2021_Tx" SG_ 533 TCU_Final_Actvtn_St 1;
BA_ "GenSigSendType" SG_ 533 TCU_Final_Actvtn_St 3;
BA_ "GenSigSendType" SG_ 533 DcacPw_D_Rq 3;
BA_ "GenSigSendType" SG_ 533 DcacPwReset_B_Rq 3;
BA_ "U_CD542_MY2021_Tx" SG_ 533 LghtAmbDrvMde_D_Rq 1;
BA_ "U_T6_MCA_MY2020_Tx" SG_ 533 LghtAmbDrvMde_D_Rq 1;
BA_ "GenSigSendType" SG_ 533 LghtAmbDrvMde_D_Rq 3;
BA_ "WakeupSignal" SG_ 533 LghtAmbDrvMde_D_Rq 1;
BA_ "U_CD542_MY2021_Tx" SG_ 533 OtaTrg_D_Stat 1;
BA_ "U_T6_MCA_MY2020_Tx" SG_ 533 OtaTrg_D_Stat 1;
BA_ "U_P702_MY2021_Tx" SG_ 533 OtaTrg_D_Stat 1;
BA_ "GenSigSendType" SG_ 533 OtaTrg_D_Stat 3;
BA_ "U_CD542_MY2021_Tx" SG_ 533 DcacPwLoButtn_B_Stat 1;
BA_ "U_T6_MCA_MY2020_Tx" SG_ 533 DcacPwLoButtn_B_Stat 1;
BA_ "GenSigSendType" SG_ 533 DcacPwLoButtn_B_Stat 3;
BA_ "U_CD542_MY2021_Tx" SG_ 533 DcacPwOffButtn_B_Stat 1;
BA_ "U_T6_MCA_MY2020_Tx" SG_ 533 DcacPwOffButtn_B_Stat 1;
BA_ "GenSigSendType" SG_ 533 DcacPwOffButtn_B_Stat 3;
BA_ "U_CD542_MY2021_Tx" SG_ 533 DcacPwHiButtn_B_Stat 1;
BA_ "U_T6_MCA_MY2020_Tx" SG_ 533 DcacPwHiButtn_B_Stat 1;
BA_ "GenSigSendType" SG_ 533 DcacPwHiButtn_B_Stat 3;
BA_ "U_CD542_MY2021_Tx" SG_ 533 DcacPwResetButtn_B_Stat 1;
BA_ "U_T6_MCA_MY2020_Tx" SG_ 533 DcacPwResetButtn_B_Stat 1;
BA_ "GenSigSendType" SG_ 533 DcacPwResetButtn_B_Stat 3;
BA_ "U_CD542_MY2021_Tx" SG_ 533 DcacPwButtn_B_Falt 1;
BA_ "U_T6_MCA_MY2020_Tx" SG_ 533 DcacPwButtn_B_Falt 1;
BA_ "GenSigSendType" SG_ 533 DcacPwButtn_B_Falt 3;
BA_ "U_CD542_MY2021_Tx" SG_ 533 OnbChrgGoTTouch_D_Rq 1;
BA_ "U_T6_MCA_MY2020_Tx" SG_ 533 OnbChrgGoTTouch_D_Rq 1;
BA_ "U_P702_MY2021_Tx" SG_ 533 OnbChrgGoTTouch_D_Rq 1;
BA_ "GenSigSendType" SG_ 533 OnbChrgGoTTouch_D_Rq 3;
BA_ "U_CD542_MY2021_Tx" SG_ 533 OnbChrgGoTPrcond_D_Rq 1;
BA_ "U_T6_MCA_MY2020_Tx" SG_ 533 OnbChrgGoTPrcond_D_Rq 1;
BA_ "U_P702_MY2021_Tx" SG_ 533 OnbChrgGoTPrcond_D_Rq 1;
BA_ "GenSigSendType" SG_ 533 OnbChrgGoTPrcond_D_Rq 3;
BA_ "U_CD542_MY2021_Tx" SG_ 533 OnbChrgGoTOn_D_Rq 1;
BA_ "U_T6_MCA_MY2020_Tx" SG_ 533 OnbChrgGoTOn_D_Rq 1;
BA_ "U_P702_MY2021_Tx" SG_ 533 OnbChrgGoTOn_D_Rq 1;
BA_ "GenSigSendType" SG_ 533 OnbChrgGoTOn_D_Rq 3;
BA_ "GenSigStartValue" SG_ 533 OnbChrgGoTOn_D_Rq 2;
BA_ "GenSigStartValueInteger" SG_ 533 OnbChrgGoTOn_D_Rq 2;
BA_ "U_CD542_MY2021_Tx" SG_ 533 OnbChrgGoTMnte_D_Rq 1;
BA_ "U_T6_MCA_MY2020_Tx" SG_ 533 OnbChrgGoTMnte_D_Rq 1;
BA_ "U_P702_MY2021_Tx" SG_ 533 OnbChrgGoTMnte_D_Rq 1;
BA_ "U_CD542_MY2021_Tx" SG_ 533 OnbChrgGoTHr_T_Rq 1;
BA_ "U_T6_MCA_MY2020_Tx" SG_ 533 OnbChrgGoTHr_T_Rq 1;
BA_ "U_P702_MY2021_Tx" SG_ 533 OnbChrgGoTHr_T_Rq 1;
BA_ "GenSigStartValue" SG_ 533 OnbChrgGoTHr_T_Rq 30;
BA_ "GenSigStartValueInteger" SG_ 533 OnbChrgGoTHr_T_Rq 30;
BA_ "U_CD542_MY2021_Tx" SG_ 533 OnbChrgGoTExtHtr_D_Rq 1;
BA_ "U_T6_MCA_MY2020_Tx" SG_ 533 OnbChrgGoTExtHtr_D_Rq 1;
BA_ "U_P702_MY2021_Tx" SG_ 533 OnbChrgGoTExtHtr_D_Rq 1;
BA_ "GenSigSendType" SG_ 533 OnbChrgGoTExtHtr_D_Rq 3;
BA_ "U_CD542_MY2021_Tx" SG_ 533 OnbChrgGoTElement_D_Rq 1;
BA_ "U_T6_MCA_MY2020_Tx" SG_ 533 OnbChrgGoTElement_D_Rq 1;
BA_ "U_P702_MY2021_Tx" SG_ 533 OnbChrgGoTElement_D_Rq 1;
BA_ "GenSigSendType" SG_ 533 OnbChrgGoTElement_D_Rq 3;
BA_ "U_CD542_MY2021_Tx" SG_ 533 OnbChrgGoTDelete_B_Rq 1;
BA_ "U_T6_MCA_MY2020_Tx" SG_ 533 OnbChrgGoTDelete_B_Rq 1;
BA_ "U_P702_MY2021_Tx" SG_ 533 OnbChrgGoTDelete_B_Rq 1;
BA_ "GenSigSendType" SG_ 533 OnbChrgGoTDelete_B_Rq 3;
BA_ "U_CD542_MY2021_Tx" SG_ 533 OnbChrgClearAll_B_Rq 1;
BA_ "U_T6_MCA_MY2020_Tx" SG_ 533 OnbChrgClearAll_B_Rq 1;
BA_ "U_P702_MY2021_Tx" SG_ 533 OnbChrgClearAll_B_Rq 1;
BA_ "GenSigSendType" SG_ 533 OnbChrgClearAll_B_Rq 3;
BA_ "U_CD542_MY2021_Tx" SG_ 533 OnbChrgGoTUpdate_B_Rq 1;
BA_ "U_T6_MCA_MY2020_Tx" SG_ 533 OnbChrgGoTUpdate_B_Rq 1;
BA_ "U_P702_MY2021_Tx" SG_ 533 OnbChrgGoTUpdate_B_Rq 1;
BA_ "U_U55X_MY2022_Rx" SG_ 533 OnbChrgGoTUpdate_B_Rq 1;
BA_ "ECGUsedRxSignal" SG_ 533 OnbChrgGoTUpdate_B_Rq 1;
BA_ "U_T6_MCA_MY2020_Rx" SG_ 533 OnbChrgGoTUpdate_B_Rq 1;
BA_ "GenSigSendType" SG_ 533 OnbChrgGoTUpdate_B_Rq 3;
BA_ "U_T6_MCA_MY2020_Tx" SG_ 533 TrlrAlarmButtn_B_Stat 1;
BA_ "U_T6_MCA_MY2020_Rx" SG_ 533 TrlrAlarmButtn_B_Stat 1;
BA_ "GenSigSendType" SG_ 533 TrlrAlarmButtn_B_Stat 3;
BA_ "U_CD542_MY2021_Tx" SG_ 533 DcacMdeButtn_B_Stat 1;
BA_ "U_T6_MCA_MY2020_Tx" SG_ 533 DcacMdeButtn_B_Stat 1;
BA_ "GenSigSendType" SG_ 533 DcacMdeButtn_B_Stat 3;
BA_ "U_CD542_MY2021_Tx" SG_ 533 DcacGfciTestBttn_B_Stat 1;
BA_ "U_T6_MCA_MY2020_Tx" SG_ 533 DcacGfciTestBttn_B_Stat 1;
BA_ "GenSigSendType" SG_ 533 DcacGfciTestBttn_B_Stat 3;
BA_ "U_CD542_MY2021_Tx" SG_ 533 TrlrBrkGain_No_Rq 1;
BA_ "U_T6_MCA_MY2020_Tx" SG_ 533 TrlrBrkGain_No_Rq 1;
BA_ "U_T6_MCA_MY2020_Rx" SG_ 533 TrlrBrkGain_No_Rq 1;
BA_ "GenSigSendType" SG_ 533 TrlrBrkGain_No_Rq 3;
BA_ "U_CD542_MY2021_Tx" SG_ 533 TrlrHitch_D_RqMnu 1;
BA_ "U_T6_MCA_MY2020_Tx" SG_ 533 TrlrHitch_D_RqMnu 1;
BA_ "GenSigSendType" SG_ 533 TrlrHitch_D_RqMnu 3;
BA_ "U_CD542_MY2021_Tx" SG_ 533 DcacPwButtn_B_Stat 1;
BA_ "U_T6_MCA_MY2020_Tx" SG_ 533 DcacPwButtn_B_Stat 1;
BA_ "GenSigSendType" SG_ 533 DcacPwButtn_B_Stat 3;
BA_ "U_CD542_MY2021_Rx" SG_ 1184 APIM_TCU_Word_Rx 1;
BA_ "U_T6_MCA_MY2020_Rx" SG_ 1184 APIM_TCU_Word_Rx 1;
BA_ "U_P702_MY2021_Rx" SG_ 1184 APIM_TCU_Word_Rx 1;
BA_ "U_CD542_MY2021_Tx" SG_ 801 CDWarnChime_St 1;
BA_ "U_T6_MCA_MY2020_Tx" SG_ 801 CDWarnChime_St 1;
BA_ "U_P702_MY2021_Tx" SG_ 801 CDWarnChime_St 1;
BA_ "U_CD542_MY2021_Rx" SG_ 801 CDWarnChime_St 1;
BA_ "U_T6_MCA_MY2020_Rx" SG_ 801 CDWarnChime_St 1;
BA_ "GenSigSendType" SG_ 801 CDWarnChime_St 3;
BA_ "U_CD542_MY2021_Tx" SG_ 801 SoftWarning 1;
BA_ "U_T6_MCA_MY2020_Tx" SG_ 801 SoftWarning 1;
BA_ "U_P702_MY2021_Tx" SG_ 801 SoftWarning 1;
BA_ "U_T6_MCA_MY2020_Rx" SG_ 801 SoftWarning 1;
BA_ "GenSigSendType" SG_ 801 SoftWarning 3;
BA_ "U_CD542_MY2021_Tx" SG_ 801 HardWarning 1;
BA_ "U_T6_MCA_MY2020_Tx" SG_ 801 HardWarning 1;
BA_ "U_P702_MY2021_Tx" SG_ 801 HardWarning 1;
BA_ "U_T6_MCA_MY2020_Rx" SG_ 801 HardWarning 1;
BA_ "GenSigSendType" SG_ 801 HardWarning 3;
BA_ "U_CD542_MY2021_Tx" SG_ 801 InfoWarning 1;
BA_ "U_T6_MCA_MY2020_Tx" SG_ 801 InfoWarning 1;
BA_ "U_P702_MY2021_Tx" SG_ 801 InfoWarning 1;
BA_ "U_T6_MCA_MY2020_Rx" SG_ 801 InfoWarning 1;
BA_ "GenSigSendType" SG_ 801 InfoWarning 3;
BA_ "U_CD542_MY2021_Tx" SG_ 801 DrvDsplyPalette_D_Stat 1;
BA_ "U_T6_MCA_MY2020_Rx" SG_ 801 DrvDsplyPalette_D_Stat 1;
BA_ "GenSigSendType" SG_ 801 DrvDsplyPalette_D_Stat 3;
BA_ "GenSigSendType" SG_ 878 ClimtSyncRear2_B_Stat 3;
BA_ "GenSigSendType" SG_ 878 ClimtStHeatRr2_B_Stat 3;
BA_ "GenSigSendType" SG_ 878 ClimtStHeatRl2_B_Stat 3;
BA_ "GenSigSendType" SG_ 878 ClimtStCoolRr2_B_Stat 3;
BA_ "GenSigSendType" SG_ 878 ClimtStCoolRl2_B_Stat 3;
BA_ "GenSigSendType" SG_ 878 ClimtSeatRr2_D_Rq 3;
BA_ "GenSigSendType" SG_ 878 ClimtSeatRl2_D_Rq 3;
BA_ "GenSigSendType" SG_ 878 ClimtRrTe3rd2_D_Stat 3;
BA_ "GenSigSendType" SG_ 878 ClimtRrPw3rd2_B_Stat 3;
BA_ "GenSigSendType" SG_ 878 ClimtRrPnl3rd2_B_Stat 3;
BA_ "GenSigSendType" SG_ 878 ClimtRrPf3rd2_B_Stat 3;
BA_ "GenSigSendType" SG_ 878 ClimtRrFlr3rd2_B_Stat 3;
BA_ "GenSigSendType" SG_ 878 ClimtRrBlwr3rd2_D_Stat 3;
BA_ "GenSigSendType" SG_ 878 ClimtRrAuto3rd2_B_Stat 3;
BA_ "GenSigSendType" SG_ 878 ClimtRearView2_D_Stat 3;
BA_ "GenSigSendType" SG_ 878 ClimtRearTe2_D_Stat 3;
BA_ "GenSigSendType" SG_ 878 ClimtRearTe2_An_Actl 3;
BA_ "GenSigStartValue" SG_ 878 ClimtRearTe2_An_Actl 511;
BA_ "GenSigStartValueInteger" SG_ 878 ClimtRearTe2_An_Actl 511;
BA_ "GenSigSendType" SG_ 878 ClimtRearPw2_B_Stat 3;
BA_ "GenSigSendType" SG_ 878 ClimtRearPnlFlr2_B_Stat 3;
BA_ "GenSigSendType" SG_ 878 ClimtRearPnl2_B_Stat 3;
BA_ "GenSigSendType" SG_ 878 ClimtRearFlr2_B_Stat 3;
BA_ "GenSigSendType" SG_ 878 ClimtRearBlwr2_D_Stat 3;
BA_ "GenSigSendType" SG_ 878 ClimtRearBlwr2_An_Actl 3;
BA_ "GenSigStartValue" SG_ 878 ClimtRearBlwr2_An_Actl 511;
BA_ "GenSigStartValueInteger" SG_ 878 ClimtRearBlwr2_An_Actl 511;
BA_ "GenSigSendType" SG_ 878 ClimtRearAuto2_B_Stat 3;
BA_ "U_CD542_MY2021_Rx" SG_ 258 GPS_Track_D_Rq 1;
BA_ "U_T6_MCA_MY2020_Rx" SG_ 258 GPS_Track_D_Rq 1;
BA_ "U_P702_MY2021_Rx" SG_ 258 GPS_Track_D_Rq 1;
BA_ "U_CD542_MY2021_Rx" SG_ 258 APIM_SwPartNo_D_Rq 1;
BA_ "U_T6_MCA_MY2020_Rx" SG_ 258 APIM_SwPartNo_D_Rq 1;
BA_ "U_P702_MY2021_Rx" SG_ 258 APIM_SwPartNo_D_Rq 1;
BA_ "U_CD542_MY2021_Rx" SG_ 258 TCU_Init_Actvtn_Rq 1;
BA_ "U_T6_MCA_MY2020_Rx" SG_ 258 TCU_Init_Actvtn_Rq 1;
BA_ "U_P702_MY2021_Rx" SG_ 258 TCU_Init_Actvtn_Rq 1;
BA_ "U_CD542_MY2021_Rx" SG_ 258 TCU_Final_Actvtn_Rq 1;
BA_ "U_T6_MCA_MY2020_Rx" SG_ 258 TCU_Final_Actvtn_Rq 1;
BA_ "U_P702_MY2021_Rx" SG_ 258 TCU_Final_Actvtn_Rq 1;
BA_ "U_CD542_MY2021_Tx" SG_ 1192 APIM_TCU_Word_Tx 1;
BA_ "U_T6_MCA_MY2020_Tx" SG_ 1192 APIM_TCU_Word_Tx 1;
BA_ "U_P702_MY2021_Tx" SG_ 1192 APIM_TCU_Word_Tx 1;
BA_ "U_CD542_MY2021_Tx" SG_ 259 SDARS_CurrCATlstSize_Rq 1;
BA_ "U_T6_MCA_MY2020_Tx" SG_ 259 SDARS_CurrCATlstSize_Rq 1;
BA_ "U_P702_MY2021_Tx" SG_ 259 SDARS_CurrCATlstSize_Rq 1;
BA_ "U_CD542_MY2021_Rx" SG_ 259 SDARS_CurrCATlstSize_Rq 1;
BA_ "U_T6_MCA_MY2020_Rx" SG_ 259 SDARS_CurrCATlstSize_Rq 1;
BA_ "U_P702_MY2021_Rx" SG_ 259 SDARS_CurrCATlstSize_Rq 1;
BA_ "U_CD542_MY2021_Tx" SG_ 259 SDARS_CurrCATlistInd_Rq 1;
BA_ "U_T6_MCA_MY2020_Tx" SG_ 259 SDARS_CurrCATlistInd_Rq 1;
BA_ "U_P702_MY2021_Tx" SG_ 259 SDARS_CurrCATlistInd_Rq 1;
BA_ "U_CD542_MY2021_Rx" SG_ 259 SDARS_CurrCATlistInd_Rq 1;
BA_ "U_T6_MCA_MY2020_Rx" SG_ 259 SDARS_CurrCATlistInd_Rq 1;
BA_ "U_P702_MY2021_Rx" SG_ 259 SDARS_CurrCATlistInd_Rq 1;
BA_ "GenSigSendType" SG_ 259 SDARS_CurrCATlistInd_Rq 3;
BA_ "U_CD542_MY2021_Tx" SG_ 259 SDARS_ChipControl_Rq 1;
BA_ "U_T6_MCA_MY2020_Tx" SG_ 259 SDARS_ChipControl_Rq 1;
BA_ "U_P702_MY2021_Tx" SG_ 259 SDARS_ChipControl_Rq 1;
BA_ "U_CD542_MY2021_Rx" SG_ 259 SDARS_ChipControl_Rq 1;
BA_ "U_T6_MCA_MY2020_Rx" SG_ 259 SDARS_ChipControl_Rq 1;
BA_ "U_P702_MY2021_Rx" SG_ 259 SDARS_ChipControl_Rq 1;
BA_ "GenSigSendType" SG_ 259 SDARS_ChipControl_Rq 3;
BA_ "U_CD542_MY2021_Tx" SG_ 259 SDARS_AlertStatus_Rq 1;
BA_ "U_T6_MCA_MY2020_Tx" SG_ 259 SDARS_AlertStatus_Rq 1;
BA_ "U_P702_MY2021_Tx" SG_ 259 SDARS_AlertStatus_Rq 1;
BA_ "U_CD542_MY2021_Rx" SG_ 259 SDARS_AlertStatus_Rq 1;
BA_ "U_T6_MCA_MY2020_Rx" SG_ 259 SDARS_AlertStatus_Rq 1;
BA_ "U_P702_MY2021_Rx" SG_ 259 SDARS_AlertStatus_Rq 1;
BA_ "GenSigSendType" SG_ 259 SDARS_AlertStatus_Rq 3;
BA_ "U_CD542_MY2021_Tx" SG_ 538 MK_UserMyKeyCount_St 1;
BA_ "U_T6_MCA_MY2020_Tx" SG_ 538 MK_UserMyKeyCount_St 1;
BA_ "U_T6_MCA_MY2020_Rx" SG_ 538 MK_UserMyKeyCount_St 1;
BA_ "U_P702_MY2021_Rx" SG_ 538 MK_UserMyKeyCount_St 1;
BA_ "GenSigSendType" SG_ 538 MK_UserMyKeyCount_St 3;
BA_ "U_CD542_MY2021_Tx" SG_ 538 MK_SpeedMinderConf_St 1;
BA_ "U_T6_MCA_MY2020_Tx" SG_ 538 MK_SpeedMinderConf_St 1;
BA_ "U_T6_MCA_MY2020_Rx" SG_ 538 MK_SpeedMinderConf_St 1;
BA_ "U_P702_MY2021_Rx" SG_ 538 MK_SpeedMinderConf_St 1;
BA_ "GenSigSendType" SG_ 538 MK_SpeedMinderConf_St 3;
BA_ "U_CD542_MY2021_Tx" SG_ 538 MK_SpeedLimitConf_St 1;
BA_ "U_T6_MCA_MY2020_Tx" SG_ 538 MK_SpeedLimitConf_St 1;
BA_ "U_T6_MCA_MY2020_Rx" SG_ 538 MK_SpeedLimitConf_St 1;
BA_ "U_P702_MY2021_Rx" SG_ 538 MK_SpeedLimitConf_St 1;
BA_ "GenSigSendType" SG_ 538 MK_SpeedLimitConf_St 3;
BA_ "U_CD542_MY2021_Tx" SG_ 538 MK_ESCRestrictConf_St 1;
BA_ "U_T6_MCA_MY2020_Tx" SG_ 538 MK_ESCRestrictConf_St 1;
BA_ "GenSigSendType" SG_ 538 MK_ESCRestrictConf_St 3;
BA_ "U_CD542_MY2021_Tx" SG_ 538 MK_ECalRestrictConf_St 1;
BA_ "U_T6_MCA_MY2020_Tx" SG_ 538 MK_ECalRestrictConf_St 1;
BA_ "U_T6_MCA_MY2020_Rx" SG_ 538 MK_ECalRestrictConf_St 1;
BA_ "U_P702_MY2021_Rx" SG_ 538 MK_ECalRestrictConf_St 1;
BA_ "GenSigSendType" SG_ 538 MK_ECalRestrictConf_St 3;
BA_ "U_CD542_MY2021_Tx" SG_ 538 MK_DNDRestrictConf_St 1;
BA_ "U_T6_MCA_MY2020_Tx" SG_ 538 MK_DNDRestrictConf_St 1;
BA_ "U_T6_MCA_MY2020_Rx" SG_ 538 MK_DNDRestrictConf_St 1;
BA_ "U_P702_MY2021_Rx" SG_ 538 MK_DNDRestrictConf_St 1;
BA_ "GenSigSendType" SG_ 538 MK_DNDRestrictConf_St 3;
BA_ "U_CD542_MY2021_Tx" SG_ 538 MK_AudioLimitConfig_St 1;
BA_ "U_T6_MCA_MY2020_Tx" SG_ 538 MK_AudioLimitConfig_St 1;
BA_ "U_T6_MCA_MY2020_Rx" SG_ 538 MK_AudioLimitConfig_St 1;
BA_ "U_P702_MY2021_Rx" SG_ 538 MK_AudioLimitConfig_St 1;
BA_ "GenSigSendType" SG_ 538 MK_AudioLimitConfig_St 3;
BA_ "U_CD542_MY2021_Tx" SG_ 538 MK_AdminMyKeyCount_St 1;
BA_ "U_T6_MCA_MY2020_Tx" SG_ 538 MK_AdminMyKeyCount_St 1;
BA_ "U_T6_MCA_MY2020_Rx" SG_ 538 MK_AdminMyKeyCount_St 1;
BA_ "U_P702_MY2021_Rx" SG_ 538 MK_AdminMyKeyCount_St 1;
BA_ "GenSigSendType" SG_ 538 MK_AdminMyKeyCount_St 3;
BA_ "U_CD542_MY2021_Tx" SG_ 422 MK_UserMyKeyCount_Rsp 1;
BA_ "U_T6_MCA_MY2020_Tx" SG_ 422 MK_UserMyKeyCount_Rsp 1;
BA_ "U_T6_MCA_MY2020_Rx" SG_ 422 MK_UserMyKeyCount_Rsp 1;
BA_ "U_P702_MY2021_Rx" SG_ 422 MK_UserMyKeyCount_Rsp 1;
BA_ "GenSigSendType" SG_ 422 MK_UserMyKeyCount_Rsp 3;
BA_ "U_CD542_MY2021_Tx" SG_ 422 MK_MyKeyDrivenKm_Rsp 1;
BA_ "U_T6_MCA_MY2020_Tx" SG_ 422 MK_MyKeyDrivenKm_Rsp 1;
BA_ "U_T6_MCA_MY2020_Rx" SG_ 422 MK_MyKeyDrivenKm_Rsp 1;
BA_ "U_P702_MY2021_Rx" SG_ 422 MK_MyKeyDrivenKm_Rsp 1;
BA_ "U_CD542_MY2021_Tx" SG_ 422 MK_CreateMyKey_Rsp 1;
BA_ "U_T6_MCA_MY2020_Tx" SG_ 422 MK_CreateMyKey_Rsp 1;
BA_ "U_T6_MCA_MY2020_Rx" SG_ 422 MK_CreateMyKey_Rsp 1;
BA_ "U_P702_MY2021_Rx" SG_ 422 MK_CreateMyKey_Rsp 1;
BA_ "GenSigSendType" SG_ 422 MK_CreateMyKey_Rsp 3;
BA_ "U_CD542_MY2021_Tx" SG_ 422 MK_AdminMyKeyCount_Rsp 1;
BA_ "U_T6_MCA_MY2020_Tx" SG_ 422 MK_AdminMyKeyCount_Rsp 1;
BA_ "U_T6_MCA_MY2020_Rx" SG_ 422 MK_AdminMyKeyCount_Rsp 1;
BA_ "U_P702_MY2021_Rx" SG_ 422 MK_AdminMyKeyCount_Rsp 1;
BA_ "GenSigSendType" SG_ 422 MK_AdminMyKeyCount_Rsp 3;
BA_ "U_CD542_MY2021_Tx" SG_ 2008 TesterPhysicalResAPIM 1;
BA_ "U_T6_MCA_MY2020_Tx" SG_ 2008 TesterPhysicalResAPIM 1;
BA_ "U_P702_MY2021_Tx" SG_ 2008 TesterPhysicalResAPIM 1;
BA_ "GenSigSendType" SG_ 2008 TesterPhysicalResAPIM 3;
BA_ "U_CD542_MY2021_Rx" SG_ 884 PmSnsCabn_D_Stat 1;
BA_ "U_T6_MCA_MY2020_Rx" SG_ 884 PmSnsCabn_D_Stat 1;
BA_ "U_P702_MY2021_Rx" SG_ 884 PmSnsCabn_D_Stat 1;
BA_ "GenSigStartValue" SG_ 884 PmSnsCabn_D_Stat 5;
BA_ "GenSigStartValueInteger" SG_ 884 PmSnsCabn_D_Stat 5;
BA_ "U_CD542_MY2021_Rx" SG_ 884 PmCabn_Conc_Actl 1;
BA_ "U_T6_MCA_MY2020_Rx" SG_ 884 PmCabn_Conc_Actl 1;
BA_ "U_P702_MY2021_Rx" SG_ 884 PmCabn_Conc_Actl 1;
BA_ "GenSigStartValue" SG_ 884 PmCabn_Conc_Actl 510;
BA_ "GenSigStartValueInteger" SG_ 884 PmCabn_Conc_Actl 510;
BA_ "U_CD542_MY2021_Rx" SG_ 884 PmCabn20Mnte_Conc_Actl 1;
BA_ "U_T6_MCA_MY2020_Rx" SG_ 884 PmCabn20Mnte_Conc_Actl 1;
BA_ "U_P702_MY2021_Rx" SG_ 884 PmCabn20Mnte_Conc_Actl 1;
BA_ "GenSigStartValue" SG_ 884 PmCabn20Mnte_Conc_Actl 510;
BA_ "GenSigStartValueInteger" SG_ 884 PmCabn20Mnte_Conc_Actl 510;
BA_ "U_CD542_MY2021_Rx" SG_ 884 PmCabn18Mnte_Conc_Actl 1;
BA_ "U_T6_MCA_MY2020_Rx" SG_ 884 PmCabn18Mnte_Conc_Actl 1;
BA_ "U_P702_MY2021_Rx" SG_ 884 PmCabn18Mnte_Conc_Actl 1;
BA_ "GenSigStartValue" SG_ 884 PmCabn18Mnte_Conc_Actl 510;
BA_ "GenSigStartValueInteger" SG_ 884 PmCabn18Mnte_Conc_Actl 510;
BA_ "U_CD542_MY2021_Rx" SG_ 884 PmCabn16Mnte_Conc_Actl 1;
BA_ "U_T6_MCA_MY2020_Rx" SG_ 884 PmCabn16Mnte_Conc_Actl 1;
BA_ "U_P702_MY2021_Rx" SG_ 884 PmCabn16Mnte_Conc_Actl 1;
BA_ "GenSigStartValue" SG_ 884 PmCabn16Mnte_Conc_Actl 510;
BA_ "GenSigStartValueInteger" SG_ 884 PmCabn16Mnte_Conc_Actl 510;
BA_ "U_CD542_MY2021_Rx" SG_ 884 PmCabn14Mnte_Conc_Actl 1;
BA_ "U_T6_MCA_MY2020_Rx" SG_ 884 PmCabn14Mnte_Conc_Actl 1;
BA_ "U_P702_MY2021_Rx" SG_ 884 PmCabn14Mnte_Conc_Actl 1;
BA_ "GenSigStartValue" SG_ 884 PmCabn14Mnte_Conc_Actl 510;
BA_ "GenSigStartValueInteger" SG_ 884 PmCabn14Mnte_Conc_Actl 510;
BA_ "U_CD542_MY2021_Rx" SG_ 884 PmCabn12Mnte_Conc_Actl 1;
BA_ "U_T6_MCA_MY2020_Rx" SG_ 884 PmCabn12Mnte_Conc_Actl 1;
BA_ "U_P702_MY2021_Rx" SG_ 884 PmCabn12Mnte_Conc_Actl 1;
BA_ "GenSigStartValue" SG_ 884 PmCabn12Mnte_Conc_Actl 510;
BA_ "GenSigStartValueInteger" SG_ 884 PmCabn12Mnte_Conc_Actl 510;
BA_ "U_CD542_MY2021_Rx" SG_ 883 PmCabn10Mnte_Conc_Actl 1;
BA_ "U_T6_MCA_MY2020_Rx" SG_ 883 PmCabn10Mnte_Conc_Actl 1;
BA_ "U_P702_MY2021_Rx" SG_ 883 PmCabn10Mnte_Conc_Actl 1;
BA_ "GenSigStartValue" SG_ 883 PmCabn10Mnte_Conc_Actl 510;
BA_ "GenSigStartValueInteger" SG_ 883 PmCabn10Mnte_Conc_Actl 510;
BA_ "U_CD542_MY2021_Rx" SG_ 883 PmCabn08Mnte_Conc_Actl 1;
BA_ "U_T6_MCA_MY2020_Rx" SG_ 883 PmCabn08Mnte_Conc_Actl 1;
BA_ "U_P702_MY2021_Rx" SG_ 883 PmCabn08Mnte_Conc_Actl 1;
BA_ "GenSigStartValue" SG_ 883 PmCabn08Mnte_Conc_Actl 510;
BA_ "GenSigStartValueInteger" SG_ 883 PmCabn08Mnte_Conc_Actl 510;
BA_ "U_CD542_MY2021_Rx" SG_ 883 PmCabn06Mnte_Conc_Actl 1;
BA_ "U_T6_MCA_MY2020_Rx" SG_ 883 PmCabn06Mnte_Conc_Actl 1;
BA_ "U_P702_MY2021_Rx" SG_ 883 PmCabn06Mnte_Conc_Actl 1;
BA_ "GenSigStartValue" SG_ 883 PmCabn06Mnte_Conc_Actl 510;
BA_ "GenSigStartValueInteger" SG_ 883 PmCabn06Mnte_Conc_Actl 510;
BA_ "U_CD542_MY2021_Rx" SG_ 883 PmCabn04Mnte_Conc_Actl 1;
BA_ "U_T6_MCA_MY2020_Rx" SG_ 883 PmCabn04Mnte_Conc_Actl 1;
BA_ "U_P702_MY2021_Rx" SG_ 883 PmCabn04Mnte_Conc_Actl 1;
BA_ "GenSigStartValue" SG_ 883 PmCabn04Mnte_Conc_Actl 510;
BA_ "GenSigStartValueInteger" SG_ 883 PmCabn04Mnte_Conc_Actl 510;
BA_ "U_CD542_MY2021_Rx" SG_ 883 PmCabn02Mnte_Conc_Actl 1;
BA_ "U_T6_MCA_MY2020_Rx" SG_ 883 PmCabn02Mnte_Conc_Actl 1;
BA_ "U_P702_MY2021_Rx" SG_ 883 PmCabn02Mnte_Conc_Actl 1;
BA_ "GenSigStartValue" SG_ 883 PmCabn02Mnte_Conc_Actl 510;
BA_ "GenSigStartValueInteger" SG_ 883 PmCabn02Mnte_Conc_Actl 510;
BA_ "U_CD542_MY2021_Rx" SG_ 1090 VehElRnge_L_Dsply 1;
BA_ "U_T6_MCA_MY2020_Rx" SG_ 1090 VehElRnge_L_Dsply 1;
BA_ "GenSigStartValue" SG_ 1090 VehElRnge_L_Dsply 4093;
BA_ "GenSigStartValueInteger" SG_ 1090 VehElRnge_L_Dsply 4095;
BA_ "GenSigStartValue" SG_ 1090 Inv1Ain_I_ActlMntr 32765;
BA_ "GenSigStartValueInteger" SG_ 1090 Inv1Ain_I_ActlMntr 32766;
BA_ "GenSigSendType" SG_ 677 SeatFnPsgr_D_Rq3 3;
BA_ "GenSigSendType" SG_ 677 SeatFnDrv_D_Rq3 3;
BA_ "GenSigSendType" SG_ 677 SeatMasgPsngrRr_D_Rq2 3;
BA_ "GenSigSendType" SG_ 677 SeatMasgDrvRr_D_Rq2 3;
BA_ "GenSigSendType" SG_ 677 SeatFnChngPsgr2_D_Rq3 3;
BA_ "GenSigSendType" SG_ 677 SeatFnChngDrv2_D_Rq3 3;
BA_ "ECGUsedTxSignal" SG_ 2609971416 OTAPhysGWM_ECGtoWCM 1;
BA_ "GenSigSendType" SG_ 2609971416 OTAPhysGWM_ECGtoWCM 3;
BA_ "ECGUsedRxSignal" SG_ 2610126912 OTAPhysWCMtoGWM_ECG 1;
BA_ "GenSigSendType" SG_ 2610126912 OTAPhysWCMtoGWM_ECG 3;
BA_ "ECGUsedTxSignal" SG_ 2611019992 PARSEDPhysGWM_ECGtoWCM 1;
BA_ "GenSigSendType" SG_ 2611019992 PARSEDPhysGWM_ECGtoWCM 3;
BA_ "ECGUsedRxSignal" SG_ 2611175488 PARSEDPhysWCMtoGWM_ECG 1;
BA_ "GenSigSendType" SG_ 2611175488 PARSEDPhysWCMtoGWM_ECG 3;
BA_ "ECGUsedTxSignal" SG_ 2612068568 PARSEDPushFcGWM_ECGtoWCM 1;
BA_ "GenSigSendType" SG_ 2612068568 PARSEDPushFcGWM_ECGtoWCM 3;
BA_ "ECGUsedRxSignal" SG_ 2612224064 PARSEDPushFcwcmtoGWM_ECG 1;
BA_ "GenSigSendType" SG_ 2612224064 PARSEDPushFcwcmtoGWM_ECG 3;
BA_ "GenSigSendType" SG_ 557 AudioToneTouchY_D_Stat 3;
BA_ "GenSigSendType" SG_ 557 AudioToneTouchX_D_Stat 3;
BA_ "GenSigSendType" SG_ 557 AudioToneTouch_D_Stat 3;
BA_ "GenSigStartValue" SG_ 1236 ApaSlotRearX_L_Actl 1048;
BA_ "GenSigStartValue" SG_ 1236 ApaSlotRight3X_L_Actl 1048;
BA_ "GenSigStartValue" SG_ 1236 ApaSlotRight2X_L_Actl 1048;
BA_ "GenSigStartValue" SG_ 1236 ApaSlotRight1X_L_Actl 1048;
BA_ "GenSigStartValue" SG_ 1236 ApaSlotRearY_L_Actl 29.0909090909091;
BA_ "GenSigStartValue" SG_ 1235 ApaSlotLeft3X_L_Actl 1048;
BA_ "GenSigStartValue" SG_ 1235 ApaSlotFrontX_L_Actl 1048;
BA_ "GenSigStartValue" SG_ 1235 ApaSlotFrontY_L_Actl 32;
BA_ "GenSigStartValue" SG_ 1235 ApaSlotLeft2X_L_Actl 1048;
BA_ "GenSigStartValue" SG_ 1235 ApaSlotLeft1X_L_Actl 1048;
BA_ "GenSigStartValue" SG_ 1234 RmtCtlConfgSrc_D_Stat 1;
BA_ "U_T6_MCA_MY2020_Rx" SG_ 976 VehLong2_A_Actl_UB 1;
BA_ "U_P702_MY2021_Rx" SG_ 976 VehLong2_A_Actl_UB 1;
BA_ "U_T6_MCA_MY2020_Rx" SG_ 976 VehLong2_A_Actl 1;
BA_ "U_P702_MY2021_Rx" SG_ 976 VehLong2_A_Actl 1;
BA_ "GenSigStartValue" SG_ 976 VehLong2_A_Actl 8190;
BA_ "GenSigStartValueInteger" SG_ 976 VehLong2_A_Actl 8190;
BA_ "U_CD542_MY2021_Tx" SG_ 715 RDISP_SSP_WORD_Rx 1;
BA_ "U_T6_MCA_MY2020_Tx" SG_ 715 RDISP_SSP_WORD_Rx 1;
BA_ "U_P702_MY2021_Tx" SG_ 715 RDISP_SSP_WORD_Rx 1;
BA_ "U_CD542_MY2021_Rx" SG_ 715 RDISP_SSP_WORD_Rx 1;
BA_ "U_T6_MCA_MY2020_Rx" SG_ 715 RDISP_SSP_WORD_Rx 1;
BA_ "U_P702_MY2021_Rx" SG_ 715 RDISP_SSP_WORD_Rx 1;
BA_ "GenSigStartValue" SG_ 925 TripSumDrvE_Pc_Dsply 1022;
BA_ "GenSigStartValueInteger" SG_ 925 TripSumDrvE_Pc_Dsply 1022;
BA_ "GenSigStartValue" SG_ 925 TripExtFctrE_Pc_Dsply 1022;
BA_ "GenSigStartValueInteger" SG_ 925 TripExtFctrE_Pc_Dsply 1022;
BA_ "GenSigStartValue" SG_ 925 TripClimE_Pc_Dsply 1022;
BA_ "GenSigStartValueInteger" SG_ 925 TripClimE_Pc_Dsply 1022;
BA_ "GenSigStartValue" SG_ 925 TripBattULoE_Pc_Dsply 1022;
BA_ "GenSigStartValueInteger" SG_ 925 TripBattULoE_Pc_Dsply 1022;
BA_ "GenSigStartValue" SG_ 788 EcoCochDecel2_Pc_Dsply 255;
BA_ "GenSigStartValueInteger" SG_ 788 EcoCochDecel2_Pc_Dsply 255;
BA_ "GenSigStartValue" SG_ 788 EcoCochDecel1_Pc_Dsply 255;
BA_ "GenSigStartValueInteger" SG_ 788 EcoCochDecel1_Pc_Dsply 255;
BA_ "GenSigStartValue" SG_ 788 EcoCochCrus2_Pc_Dsply 255;
BA_ "GenSigStartValueInteger" SG_ 788 EcoCochCrus2_Pc_Dsply 255;
BA_ "GenSigStartValue" SG_ 788 EcoCochCrus1_Pc_Dsply 255;
BA_ "GenSigStartValueInteger" SG_ 788 EcoCochCrus1_Pc_Dsply 255;
BA_ "GenSigStartValue" SG_ 788 EcoCochATrip2_Pc_Dsply 255;
BA_ "GenSigStartValueInteger" SG_ 788 EcoCochATrip2_Pc_Dsply 255;
BA_ "GenSigStartValue" SG_ 788 EcoCochATrip1_Pc_Dsply 255;
BA_ "GenSigStartValueInteger" SG_ 788 EcoCochATrip1_Pc_Dsply 255;
BA_ "U_CD542_MY2021_Tx" SG_ 473 NAV_StorePreset2_Rq 1;
BA_ "U_T6_MCA_MY2020_Tx" SG_ 473 NAV_StorePreset2_Rq 1;
BA_ "U_CD542_MY2021_Rx" SG_ 473 NAV_StorePreset2_Rq 1;
BA_ "U_T6_MCA_MY2020_Rx" SG_ 473 NAV_StorePreset2_Rq 1;
BA_ "GenSigSendType" SG_ 473 NAV_StorePreset2_Rq 3;
BA_ "U_CD542_MY2021_Tx" SG_ 473 NAV_SetAFMode_Rq 1;
BA_ "U_T6_MCA_MY2020_Tx" SG_ 473 NAV_SetAFMode_Rq 1;
BA_ "U_P702_MY2021_Tx" SG_ 473 NAV_SetAFMode_Rq 1;
BA_ "U_CD542_MY2021_Rx" SG_ 473 NAV_SetAFMode_Rq 1;
BA_ "U_T6_MCA_MY2020_Rx" SG_ 473 NAV_SetAFMode_Rq 1;
BA_ "GenSigSendType" SG_ 473 NAV_SetAFMode_Rq 3;
BA_ "U_CD542_MY2021_Tx" SG_ 473 NAV_StorePreset_Rq 1;
BA_ "U_T6_MCA_MY2020_Tx" SG_ 473 NAV_StorePreset_Rq 1;
BA_ "U_P702_MY2021_Tx" SG_ 473 NAV_StorePreset_Rq 1;
BA_ "U_CD542_MY2021_Rx" SG_ 473 NAV_StorePreset_Rq 1;
BA_ "U_T6_MCA_MY2020_Rx" SG_ 473 NAV_StorePreset_Rq 1;
BA_ "GenSigSendType" SG_ 473 NAV_StorePreset_Rq 3;
BA_ "U_CD542_MY2021_Tx" SG_ 473 HMI_StorePreset2_Rq 1;
BA_ "U_T6_MCA_MY2020_Tx" SG_ 473 HMI_StorePreset2_Rq 1;
BA_ "U_P702_MY2021_Tx" SG_ 473 HMI_StorePreset2_Rq 1;
BA_ "U_CD542_MY2021_Rx" SG_ 473 HMI_StorePreset2_Rq 1;
BA_ "U_T6_MCA_MY2020_Rx" SG_ 473 HMI_StorePreset2_Rq 1;
BA_ "U_P702_MY2021_Rx" SG_ 473 HMI_StorePreset2_Rq 1;
BA_ "GenSigSendType" SG_ 473 HMI_StorePreset2_Rq 3;
BA_ "U_CD542_MY2021_Tx" SG_ 473 NAV_SetTUServiceLink_Rq 1;
BA_ "U_T6_MCA_MY2020_Tx" SG_ 473 NAV_SetTUServiceLink_Rq 1;
BA_ "U_CD542_MY2021_Rx" SG_ 473 NAV_SetTUServiceLink_Rq 1;
BA_ "U_T6_MCA_MY2020_Rx" SG_ 473 NAV_SetTUServiceLink_Rq 1;
BA_ "GenSigSendType" SG_ 473 NAV_SetTUServiceLink_Rq 3;
BA_ "U_CD542_MY2021_Tx" SG_ 473 NAV_SetTAMode_Rq 1;
BA_ "U_T6_MCA_MY2020_Tx" SG_ 473 NAV_SetTAMode_Rq 1;
BA_ "U_CD542_MY2021_Rx" SG_ 473 NAV_SetTAMode_Rq 1;
BA_ "U_T6_MCA_MY2020_Rx" SG_ 473 NAV_SetTAMode_Rq 1;
BA_ "GenSigSendType" SG_ 473 NAV_SetTAMode_Rq 3;
BA_ "U_CD542_MY2021_Tx" SG_ 473 NAV_SetReg_Rq 1;
BA_ "U_T6_MCA_MY2020_Tx" SG_ 473 NAV_SetReg_Rq 1;
BA_ "U_CD542_MY2021_Rx" SG_ 473 NAV_SetReg_Rq 1;
BA_ "U_T6_MCA_MY2020_Rx" SG_ 473 NAV_SetReg_Rq 1;
BA_ "GenSigSendType" SG_ 473 NAV_SetReg_Rq 3;
BA_ "U_CD542_MY2021_Tx" SG_ 473 NAV_SelectPTYCodeSet_Rq 1;
BA_ "U_T6_MCA_MY2020_Tx" SG_ 473 NAV_SelectPTYCodeSet_Rq 1;
BA_ "U_T6_MCA_MY2020_Rx" SG_ 473 NAV_SelectPTYCodeSet_Rq 1;
BA_ "GenSigSendType" SG_ 473 NAV_SelectPTYCodeSet_Rq 3;
BA_ "U_CD542_MY2021_Tx" SG_ 473 NAV_SelectPTYCodes_Rq 1;
BA_ "U_T6_MCA_MY2020_Tx" SG_ 473 NAV_SelectPTYCodes_Rq 1;
BA_ "U_CD542_MY2021_Rx" SG_ 473 NAV_SelectPTYCodes_Rq 1;
BA_ "U_T6_MCA_MY2020_Rx" SG_ 473 NAV_SelectPTYCodes_Rq 1;
BA_ "U_CD542_MY2021_Tx" SG_ 473 NAV_CDSetShuffle_Rq 1;
BA_ "U_T6_MCA_MY2020_Tx" SG_ 473 NAV_CDSetShuffle_Rq 1;
BA_ "U_T6_MCA_MY2020_Rx" SG_ 473 NAV_CDSetShuffle_Rq 1;
BA_ "GenSigSendType" SG_ 473 NAV_CDSetShuffle_Rq 3;
BA_ "U_CD542_MY2021_Tx" SG_ 473 NAV_CDSetRepeat_Rq 1;
BA_ "U_T6_MCA_MY2020_Tx" SG_ 473 NAV_CDSetRepeat_Rq 1;
BA_ "U_T6_MCA_MY2020_Rx" SG_ 473 NAV_CDSetRepeat_Rq 1;
BA_ "GenSigSendType" SG_ 473 NAV_CDSetRepeat_Rq 3;
BA_ "U_CD542_MY2021_Tx" SG_ 473 NAV_CDSetIntroScan_Rq 1;
BA_ "U_T6_MCA_MY2020_Tx" SG_ 473 NAV_CDSetIntroScan_Rq 1;
BA_ "U_T6_MCA_MY2020_Rx" SG_ 473 NAV_CDSetIntroScan_Rq 1;
BA_ "GenSigSendType" SG_ 473 NAV_CDSetIntroScan_Rq 3;
BA_ "U_CD542_MY2021_Rx" SG_ 2000 TesterPhysicalReqAPIM 1;
BA_ "U_T6_MCA_MY2020_Rx" SG_ 2000 TesterPhysicalReqAPIM 1;
BA_ "U_P702_MY2021_Rx" SG_ 2000 TesterPhysicalReqAPIM 1;
BA_ "GenSigSendType" SG_ 2000 TesterPhysicalReqAPIM 3;
BA_ "U_U55X_MY2022_Tx" SG_ 810 ExtLghtDsply_B_StatArb 1;
BA_ "ECGUsedTxSignal" SG_ 810 ExtLghtDsply_B_StatArb 1;
BA_ "U_T6_MCA_MY2020_Tx" SG_ 810 ExtLghtDsply_B_StatArb 1;
BA_ "U_CD542_MY2021_Rx" SG_ 810 ExtLghtDsply_B_StatArb 1;
BA_ "U_T6_MCA_MY2020_Rx" SG_ 810 ExtLghtDsply_B_StatArb 1;
BA_ "GenSigSendType" SG_ 810 ExtLghtDsply_B_StatArb 3;
BA_ "WakeupSignal" SG_ 810 ExtLghtDsply_B_StatArb 1;
BA_ "U_U55X_MY2022_Tx" SG_ 810 OneTEditActv_B_RqCld 1;
BA_ "ECGUsedTxSignal" SG_ 810 OneTEditActv_B_RqCld 1;
BA_ "U_CD542_MY2021_Rx" SG_ 810 OneTEditActv_B_RqCld 1;
BA_ "U_T6_MCA_MY2020_Rx" SG_ 810 OneTEditActv_B_RqCld 1;
BA_ "GenSigSendType" SG_ 810 OneTEditActv_B_RqCld 3;
BA_ "U_CD542_MY2021_Tx" SG_ 482 SDARS_Firm_Update2_St 1;
BA_ "U_T6_MCA_MY2020_Tx" SG_ 482 SDARS_Firm_Update2_St 1;
BA_ "U_P702_MY2021_Tx" SG_ 482 SDARS_Firm_Update2_St 1;
BA_ "U_CD542_MY2021_Rx" SG_ 482 SDARS_Firm_Update2_St 1;
BA_ "U_T6_MCA_MY2020_Rx" SG_ 482 SDARS_Firm_Update2_St 1;
BA_ "GenSigSendType" SG_ 482 SDARS_Firm_Update2_St 3;
BA_ "U_CD542_MY2021_Tx" SG_ 482 SDARS_UnSubscrb_Chan2_St 1;
BA_ "U_T6_MCA_MY2020_Tx" SG_ 482 SDARS_UnSubscrb_Chan2_St 1;
BA_ "U_P702_MY2021_Tx" SG_ 482 SDARS_UnSubscrb_Chan2_St 1;
BA_ "U_CD542_MY2021_Rx" SG_ 482 SDARS_UnSubscrb_Chan2_St 1;
BA_ "U_T6_MCA_MY2020_Rx" SG_ 482 SDARS_UnSubscrb_Chan2_St 1;
BA_ "GenSigSendType" SG_ 482 SDARS_UnSubscrb_Chan2_St 3;
BA_ "U_CD542_MY2021_Tx" SG_ 482 SDARS_UnSubscrb2_St 1;
BA_ "U_T6_MCA_MY2020_Tx" SG_ 482 SDARS_UnSubscrb2_St 1;
BA_ "U_P702_MY2021_Tx" SG_ 482 SDARS_UnSubscrb2_St 1;
BA_ "U_CD542_MY2021_Rx" SG_ 482 SDARS_UnSubscrb2_St 1;
BA_ "U_T6_MCA_MY2020_Rx" SG_ 482 SDARS_UnSubscrb2_St 1;
BA_ "GenSigSendType" SG_ 482 SDARS_UnSubscrb2_St 3;
BA_ "U_CD542_MY2021_Tx" SG_ 482 SDARS_Subscription2_St 1;
BA_ "U_T6_MCA_MY2020_Tx" SG_ 482 SDARS_Subscription2_St 1;
BA_ "U_P702_MY2021_Tx" SG_ 482 SDARS_Subscription2_St 1;
BA_ "U_CD542_MY2021_Rx" SG_ 482 SDARS_Subscription2_St 1;
BA_ "U_T6_MCA_MY2020_Rx" SG_ 482 SDARS_Subscription2_St 1;
BA_ "GenSigSendType" SG_ 482 SDARS_Subscription2_St 3;
BA_ "U_CD542_MY2021_Tx" SG_ 482 SDARS_Seek_Scan2_St 1;
BA_ "U_T6_MCA_MY2020_Tx" SG_ 482 SDARS_Seek_Scan2_St 1;
BA_ "U_P702_MY2021_Tx" SG_ 482 SDARS_Seek_Scan2_St 1;
BA_ "U_CD542_MY2021_Rx" SG_ 482 SDARS_Seek_Scan2_St 1;
BA_ "U_T6_MCA_MY2020_Rx" SG_ 482 SDARS_Seek_Scan2_St 1;
BA_ "GenSigSendType" SG_ 482 SDARS_Seek_Scan2_St 3;
BA_ "U_CD542_MY2021_Tx" SG_ 482 SDARS_Receive_Err2_St 1;
BA_ "U_T6_MCA_MY2020_Tx" SG_ 482 SDARS_Receive_Err2_St 1;
BA_ "U_P702_MY2021_Tx" SG_ 482 SDARS_Receive_Err2_St 1;
BA_ "U_CD542_MY2021_Rx" SG_ 482 SDARS_Receive_Err2_St 1;
BA_ "U_T6_MCA_MY2020_Rx" SG_ 482 SDARS_Receive_Err2_St 1;
BA_ "GenSigSendType" SG_ 482 SDARS_Receive_Err2_St 3;
BA_ "U_CD542_MY2021_Tx" SG_ 482 SDARS_Loss_Ant2_St 1;
BA_ "U_T6_MCA_MY2020_Tx" SG_ 482 SDARS_Loss_Ant2_St 1;
BA_ "U_P702_MY2021_Tx" SG_ 482 SDARS_Loss_Ant2_St 1;
BA_ "U_CD542_MY2021_Rx" SG_ 482 SDARS_Loss_Ant2_St 1;
BA_ "U_T6_MCA_MY2020_Rx" SG_ 482 SDARS_Loss_Ant2_St 1;
BA_ "GenSigSendType" SG_ 482 SDARS_Loss_Ant2_St 3;
BA_ "U_CD542_MY2021_Tx" SG_ 482 SDARS_Invalid_Chan2_St 1;
BA_ "U_T6_MCA_MY2020_Tx" SG_ 482 SDARS_Invalid_Chan2_St 1;
BA_ "U_P702_MY2021_Tx" SG_ 482 SDARS_Invalid_Chan2_St 1;
BA_ "U_CD542_MY2021_Rx" SG_ 482 SDARS_Invalid_Chan2_St 1;
BA_ "U_T6_MCA_MY2020_Rx" SG_ 482 SDARS_Invalid_Chan2_St 1;
BA_ "GenSigSendType" SG_ 482 SDARS_Invalid_Chan2_St 3;
BA_ "U_CD542_MY2021_Tx" SG_ 482 SDARS_GCI_Update2_St 1;
BA_ "U_T6_MCA_MY2020_Tx" SG_ 482 SDARS_GCI_Update2_St 1;
BA_ "U_P702_MY2021_Tx" SG_ 482 SDARS_GCI_Update2_St 1;
BA_ "U_CD542_MY2021_Rx" SG_ 482 SDARS_GCI_Update2_St 1;
BA_ "U_T6_MCA_MY2020_Rx" SG_ 482 SDARS_GCI_Update2_St 1;
BA_ "GenSigSendType" SG_ 482 SDARS_GCI_Update2_St 3;
BA_ "U_CD542_MY2021_Tx" SG_ 482 SDARS_Error_Conf2_St 1;
BA_ "U_T6_MCA_MY2020_Tx" SG_ 482 SDARS_Error_Conf2_St 1;
BA_ "U_P702_MY2021_Tx" SG_ 482 SDARS_Error_Conf2_St 1;
BA_ "U_CD542_MY2021_Rx" SG_ 482 SDARS_Error_Conf2_St 1;
BA_ "U_T6_MCA_MY2020_Rx" SG_ 482 SDARS_Error_Conf2_St 1;
BA_ "GenSigSendType" SG_ 482 SDARS_Error_Conf2_St 3;
BA_ "U_CD542_MY2021_Tx" SG_ 482 SDARS_Antenna_Err2_St 1;
BA_ "U_T6_MCA_MY2020_Tx" SG_ 482 SDARS_Antenna_Err2_St 1;
BA_ "U_P702_MY2021_Tx" SG_ 482 SDARS_Antenna_Err2_St 1;
BA_ "U_CD542_MY2021_Rx" SG_ 482 SDARS_Antenna_Err2_St 1;
BA_ "U_T6_MCA_MY2020_Rx" SG_ 482 SDARS_Antenna_Err2_St 1;
BA_ "GenSigSendType" SG_ 482 SDARS_Antenna_Err2_St 3;
BA_ "U_CD542_MY2021_Tx" SG_ 764 SDARS_SID2_St 1;
BA_ "U_T6_MCA_MY2020_Tx" SG_ 764 SDARS_SID2_St 1;
BA_ "U_P702_MY2021_Tx" SG_ 764 SDARS_SID2_St 1;
BA_ "U_CD542_MY2021_Rx" SG_ 764 SDARS_SID2_St 1;
BA_ "U_T6_MCA_MY2020_Rx" SG_ 764 SDARS_SID2_St 1;
BA_ "U_P702_MY2021_Rx" SG_ 764 SDARS_SID2_St 1;
BA_ "GenSigSendType" SG_ 764 SDARS_SID2_St 3;
BA_ "U_CD542_MY2021_Tx" SG_ 764 SdarsSampleRate_D_Stat 1;
BA_ "U_T6_MCA_MY2020_Tx" SG_ 764 SdarsSampleRate_D_Stat 1;
BA_ "U_P702_MY2021_Tx" SG_ 764 SdarsSampleRate_D_Stat 1;
BA_ "U_CD542_MY2021_Rx" SG_ 764 SdarsSampleRate_D_Stat 1;
BA_ "U_T6_MCA_MY2020_Rx" SG_ 764 SdarsSampleRate_D_Stat 1;
BA_ "U_P702_MY2021_Rx" SG_ 764 SdarsSampleRate_D_Stat 1;
BA_ "GenSigSendType" SG_ 764 SdarsSampleRate_D_Stat 3;
BA_ "U_CD542_MY2021_Tx" SG_ 764 SdarsBaudRate_D_Stat 1;
BA_ "U_T6_MCA_MY2020_Tx" SG_ 764 SdarsBaudRate_D_Stat 1;
BA_ "U_P702_MY2021_Tx" SG_ 764 SdarsBaudRate_D_Stat 1;
BA_ "U_CD542_MY2021_Rx" SG_ 764 SdarsBaudRate_D_Stat 1;
BA_ "U_T6_MCA_MY2020_Rx" SG_ 764 SdarsBaudRate_D_Stat 1;
BA_ "U_P702_MY2021_Rx" SG_ 764 SdarsBaudRate_D_Stat 1;
BA_ "GenSigSendType" SG_ 764 SdarsBaudRate_D_Stat 3;
BA_ "U_CD542_MY2021_Tx" SG_ 764 SDARS_CurrentChanNum2_St 1;
BA_ "U_T6_MCA_MY2020_Tx" SG_ 764 SDARS_CurrentChanNum2_St 1;
BA_ "U_P702_MY2021_Tx" SG_ 764 SDARS_CurrentChanNum2_St 1;
BA_ "U_CD542_MY2021_Rx" SG_ 764 SDARS_CurrentChanNum2_St 1;
BA_ "U_P702_MY2021_Rx" SG_ 764 SDARS_CurrentChanNum2_St 1;
BA_ "U_T6_MCA_MY2020_Rx" SG_ 764 SDARS_CurrentChanNum2_St 1;
BA_ "GenSigSendType" SG_ 764 SDARS_CurrentChanNum2_St 3;
BA_ "GenSigStartValue" SG_ 764 SDARS_CurrentChanNum2_St 1022;
BA_ "U_CD542_MY2021_Tx" SG_ 764 SDARS_ChannelUpdate_St 1;
BA_ "U_T6_MCA_MY2020_Tx" SG_ 764 SDARS_ChannelUpdate_St 1;
BA_ "U_P702_MY2021_Tx" SG_ 764 SDARS_ChannelUpdate_St 1;
BA_ "U_CD542_MY2021_Rx" SG_ 764 SDARS_ChannelUpdate_St 1;
BA_ "U_T6_MCA_MY2020_Rx" SG_ 764 SDARS_ChannelUpdate_St 1;
BA_ "U_P702_MY2021_Rx" SG_ 764 SDARS_ChannelUpdate_St 1;
BA_ "GenSigSendType" SG_ 764 SDARS_ChannelUpdate_St 3;
BA_ "U_CD542_MY2021_Tx" SG_ 764 SDARS_Channel_Lock2 1;
BA_ "U_T6_MCA_MY2020_Tx" SG_ 764 SDARS_Channel_Lock2 1;
BA_ "U_P702_MY2021_Tx" SG_ 764 SDARS_Channel_Lock2 1;
BA_ "U_CD542_MY2021_Rx" SG_ 764 SDARS_Channel_Lock2 1;
BA_ "U_T6_MCA_MY2020_Rx" SG_ 764 SDARS_Channel_Lock2 1;
BA_ "U_P702_MY2021_Rx" SG_ 764 SDARS_Channel_Lock2 1;
BA_ "GenSigSendType" SG_ 764 SDARS_Channel_Lock2 3;
VAL_ 502 Dsp_FolderContent_Rq 2 "Inactive" 1 "RequestContentFromParentFolderOf" 0 "RequestContentFromParameterFolde" ;
VAL_ 502 Dsp_CutItem2_Rq 3 "Inactive" 2 "ThreeQuarterFromTheBeginningOneQ" 1 "End" 0 "Beginning" ;
VAL_ 502 Dsp_AudioSourceSel2_Rq 4 "Reserved" 3 "USB" 2 "BTAudio" 1 "CD" 0 "Inactive" ;
VAL_ 955 Tire_Temp_RF_Data 255 "NotSupported" 254 "Invalid" ;
VAL_ 955 Tire_Temp_ORR_Data 255 "NotSupported" 254 "Invalid" ;
VAL_ 955 Tire_Temp_OLR_Data 255 "NotSupported" 254 "Invalid" ;
VAL_ 955 Tire_Temp_LF_Data 255 "NotSupported" 254 "Invalid" ;
VAL_ 955 Tire_Temp_IRR_Data 255 "NotSupported" 254 "Invalid" ;
VAL_ 955 Tire_Temp_ILR_Data 255 "NotSupported" 254 "Invalid" ;
VAL_ 1116 TrlrAidSetup_D2_Rq 15 "NotUsed_9" 14 "NotUsed_8" 13 "NotUsed_7" 12 "NotUsed_6" 11 "NotUsed_5" 10 "NotUsed_4" 9 "NotUsed_3" 8 "NotUsed_2" 7 "NotUsed_1" 6 "CompleteSetup" 5 "ReturnToSetup" 4 "StickerNotCircled" 3 "ConfirmSetup" 2 "EndSetup" 1 "BeginSetup" 0 "Inactive" ;
VAL_ 1116 TrlrAidEnbl_D2_Rq 7 "NotUsed_4" 6 "NotUsed_3" 5 "NotUsed_2" 4 "NotUsed_1" 3 "Deactivate" 2 "ActivateTrg" 1 "ActivateTba" 0 "Inactive" ;
VAL_ 1116 TlightTest_D_Mnu 3 "TestEndAcknowledge" 2 "StartTest" 1 "StopTest" 0 "Null" ;
VAL_ 1116 TrlrRvrseCancl_B_Rq 1 "Cancel" 0 "Null" ;
VAL_ 1116 TrlrIdType_D_Stat 3 "Gooseneck" 2 "FifthWheel" 1 "Conventional" 0 "Null" ;
VAL_ 1116 TrlrAnOffstDir_D_Mem 3 "NotUSed" 2 "Right" 1 "Left_or_Center" 0 "Null" ;
VAL_ 1113 TrlrAnOffstDir_D_Calc_UB 1 "Fresh_data" 0 "Unchanged_data" ;
VAL_ 1113 TrlrAnOffst_An_Calc_UB 1 "Fresh_data" 0 "Unchanged_data" ;
VAL_ 1113 TrlrAnCalib_B_Complt_UB 1 "Fresh_data" 0 "Unchanged_data" ;
VAL_ 1113 TrlrAidTrgtId_No_Actl_UB 1 "Fresh_data" 0 "Unchanged_data" ;
VAL_ 1113 TrlrAnCalib_B_Complt 1 "Yes" 0 "No" ;
VAL_ 1113 TrlrAnOffstDir_D_Calc 3 "NotUSed" 2 "Right" 1 "Left_or_Center" 0 "Null" ;
VAL_ 1113 immoSecureIdleMode_UB 1 "Fresh_data" 0 "Unchanged_data" ;
VAL_ 1113 immoSecureIdleMode 3 "NotUsed2" 2 "NotUsed1" 1 "Active" 0 "Inactive" ;
VAL_ 1255 BalrRight4Threat_D_Stat 1 "Yes" 0 "No" ;
VAL_ 1255 BalrRight4Fast_B_Stat 1 "Yes" 0 "No" ;
VAL_ 1255 BalrRight4Dsply_B_Stat 1 "Yes" 0 "No" ;
VAL_ 1254 BalrRight3Threat_D_Stat 1 "Yes" 0 "No" ;
VAL_ 1254 BalrRight3Fast_B_Stat 1 "Yes" 0 "No" ;
VAL_ 1254 BalrRight3Dsply_B_Stat 1 "Yes" 0 "No" ;
VAL_ 1253 BalrRight2Threat_D_Stat 1 "Yes" 0 "No" ;
VAL_ 1253 BalrRight2Fast_B_Stat 1 "Yes" 0 "No" ;
VAL_ 1253 BalrRight2Dsply_B_Stat 1 "Yes" 0 "No" ;
VAL_ 1252 BalrRight1Threat_D_Stat 1 "Yes" 0 "No" ;
VAL_ 1252 BalrRight1Fast_B_Stat 1 "Yes" 0 "No" ;
VAL_ 1252 BalrRight1Dsply_B_Stat 1 "Yes" 0 "No" ;
VAL_ 1251 BalrLeft4Threat_D_Stat 1 "Yes" 0 "No" ;
VAL_ 1251 BalrLeft4Fast_B_Stat 1 "Yes" 0 "No" ;
VAL_ 1251 BalrLeft4Dsply_B_Stat 1 "Yes" 0 "No" ;
VAL_ 1250 BalrLeft3Threat_D_Stat 1 "Yes" 0 "No" ;
VAL_ 1250 BalrLeft3Fast_B_Stat 1 "Yes" 0 "No" ;
VAL_ 1250 BalrLeft3Dsply_B_Stat 1 "Yes" 0 "No" ;
VAL_ 1249 BalrLeft2Threat_D_Stat 1 "Yes" 0 "No" ;
VAL_ 1249 BalrLeft2Fast_B_Stat 1 "Yes" 0 "No" ;
VAL_ 1249 BalrLeft2Dsply_B_Stat 1 "Yes" 0 "No" ;
VAL_ 1248 BalrLeft1Threat_D_Stat 1 "Yes" 0 "No" ;
VAL_ 1248 BalrLeft1Fast_B_Stat 1 "Yes" 0 "No" ;
VAL_ 1248 BalrLeft1Dsply_B_Stat 1 "Yes" 0 "No" ;
VAL_ 1256 BalrMdeRight_D_Stat_UB 1 "Fresh_data" 0 "Unchanged_data" ;
VAL_ 1256 BalrMdeSelRight_B_Stat_UB 1 "Fresh_data" 0 "Unchanged_data" ;
VAL_ 1256 BalrRight_D_Stat_UB 1 "Fresh_data" 0 "Unchanged_data" ;
VAL_ 1256 BalrLckRight_B_Stat_UB 1 "Fresh_data" 0 "Unchanged_data" ;
VAL_ 1256 BalrChimeRight_D_Rq_UB 1 "Fresh_data" 0 "Unchanged_data" ;
VAL_ 1256 BalrSnsRight_D_Falt_UB 1 "Fresh_data" 0 "Unchanged_data" ;
VAL_ 1256 BalrWndwRight_B_Stat_UB 1 "Fresh_data" 0 "Unchanged_data" ;
VAL_ 1256 BalrLckRight_B_Stat 1 "Enable" 0 "Disable" ;
VAL_ 1256 BalrWndwRight_B_Stat 1 "Enable" 0 "Disable" ;
VAL_ 1256 BalrMdeSelRight_B_Stat 1 "Enable" 0 "Disable" ;
VAL_ 1256 BalrSnsRight_D_Falt 3 "Invalid" 2 "SystemFailure" 1 "Blocked" 0 "Clear" ;
VAL_ 1256 BalrChimeRight_D_Rq 3 "NotUsed" 2 "Soft" 1 "Normal" 0 "Off" ;
VAL_ 1256 BalrMdeRight_D_Stat 3 "NotUsed" 2 "High" 1 "Medium" 0 "Low" ;
VAL_ 1256 BalrRight_D_Stat 3 "Inhibited" 2 "Disabled" 1 "On" 0 "Off" ;
VAL_ 1256 BalrWndwLeft_B_Stat_UB 1 "Fresh_data" 0 "Unchanged_data" ;
VAL_ 1256 BalrSnsLeft_D_Falt_UB 1 "Fresh_data" 0 "Unchanged_data" ;
VAL_ 1256 BalrMdeSelLeft_B_Stat_UB 1 "Fresh_data" 0 "Unchanged_data" ;
VAL_ 1256 BalrMdeLeft_D_Stat_UB 1 "Fresh_data" 0 "Unchanged_data" ;
VAL_ 1256 BalrLeft_D_Stat_UB 1 "Fresh_data" 0 "Unchanged_data" ;
VAL_ 1256 BalrLckLeft_B_Stat_UB 1 "Fresh_data" 0 "Unchanged_data" ;
VAL_ 1256 BalrChimeLeft_D_Rq_UB 1 "Fresh_data" 0 "Unchanged_data" ;
VAL_ 1256 BalrLeft_D_Stat 3 "Inhibited" 2 "Disabled" 1 "On" 0 "Off" ;
VAL_ 1256 BalrMdeSelLeft_B_Stat 1 "Enable" 0 "Disable" ;
VAL_ 1256 BalrLckLeft_B_Stat 1 "Enable" 0 "Disable" ;
VAL_ 1256 BalrWndwLeft_B_Stat 1 "Enable" 0 "Disable" ;
VAL_ 1256 BalrMdeLeft_D_Stat 3 "NotUsed" 2 "High" 1 "Medium" 0 "Low" ;
VAL_ 1256 BalrSnsLeft_D_Falt 3 "Invalid" 2 "SystemFailure" 1 "Blocked" 0 "Clear" ;
VAL_ 1256 BalrChimeLeft_D_Rq 3 "NotUsed" 2 "Soft" 1 "Normal" 0 "Off" ;
VAL_ 1256 WakeAlarm2_D_Stat_UB 1 "Fresh_data" 0 "Unchanged_data" ;
VAL_ 1256 WakeAlarm2_D_Stat 3 "PublisherReset" 2 "Wake" 1 "AlarmRunning" 0 "AlarmOff" ;
VAL_ 529 OnbChrgToPcWknd_D_Actl 7 "Percent_50" 6 "Percent_60" 5 "Percent_70" 4 "Percent_80" 3 "Percent_85" 2 "Percent_90" 1 "Percent_95" 0 "Percent_100" ;
VAL_ 529 OnbChrgToPcWkdy_D_Actl 7 "Percent_50" 6 "Percent_60" 5 "Percent_70" 4 "Percent_80" 3 "Percent_85" 2 "Percent_90" 1 "Percent_95" 0 "Percent_100" ;
VAL_ 529 OnbChrgSetNow_D_Rq 3 "NotUsed" 2 "On" 1 "Off" 0 "Null" ;
VAL_ 529 OnbChrgSetDelete_B_Rq 1 "Request" 0 "NoRequest" ;
VAL_ 529 OnbChrgPrflUpdate_B_Rq 1 "Request" 0 "NoRequest" ;
VAL_ 529 OnbChrgLocIdUns_B_Rq 1 "Request" 0 "NoRequest" ;
VAL_ 642 SldrrMsgTxt_D2_Rq_UB 1 "Fresh_data" 0 "Unchanged_data" ;
VAL_ 642 SldrrMsgTxt_D2_Rq 7 "NotUsed_3" 6 "NotUsed_2" 5 "NotUsed_1" 4 "SlidingDrCalibNeeded2" 3 "SlidingDrOpenCltchReleased" 2 "SlidingDrCalibNeeded" 1 "SlidingDrClutchReleased" 0 "Null" ;
VAL_ 642 SldrrChime_D_Rq_UB 1 "Fresh_data" 0 "Unchanged_data" ;
VAL_ 642 SldrrChime_D_Rq 7 "NotUsed3" 6 "NotUsed2" 5 "NotUsed1" 4 "Warning" 3 "WarningRepeated" 2 "Programming" 1 "Operation" 0 "Off" ;
VAL_ 642 SldrlMsgTxt_D2_Rq_UB 1 "Fresh_data" 0 "Unchanged_data" ;
VAL_ 642 SldrlMsgTxt_D2_Rq 7 "NotUsed_3" 6 "NotUsed_2" 5 "NotUsed_1" 4 "SlidingDrCalibNeeded2" 3 "SlidingDrOpenCltchReleased" 2 "SlidingDrCalibNeeded" 1 "SlidingDrClutchReleased" 0 "Null" ;
VAL_ 642 SldrlChime_D_Rq_UB 1 "Fresh_data" 0 "Unchanged_data" ;
VAL_ 642 SldrlChime_D_Rq 7 "NotUsed3" 6 "NotUsed2" 5 "NotUsed1" 4 "Warning" 3 "WarningRepeated" 2 "Programming" 1 "Operation" 0 "Off" ;
VAL_ 642 PaakMyKeySearch_D_Stat_UB 1 "Fresh_data" 0 "Unchanged_data" ;
VAL_ 642 UreaLvlQlty_D_RqDsply_UB 1 "Fresh_data" 0 "Unchanged_data" ;
VAL_ 642 DieslPrtcWarn_D_Rq_UB 1 "Fresh_data" 0 "Unchanged_data" ;
VAL_ 642 UreaQltySysWarn_D_Rq_UB 1 "Fresh_data" 0 "Unchanged_data" ;
VAL_ 642 UreaLvlTxtWarn_D_Rq_UB 1 "Fresh_data" 0 "Unchanged_data" ;
VAL_ 642 UreaLvlQlty_D_RqDsply 7 "NotUsed_5" 6 "NotUsed_4" 5 "NotUsed_3" 4 "NotUsed_2" 3 "NotUsed_1" 2 "FlashChime" 1 "On" 0 "Off" ;
VAL_ 642 UreaLvlTxtWarn_D_Rq 15 "NotUsed_4" 14 "NotUsed_3" 13 "NotUsed_2" 12 "NotUsed_1" 11 "System_Error" 10 "Engine_Idled_See_Manual" 9 "Engine_Idled_Upon_Refuel" 8 "Speed_Limited_To_XX_mph" 7 "XXmph_Max_Upon_Restart" 6 "Speed_Limited_To_YY_mph" 5 "YYmph_Max_Upon_Restart" 4 "SpdLimtd_YYmph_In_XXmiles" 3 "ExFlRange_XXMiles_ScndWarn" 2 "Exh_Fluid_Range_XX_Miles" 1 "Exh_Fluid_Under_Half_Full" 0 "Exh_Fluid_Over_Half_Full" ;
VAL_ 642 UreaQltySysWarn_D_Rq 7 "Undefined" 6 "ZZ_Overrides" 5 "EngineIdled" 4 "Engine_Idle_Upon_Refuel" 3 "SPEED_LIMITED_to_YY_mph" 2 "YY_MPH_MAX_UPON_Restart" 1 "CONTAMINATED_ExhFluid" 0 "NoQualityProblem" ;
VAL_ 642 DieslPrtcWarn_D_Rq 15 "NotUsed_4" 14 "NotUsed_3" 13 "NotUsed_2" 12 "NotUsed_1" 11 "OCR_ExhFilterClean_Stopped" 10 "OCR_ExhFilterCleaned" 9 "RgnOff_AtLimit" 8 "RgnOff_OverLoaded" 7 "RgnOff_Loaded" 6 "Exhaust_Filter_Full" 5 "DPF_OverLimit" 4 "DPF_AtLimit" 3 "ExhFilter_Drive_Completed" 2 "Cleaning_Exhaust_Filter" 1 "DPF_OverLoaded" 0 "DPF_Normal_Operation" ;
VAL_ 642 KeyMyKeyTot_No2_Cnt_UB 1 "Fresh_data" 0 "Unchanged_data" ;
VAL_ 642 KeyAdmnTot_No2_Cnt_UB 1 "Fresh_data" 0 "Unchanged_data" ;
VAL_ 642 DcChrgSrvcRqd_B_Rq_UB 1 "Fresh_data" 0 "Unchanged_data" ;
VAL_ 642 DcChrgSrvcRqd_B_Rq 1 "On" 0 "Off" ;
VAL_ 642 PaakMyKeySearch_D_Stat 7 "PhoneErased" 6 "LockButtonTimeOut" 5 "PressLockButton" 4 "ConfirmHmi" 3 "MyKeyPaakFound" 2 "StandardPaakFound" 1 "NoValidPaakFound" 0 "Null" ;
VAL_ 642 GrdAsstActv_B_Stat_UB 1 "Fresh_data" 0 "Unchanged_data" ;
VAL_ 642 GrdAsstActv_B_Stat 1 "On" 0 "Off" ;
VAL_ 642 TrlrAidTrlrId_No_Rq_UB 1 "Fresh_data" 0 "Unchanged_data" ;
VAL_ 893 RngImpctClim_L_Dsply_UB 1 "Fresh_data" 0 "Unchanged_data" ;
VAL_ 893 RngImpctDrv_L_Dsply_UB 1 "Fresh_data" 0 "Unchanged_data" ;
VAL_ 893 VehElEffAvg_No_Dsply_UB 1 "Fresh_data" 0 "Unchanged_data" ;
VAL_ 893 VehElEffAvg_No_Dsply 127 "Faulty" 126 "NoDataExists" ;
VAL_ 893 TrnAout2_W_ActlUnfilt_UB 1 "Fresh_data" 0 "Unchanged_data" ;
VAL_ 893 TrnAout2_W_ActlUnfilt 65535 "Fault" 65534 "NoDataExists" ;
VAL_ 500 Dsp_GetCDTOCDData_Rq 0 "Inactive" 2 "Off" 1 "TOC" ;
VAL_ 500 Dsp_CutItem_Rq 3 "Inactive" 2 "ThreeQuarterFromTheBeginningOneQ" 1 "End" 0 "Beginning" ;
VAL_ 500 Dsp_AudioSourceSel_Rq 5 "SDCard" 4 "Reserved" 3 "USB" 2 "BTAudio" 1 "CD" 0 "Inactive" ;
VAL_ 503 Dsp_AudioSourceSel3_Rq 3 "USB" 2 "BTAudio" 1 "CD" 0 "Inactive" ;
VAL_ 493 Dsp_StatLiScanCancel_Rq 1 "Cancel" 0 "Inactive" ;
VAL_ 493 Dsp_StationList_Rq 15 "reserved_last" 8 "reserved" 7 "DAB_Service_List" 6 "DAB_Ensemble_Service_List" 5 "Analog_FM_PTY_List" 4 "Analog_and_HD_FM_List" 3 "HD_FM_List" 2 "Analog_FM_List" 1 "Analog_AM_List" 0 "Inactive" ;
VAL_ 493 Dsp_RefreshFlag 1 "True" 0 "False" ;
VAL_ 493 Dsp_AFJump_Rq 2 "Enable" 1 "Inhibit" 0 "Inactive" ;
VAL_ 511 SdarsAudioRtng_D_Rq 3 "NotUsed" 2 "APIMStereoOut" 1 "X40l2SStereoOut" 0 "Null" ;
VAL_ 511 Dsp_TUPresetArea_Rq 13 "reserved" 12 "GetSAT3PresetData" 11 "GetSAT2PresetData" 15 "reserved_last" 10 "GetSAT1PresetData" 9 "GetDAB2PresetData" 8 "GetDAB1PresetData" 7 "GetDAB3PresetData" 6 "GetAmPresetData" 5 "GetAmAstPresetData" 4 "GetFmAstPresetData" 3 "GetFm3PresetData" 2 "GetFm2PresetData" 1 "GetFm1PresetData" 0 "Inactive" ;
VAL_ 511 Dsp_SetCurrTUBand_Rq 13 "reserved1" 12 "DAB3" 11 "SAT3" 10 "SAT2" 15 "reserved_last" 9 "SAT1" 8 "DAB2" 7 "DAB1" 6 "AmAst" 5 "Am" 4 "FmAst" 3 "Fm3" 2 "Fm2" 1 "Fm1" 0 "Inactive" ;
VAL_ 257 MFD_SetTagMode 2 "On" 1 "Off" 0 "Inactive" ;
VAL_ 257 MFD_SetRBDSMode 2 "On" 1 "Off" 0 "Inactive" ;
VAL_ 257 MFD_SetHDModeRq 2 "On" 1 "Off" 0 "Inactive" ;
VAL_ 257 MFD_GetTagInfo 1 "TagInformation" 0 "Inactive" ;
VAL_ 382 EngMnfldChrg_Te_Actl 127 "Faulty" 126 "NoDataExists" ;
VAL_ 382 EngInnrClnt_Te_Actl 127 "Faulty" 126 "NoDataExists" ;
VAL_ 382 DcacOut2_Pw2_Dsply 8191 "Faulty" 8190 "NoDataExists" ;
VAL_ 382 DcacOut1_Pw2_Dsply 8191 "Faulty" 8190 "NoDataExists" ;
VAL_ 877 Rr_Third_Power_Btn_Stt 3 "Unused" 2 "Disabled" 1 "Active" 0 "Enabled_Inactive" ;
VAL_ 877 Rr_Third_Floor_Btn_Stt 3 "Unused" 2 "Disabled" 1 "Active" 0 "Enabled_Inactive" ;
VAL_ 877 Rr_Third_Auto_Btn_Stt 3 "Unused" 2 "Disabled" 1 "Active" 0 "Enabled_Inactive" ;
VAL_ 877 Rr_Lock_Btn_Stt 3 "Unused" 2 "Disabled" 1 "Active" 0 "Enabled_Inactive" ;
VAL_ 877 Rr_RHS_Blower_Indicate 15 "Display_Blank" 14 "14_Indicators_On" 13 "13_Indicators_On" 12 "12_Indicators_On" 11 "11_Indicators_On" 10 "10_Indicators_On" 9 "9_Indicators_On" 8 "8_Indicators_On" 7 "7_Indicators_On" 6 "6_Indicators_On" 5 "5_Indicators_On" 4 "4_Indicators_On" 3 "3_Indicators_On" 2 "2_Indicators_On" 1 "1_Indicator_On" 0 "Indicators_Off" ;
VAL_ 877 Rr_Third_Panel_Btn_Stt 3 "Unused" 2 "Disabled" 1 "Active" 0 "Enabled_Inactive" ;
VAL_ 877 Rr_Synch_Btn_Stt 3 "Unused" 2 "Disabled" 1 "Active" 0 "Enabled_Inactive" ;
VAL_ 877 AAR_Btn_Stt 3 "Unused" 2 "Disabled" 1 "Active" 0 "Enabled_Inactive" ;
VAL_ 877 Heat_Btn_Stt 3 "Unused" 2 "Disabled" 1 "Active" 0 "Enabled_Inactive" ;
VAL_ 414 LBS2_ListStatus 0 "Inactive" 1 "Valid" 2 "Updating" 3 "Reserved" ;
VAL_ 1013 ChrgToPcWkndSav_D_Stat 7 "Percent_50" 6 "Percent_60" 5 "Percent_70" 4 "Percent_80" 3 "Percent_85" 2 "Percent_90" 1 "Percent_95" 0 "Percent_100" ;
VAL_ 1013 ChrgToPcWkdySav_D_Stat 7 "Percent_50" 6 "Percent_60" 5 "Percent_70" 4 "Percent_80" 3 "Percent_85" 2 "Percent_90" 1 "Percent_95" 0 "Percent_100" ;
VAL_ 1013 ChrgNowEnbl_B_Saved 1 "On" 0 "Off" ;
VAL_ 1013 ChrgLocIdUnsAck_B_Stat 1 "Yes" 0 "No" ;
VAL_ 641 ChrgGoTElement_B_Dsply_UB 1 "Fresh_data" 0 "Unchanged_data" ;
VAL_ 641 ChrgGoTElement_B_Dsply 1 "Yes" 0 "No" ;
VAL_ 641 BattChrgTrgtSoC_D_Rq 7 "Percent_50" 6 "Percent_60" 5 "Percent_70" 4 "Percent_80" 3 "Percent_85" 2 "Percent_90" 1 "Percent_95" 0 "Percent_100" ;
VAL_ 641 BattChrgTrgtSoC_D_Rq_UB 1 "Fresh_data" 0 "Unchanged_data" ;
VAL_ 641 ChrgLocIdCurnt_D_Uns_UB 1 "Fresh_data" 0 "Unchanged_data" ;
VAL_ 641 IgnPsswrdActv_B_Stat_UB 1 "Fresh_data" 0 "Unchanged_data" ;
VAL_ 641 IgnPsswrdSetup_B_Rq_UB 1 "Fresh_data" 0 "Unchanged_data" ;
VAL_ 641 IgnPsswrdLckout_B_Stat_UB 1 "Fresh_data" 0 "Unchanged_data" ;
VAL_ 641 IgnPsswrdSetup_B_Rq 1 "Active" 0 "Inactive" ;
VAL_ 641 IgnPsswrdLckout_B_Stat 1 "Active" 0 "Inactive" ;
VAL_ 641 PaakCnnct_D_Stat_UB 1 "Fresh_data" 0 "Unchanged_data" ;
VAL_ 641 PaakCnnct_D_Stat 3 "NotUsed" 2 "Connected" 1 "NotConnected" 0 "Null" ;
VAL_ 641 IgnPsswrdActv_B_Stat 1 "Active" 0 "Inactive" ;
VAL_ 641 ChrgGoTTouch_B_Stat_UB 1 "Fresh_data" 0 "Unchanged_data" ;
VAL_ 641 ChrgGoTTouch_B_Stat 1 "On" 0 "Off" ;
VAL_ 641 ChrgGoTPrcond_D_Stat_UB 1 "Fresh_data" 0 "Unchanged_data" ;
VAL_ 641 ChrgGoTPrcond_D_Stat 3 "High" 2 "Medium" 1 "Low" 0 "Off" ;
VAL_ 641 ChrgGoTNext_D_Stat_UB 1 "Fresh_data" 0 "Unchanged_data" ;
VAL_ 641 ChrgGoTMnte_D_Stat_UB 1 "Fresh_data" 0 "Unchanged_data" ;
VAL_ 641 ChrgGoTMnte_D_Stat 15 "NotUsed_4" 14 "NotUsed_3" 13 "NotUsed_2" 12 "NotUsed_1" 11 "Minute_55" 10 "Minute_50" 9 "Minute_45" 8 "Minute_40" 7 "Minute_35" 6 "Minute_30" 5 "Minute_25" 4 "Minute_20" 3 "Minute_15" 2 "Minute_10" 1 "Minute_5" 0 "Minute_0" ;
VAL_ 641 ChrgGoTHr_T_Stat_UB 1 "Fresh_data" 0 "Unchanged_data" ;
VAL_ 641 ChrgGoTHr_T_Stat 31 "Faulty" 30 "NoDataExists" ;
VAL_ 641 ChrgGoTExtHtr_B_Stat_UB 1 "Fresh_data" 0 "Unchanged_data" ;
VAL_ 641 ChrgGoTExtHtr_B_Stat 1 "On" 0 "Off" ;
VAL_ 641 ChrgGoTElement_D_Stat_UB 1 "Fresh_data" 0 "Unchanged_data" ;
VAL_ 641 ChrgGoTAllOn_B_Stat_UB 1 "Fresh_data" 0 "Unchanged_data" ;
VAL_ 641 ChrgGoTAllOn_B_Stat 1 "On" 0 "Off" ;
VAL_ 641 TrlrAidMsgTxt_D2_Rq 63 "Message63" 62 "Message62" 61 "Message61" 60 "Message60" 55 "Message55" 50 "Message50" 45 "Message45" 40 "Message40" 35 "Message35" 31 "Message31" 30 "Message30" 29 "Message29" 28 "Message28" 27 "Message27" 26 "Message26" 25 "Message25" 24 "Message24" 23 "Message23" 22 "Message22" 21 "Message21" 20 "Message20" 19 "Message19" 18 "Message18" 17 "Message17" 16 "Message16" 15 "Message15" 14 "Message14" 13 "Message13" 12 "Message12" 11 "Message11" 10 "Message10" 9 "Message9" 8 "Message8" 7 "Message7" 6 "Message6" 5 "Message5" 4 "Message4" 3 "Message3" 2 "Message2" 1 "Message1" 0 "NoMessage" ;
VAL_ 641 TrlrAidEnbl_D2_Stat 7 "NotUsed_1" 6 "TbaActiveExpertActive" 5 "TbaActiveExpertAvail" 4 "TbaOffTrgActive" 3 "TbaOffTrgSetup" 2 "TbaSetup" 1 "TbaActive" 0 "Inactive" ;
VAL_ 641 TrlrAidMsgTxt_D2_Rq_UB 1 "Fresh_data" 0 "Unchanged_data" ;
VAL_ 641 TrlrAidEnbl_D2_Stat_UB 1 "Fresh_data" 0 "Unchanged_data" ;
VAL_ 1012 ChrgLocSaved_B_Dsply 1 "Yes" 0 "No" ;
VAL_ 1012 ChrgLocLongPostv_B_Sav 1 "Yes" 0 "No" ;
VAL_ 1012 ChrgLocLattPostv_B_Sav 1 "Yes" 0 "No" ;
VAL_ 1012 AirCondRec_B_RqVehEl 1 "Yes" 0 "No" ;
VAL_ 1012 ChrgNowCurnt_B_Dsply 1 "On" 0 "Off" ;
VAL_ 1011 ChrgLocLongPostv_B_Uns 1 "Yes" 0 "No" ;
VAL_ 1011 ChrgLocLattPostv_B_Uns 1 "Yes" 0 "No" ;
VAL_ 1011 VehShutDownMsgTxt_D_Rq 3 "NotUsed" 2 "ProhibitedRestart" 1 "ShutdownWarning" 0 "NoMessage" ;
VAL_ 533 AutoEpbZoomView_B_Stat 1 "Active" 0 "Inactive" ;
VAL_ 533 PaakMyKey_D_Rq 3 "NotUsed" 2 "ConfirmNewPaakMyKey" 1 "RequestNewPaakMyKey" 0 "None" ;
VAL_ 533 AutoEpbButtn_B_Stat 1 "Pressed" 0 "Not_Pressed" ;
VAL_ 533 TrlrAidMde_D_Rq 3 "Mode_3" 2 "Mode_2" 1 "Mode_1" 0 "NoRequest" ;
VAL_ 533 TCU_Init_Actvtn_St 3 "NotUsed" 2 "InitialActivateDeny" 1 "InitialActivateAccept" 0 "Invalid" ;
VAL_ 533 TCU_Final_Actvtn_St 3 "NotUsed" 2 "FinalActivateDeny" 1 "FinalActivateAccept" 0 "Invalid" ;
VAL_ 533 DcacPw_D_Rq 3 "High" 2 "Low" 1 "Off" 0 "Null" ;
VAL_ 533 DcacPwReset_B_Rq 1 "Reset" 0 "Null" ;
VAL_ 533 LghtAmbDrvMde_D_Rq 3 "NotUsed" 2 "Automatic" 1 "Manual" 0 "Null" ;
VAL_ 533 OtaTrg_D_Stat 3 "NotUsed_1" 2 "Accepted" 1 "NotAccepted" 0 "Null" ;
VAL_ 533 DcacPwLoButtn_B_Stat 1 "Pressed" 0 "Not_Pressed" ;
VAL_ 533 DcacPwOffButtn_B_Stat 1 "Pressed" 0 "Not_Pressed" ;
VAL_ 533 DcacPwHiButtn_B_Stat 1 "Pressed" 0 "Not_Pressed" ;
VAL_ 533 DcacPwResetButtn_B_Stat 1 "Pressed" 0 "Not_Pressed" ;
VAL_ 533 DcacPwButtn_B_Falt 1 "Faulted" 0 "NotFaulted" ;
VAL_ 533 OnbChrgGoTTouch_D_Rq 3 "NotUsed" 2 "On" 1 "Off" 0 "Null" ;
VAL_ 533 OnbChrgGoTPrcond_D_Rq 3 "High" 2 "Medium" 1 "Low" 0 "Off" ;
VAL_ 533 OnbChrgGoTOn_D_Rq 3 "NotUsed" 2 "On" 1 "Off" 0 "Null" ;
VAL_ 533 OnbChrgGoTMnte_D_Rq 15 "NotUsed_4" 14 "NotUsed_3" 13 "NotUsed_2" 12 "NotUsed_1" 11 "Minute_55" 10 "Minute_50" 9 "Minute_45" 8 "Minute_40" 7 "Minute_35" 6 "Minute_30" 5 "Minute_25" 4 "Minute_20" 3 "Minute_15" 2 "Minute_10" 1 "Minute_5" 0 "Minute_0" ;
VAL_ 533 OnbChrgGoTHr_T_Rq 31 "Faulty" 30 "NoDataExists" ;
VAL_ 533 OnbChrgGoTExtHtr_D_Rq 3 "NotUsed" 2 "On" 1 "Off" 0 "Null" ;
VAL_ 533 OnbChrgGoTDelete_B_Rq 1 "Request" 0 "NoRequest" ;
VAL_ 533 OnbChrgClearAll_B_Rq 1 "Request" 0 "NoRequest" ;
VAL_ 533 OnbChrgGoTUpdate_B_Rq 1 "Request" 0 "NoRequest" ;
VAL_ 533 TrlrAlarmButtn_B_Stat 1 "On" 0 "Off" ;
VAL_ 533 DcacMdeButtn_B_Stat 1 "Pressed" 0 "Not_Pressed" ;
VAL_ 533 DcacGfciTestBttn_B_Stat 1 "Pressed" 0 "Not_Pressed" ;
VAL_ 533 TrlrHitch_D_RqMnu 15 "NotUsed_10" 14 "NotUsed_9" 13 "NotUsed_8" 12 "NotUsed_7" 11 "NotUsed_6" 10 "NotUsed_5" 9 "NotUsed_4" 8 "NotUsed_3" 7 "NotUsed_2" 6 "NotUsed_1" 5 "GoToTraileringDomain" 4 "Confirm" 3 "TurnOnTba" 2 "TurnOnAutohitch" 1 "CancelAutohitch" 0 "NoRequest" ;
VAL_ 533 DcacPwButtn_B_Stat 1 "Pressed" 0 "Not_Pressed" ;
VAL_ 801 CDWarnChime_St 1 "On" 0 "Off" ;
VAL_ 801 SoftWarning 1 "Chime_On" 0 "Chime_Off" ;
VAL_ 801 HardWarning 1 "Chime_On" 0 "Chime_Off" ;
VAL_ 801 InfoWarning 1 "Chime_On" 0 "Chime_Off" ;
VAL_ 801 DrvDsplyPalette_D_Stat 7 "NotUsed_3" 6 "NotUsed_2" 5 "ManualNightDark" 4 "ManualNightBright" 3 "ManualDay" 2 "AutoNight" 1 "AutoDay" 0 "Null" ;
VAL_ 878 ClimtSyncRear2_B_Stat 1 "Pressed" 0 "Not_Pressed" ;
VAL_ 878 ClimtStHeatRr2_B_Stat 1 "Pressed" 0 "Not_Pressed" ;
VAL_ 878 ClimtStHeatRl2_B_Stat 1 "Pressed" 0 "Not_Pressed" ;
VAL_ 878 ClimtStCoolRr2_B_Stat 1 "Pressed" 0 "Not_Pressed" ;
VAL_ 878 ClimtStCoolRl2_B_Stat 1 "Pressed" 0 "Not_Pressed" ;
VAL_ 878 ClimtSeatRr2_D_Rq 128 "H3_High_Heat_MAX" 64 "H2_Medium_Heat" 32 "H1_Low_Heat" 16 "C3_High_Cool_MAX" 8 "C2_Medium_Cool" 4 "C1_Low_Cool" 2 "Off" ;
VAL_ 878 ClimtSeatRl2_D_Rq 128 "H3_High_Heat_MAX" 64 "H2_Medium_Heat" 32 "H1_Low_Heat" 16 "C3_High_Cool_MAX" 8 "C2_Medium_Cool" 4 "C1_Low_Cool" 2 "Off" ;
VAL_ 878 ClimtRrTe3rd2_D_Stat 3 "NotUsed" 2 "Decrement" 1 "Increment" 0 "Inactive" ;
VAL_ 878 ClimtRrPw3rd2_B_Stat 1 "Pressed" 0 "Not_Pressed" ;
VAL_ 878 ClimtRrPnl3rd2_B_Stat 1 "Pressed" 0 "Not_Pressed" ;
VAL_ 878 ClimtRrPf3rd2_B_Stat 1 "Pressed" 0 "Not_Pressed" ;
VAL_ 878 ClimtRrFlr3rd2_B_Stat 1 "Pressed" 0 "Not_Pressed" ;
VAL_ 878 ClimtRrBlwr3rd2_D_Stat 3 "NotUsed" 2 "Decrement" 1 "Increment" 0 "Inactive" ;
VAL_ 878 ClimtRrAuto3rd2_B_Stat 1 "Pressed" 0 "Not_Pressed" ;
VAL_ 878 ClimtRearView2_D_Stat 3 "ThirdRow" 2 "SecondRow" 1 "Both" 0 "NotDisplayed" ;
VAL_ 878 ClimtRearTe2_D_Stat 3 "NotUsed" 2 "Decrement" 1 "Increment" 0 "Inactive" ;
VAL_ 878 ClimtRearTe2_An_Actl 511 "Faulty" ;
VAL_ 878 ClimtRearPw2_B_Stat 1 "Pressed" 0 "Not_Pressed" ;
VAL_ 878 ClimtRearPnlFlr2_B_Stat 1 "Pressed" 0 "Not_Pressed" ;
VAL_ 878 ClimtRearPnl2_B_Stat 1 "Pressed" 0 "Not_Pressed" ;
VAL_ 878 ClimtRearFlr2_B_Stat 1 "Pressed" 0 "Not_Pressed" ;
VAL_ 878 ClimtRearBlwr2_D_Stat 3 "NotUsed" 2 "Decrement" 1 "Increment" 0 "Inactive" ;
VAL_ 878 ClimtRearBlwr2_An_Actl 511 "Faulty" ;
VAL_ 878 ClimtRearAuto2_B_Stat 1 "Pressed" 0 "Not_Pressed" ;
VAL_ 258 GPS_Track_D_Rq 3 "NotUsed_1" 2 "NewGPSTrack" 1 "GPSTrackActive" 0 "Inactive" ;
VAL_ 258 APIM_SwPartNo_D_Rq 3 "NotUsed" 2 "Request" 1 "NoRequest" 0 "Inactive" ;
VAL_ 258 TCU_Init_Actvtn_Rq 3 "NotUsed" 2 "InitialActivateRequest" 1 "NoRequest" 0 "Inactive" ;
VAL_ 258 TCU_Final_Actvtn_Rq 3 "NotUsed" 2 "FinalActiveRequested" 1 "NoRequest" 0 "Inactive" ;
VAL_ 259 SDARS_ChipControl_Rq 7 "NotUsed_4" 6 "NotUsed_3" 5 "NotUsed_2" 4 "NotUsed_1" 3 "Reset" 2 "PowerDown" 1 "PowerUp" 0 "Inactive" ;
VAL_ 259 SDARS_AlertStatus_Rq 2 "Disable" 1 "Enable" 0 "Inactive" ;
VAL_ 538 MK_SpeedMinderConf_St 31 "mph90" 30 "mph85" 29 "mph80" 28 "mph75" 27 "mph70" 26 "mph65" 25 "mph60" 24 "mph55" 23 "mph50" 22 "mph45" 21 "mph40" 20 "Kmh165" 19 "Kmh160" 18 "Kmh155" 17 "Kmh150" 16 "Kmh145" 15 "Kmh140" 14 "Kmh135" 13 "Kmh130" 12 "Kmh125" 11 "Kmh120" 10 "Kmh115" 9 "Kmh110" 8 "Kmh105" 7 "Kmh100" 6 "kmh95" 5 "kmh90" 4 "kmh85" 3 "kmh80" 2 "kmh75" 1 "kmh70" 0 "Off" ;
VAL_ 538 MK_SpeedLimitConf_St 31 "mph90" 30 "mph85" 29 "mph80" 28 "mph75" 27 "mph70" 26 "mph65" 25 "mph60" 24 "mph55" 23 "mph50" 22 "mph45" 21 "mph40" 20 "Kmh165" 19 "Kmh160" 18 "Kmh155" 17 "Kmh150" 16 "Kmh145" 15 "Kmh140" 14 "Kmh135" 13 "Kmh130" 12 "Kmh125" 11 "Kmh120" 10 "Kmh115" 9 "Kmh110" 8 "Kmh105" 7 "Kmh100" 6 "kmh95" 5 "kmh90" 4 "kmh85" 3 "kmh80" 2 "kmh75" 1 "kmh70" 0 "Off" ;
VAL_ 538 MK_ESCRestrictConf_St 3 "NotUsed" 2 "On" 1 "Off" 0 "Null" ;
VAL_ 538 MK_ECalRestrictConf_St 3 "NotUsed" 2 "On" 1 "Off" 0 "Null" ;
VAL_ 538 MK_DNDRestrictConf_St 3 "NotUsed" 2 "On" 1 "Off" 0 "Null" ;
VAL_ 538 MK_AudioLimitConfig_St 3 "NotUsed" 2 "On" 1 "Off" 0 "Null" ;
VAL_ 422 MK_UserMyKeyCount_Rsp 15 "Inactive" 14 "Unlimited" 13 "Thirteen" 12 "Twelve" 11 "Eleven" 10 "Ten" 9 "Nine" 8 "Eight" 7 "Seven" 6 "Six" 5 "Five" 4 "Four" 3 "Three" 2 "Two" 1 "One" 0 "Zero" ;
VAL_ 422 MK_CreateMyKey_Rsp 7 "NotUsed_3" 6 "NotUsed_2" 5 "NotUsed_1" 4 "Success" 3 "GenericFailure" 2 "NoKeyInSlot" 1 "KeyInSlotAlreadyMyKey" 0 "Inactive" ;
VAL_ 422 MK_AdminMyKeyCount_Rsp 15 "Inactive" 14 "Unlimited" 13 "Thirteen" 12 "Twelve" 11 "Eleven" 10 "Ten" 9 "Nine" 8 "Eight" 7 "Seven" 6 "Six" 5 "Five" 4 "Four" 3 "Three" 2 "Two" 1 "One" 0 "Zero" ;
VAL_ 884 UltraFreshCabn_D_Stat 7 "NotUsed_2" 6 "NotUsed_1" 5 "NotSupported" 4 "Interrupted" 3 "Complete" 2 "Active" 1 "Inactive" 0 "Null" ;
VAL_ 884 PmSnsCabn_D_Stat 7 "NotUsed_1" 6 "IntermittentInhibit" 5 "NoIssue" 4 "BlankField" 3 "ReplaceSensor" 2 "CleanSensor" 1 "Unsupported" 0 "Initializing" ;
VAL_ 884 PmCabn_Conc_Actl 511 "Faulty" 510 "NoDataExists" ;
VAL_ 884 PmCabn20Mnte_Conc_Actl 511 "Faulty" 510 "NoDataExists" ;
VAL_ 884 PmCabn18Mnte_Conc_Actl 511 "Faulty" 510 "NoDataExists" ;
VAL_ 884 PmCabn16Mnte_Conc_Actl 511 "Faulty" 510 "NoDataExists" ;
VAL_ 884 PmCabn14Mnte_Conc_Actl 511 "Faulty" 510 "NoDataExists" ;
VAL_ 884 PmCabn12Mnte_Conc_Actl 511 "Faulty" 510 "NoDataExists" ;
VAL_ 883 PmCabn10Mnte_Conc_Actl 511 "Faulty" 510 "NoDataExists" ;
VAL_ 883 PmCabn08Mnte_Conc_Actl 511 "Faulty" 510 "NoDataExists" ;
VAL_ 883 PmCabn06Mnte_Conc_Actl 511 "Faulty" 510 "NoDataExists" ;
VAL_ 883 PmCabn04Mnte_Conc_Actl 511 "Faulty" 510 "NoDataExists" ;
VAL_ 883 PmCabn02Mnte_Conc_Actl 511 "Faulty" 510 "NoDataExists" ;
VAL_ 1090 VehElRnge_L_Dsply 4094 "NoDataExists" 4095 "Fault" ;
VAL_ 1090 Mtr2State_D_ActlMntr 7 "Faulty" 6 "NoDataExists" 5 "NotUsed_1" 4 "ReadinessState" 3 "DeactivationState" 2 "PowerGeneration" 1 "PowerConsumption" 0 "Null" ;
VAL_ 1090 Inv1Ain_I_ActlMntr 32767 "Faulty" 32766 "NoDataExists" ;
VAL_ 1090 HybVehMde_D_ActlMntr 7 "Faulty" 6 "NoDataExists" 5 "NotUsed_2" 4 "NotUsed_1" 3 "Fuel" 2 "HybridElectric" 1 "AllElectric" 0 "Null" ;
VAL_ 1090 ChrgStat_D_ActlMntr 7 "Faulty" 6 "NoDataExists" 5 "NotUsed" 4 "ChargingCompleted" 3 "NotCharging" 2 "ChargingInDrivingState" 1 "ChargingInParkingState" 0 "Null" ;
VAL_ 677 SeatFnPsgr_D_Rq3 7 "CushionMassage" 6 "LumbarMassage" 5 "UpperBolster" 4 "LowerBolster" 3 "UpperLumbar" 2 "MiddleLumbar" 1 "LowerLumbar" 0 "Null" ;
VAL_ 677 SeatFnDrv_D_Rq3 7 "CushionMassage" 6 "LumbarMassage" 5 "UpperBolster" 4 "LowerBolster" 3 "UpperLumbar" 2 "MiddleLumbar" 1 "LowerLumbar" 0 "Null" ;
VAL_ 677 SeatMasgPsngrRr_D_Rq2 15 "NotUsed_10" 14 "NotUsed_9" 13 "NotUsed_8" 12 "NotUsed_7" 11 "NotUsed_6" 10 "NotUsed_5" 9 "NotUsed_4" 8 "NotUsed_3" 7 "NotUsed_2" 6 "NotUsed_1" 5 "Pattern5" 4 "Pattern4" 3 "Pattern3" 2 "Pattern2" 1 "Pattern1" 0 "Null" ;
VAL_ 677 SeatMasgDrvRr_D_Rq2 15 "NotUsed_10" 14 "NotUsed_9" 13 "NotUsed_8" 12 "NotUsed_7" 11 "NotUsed_6" 10 "NotUsed_5" 9 "NotUsed_4" 8 "NotUsed_3" 7 "NotUsed_2" 6 "NotUsed_1" 5 "Pattern5" 4 "Pattern4" 3 "Pattern3" 2 "Pattern2" 1 "Pattern1" 0 "Null" ;
VAL_ 677 SeatFnChngPsgr2_D_Rq3 15 "Faulty" 14 "NotUsed9" 13 "NotUsed8" 12 "NotUsed7" 11 "NotUsed6" 10 "High_2" 9 "Med_2" 8 "Low_2" 7 "Off_2" 6 "High" 5 "Low" 4 "Off" 3 "Decrease" 2 "Increase" 1 "NotUsed1" 0 "Inactive" ;
VAL_ 677 SeatFnChngDrv2_D_Rq3 15 "Faulty" 14 "NotUsed9" 13 "NotUsed8" 12 "NotUsed7" 11 "NotUsed6" 10 "High_2" 9 "Med_2" 8 "Low_2" 7 "Off_2" 6 "High" 5 "Low" 4 "Off" 3 "Decrease" 2 "Increase" 1 "NotUsed1" 0 "Inactive" ;
VAL_ 1238 IaccVAdjReas_D_Dsply 15 "NotUsed_21" 11 "NotUsed_1" 10 "SpeedSign" 9 "LeftRamp" 8 "RightRamp" 7 "Roundabout_CCW" 6 "Roundabout_CW" 5 "LeftCurve" 4 "RightCurve" 3 "LeftTurnIntersection" 2 "RightTurnIntersection" 1 "RoadGeometryUnavailable" 0 "NoDisplay" ;
VAL_ 1041 ElCmprPerfErr_D_Falt 3 "NotUsed" 2 "Pass" 1 "Fail" 0 "Not_Diagnose_Yet" ;
VAL_ 1041 ElCmprInnrErr_D_Falt 3 "NotUsed" 2 "Pass" 1 "Fail" 0 "Not_Diagnose_Yet" ;
VAL_ 1041 ElCmprLostComm_D_Falt 3 "NotUsed" 2 "Pass" 1 "Fail" 0 "Not_Diagnose_Yet" ;
VAL_ 1041 ElCmprOverLoad_D_Falt 3 "NotUsed" 2 "Pass" 1 "Fail" 0 "Not_Diagnose_Yet" ;
VAL_ 1041 ElCmprOverTe_D_Falt 3 "NotUsed" 2 "Pass" 1 "Fail" 0 "Not_Diagnose_Yet" ;
VAL_ 1041 ElCmprBattURng_D_Falt 3 "NotUsed" 2 "Pass" 1 "Fail" 0 "Not_Diagnose_Yet" ;
VAL_ 1041 ElCmprBattSysU_D_Falt 3 "NotUsed" 2 "Pass" 1 "Fail" 0 "Not_Diagnose_Yet" ;
VAL_ 1041 ElCmprSysU_D_Falt 3 "NotUsed" 2 "Pass" 1 "Fail" 0 "Not_Diagnose_Yet" ;
VAL_ 1041 ElCmprUHi_D_Stat 3 "Overvoltage" 2 "Undervoltage" 1 "InRange" 0 "Undetermined" ;
VAL_ 1041 ElCmprOverTe_D_Stat 3 "OverTempStop" 2 "OverTempWarning" 1 "Normal" 0 "Undefined" ;
VAL_ 1041 ElCmpr_N_Actl 255 "Invalid" ;
VAL_ 1041 ElCmpr_Pw_Actl 255 "Invalid" ;
VAL_ 1041 ElCmpr_D_Stat 7 "Signal_Invalid" 6 "Comp_Off_ActlSpd_Abnormal" 5 "Comp_Off_TrgtSpd_OutRange" 4 "Comp_Shutdown" 3 "Comp_Stopped_Self_Protect" 2 "Comp_Degraded" 1 "Comp_On" 0 "Comp_Off" ;
VAL_ 557 AudioToneTouchY_D_Stat 255 "Value254" 2 "Value1_up_to_0xFE_Value253" 1 "Value0" 0 "Null" ;
VAL_ 557 AudioToneTouchX_D_Stat 255 "Value254" 2 "Value1_up_to_0xFE_Value253" 1 "Value0" 0 "Null" ;
VAL_ 557 AudioToneTouch_D_Stat 3 "NotUsed" 2 "Enabled" 1 "Disabled" 0 "Null" ;
VAL_ 1236 ApaSlotRight3_D_Stat 7 "NotUsed_3" 6 "NotUsed_2" 5 "NotUsed_1" 4 "IPeReady" 3 "IPeFound" 2 "IPaReady" 1 "IPaFound" 0 "None" ;
VAL_ 1236 ApaSlotRight3_B_Altr 1 "Available" 0 "NotAvailable" ;
VAL_ 1236 ApaSlotRight2_D_Stat 7 "NotUsed_3" 6 "NotUsed_2" 5 "NotUsed_1" 4 "IPeReady" 3 "IPeFound" 2 "IPaReady" 1 "IPaFound" 0 "None" ;
VAL_ 1236 ApaSlotRight2_B_Altr 1 "Available" 0 "NotAvailable" ;
VAL_ 1236 ApaSlotRight1_D_Stat 7 "NotUsed_3" 6 "NotUsed_2" 5 "NotUsed_1" 4 "IPeReady" 3 "IPeFound" 2 "IPaReady" 1 "IPaFound" 0 "None" ;
VAL_ 1236 ApaSlotRight1_B_Altr 1 "Available" 0 "NotAvailable" ;
VAL_ 1236 ApaSlotRear_D_Stat 1 "True" 0 "False" ;
VAL_ 1235 ApaSlotFront_D_Stat 1 "True" 0 "False" ;
VAL_ 1235 ApaSlotLeft3_D_Stat 7 "NotUsed_3" 6 "NotUsed_2" 5 "NotUsed_1" 4 "IPeReady" 3 "IPeFound" 2 "IPaReady" 1 "IPaFound" 0 "None" ;
VAL_ 1235 ApaSlotLeft3_B_Altr 1 "Available" 0 "NotAvailable" ;
VAL_ 1235 ApaSlotLeft2_D_Stat 7 "NotUsed_3" 6 "NotUsed_2" 5 "NotUsed_1" 4 "IPeReady" 3 "IPeFound" 2 "IPaReady" 1 "IPaFound" 0 "None" ;
VAL_ 1235 ApaSlotLeft2_B_Altr 1 "Unavailable" 0 "Available" ;
VAL_ 1235 ApaSlotLeft1_D_Stat 7 "NotUsed_3" 6 "NotUsed_2" 5 "NotUsed_1" 4 "IPeReady" 3 "IPeFound" 2 "IPaReady" 1 "IPaFound" 0 "None" ;
VAL_ 1235 ApaSlotLeft1_B_Altr 1 "Unavailable" 0 "Available" ;
VAL_ 1234 RmtCtlSnsBlckg_B_Stat 1 "Yes" 0 "No" ;
VAL_ 1234 RmtCtlConfgSrc_D_Stat 7 "NotUsed_2" 6 "NotUsed_1" 5 "BPO" 4 "ApaHmi" 3 "FAP_Handover" 2 "User" 1 "None" 0 "NotDetermined" ;
VAL_ 1234 RmtCtlTrjctry_D_Avail 1 "Available" 0 "NotAvailable" ;
VAL_ 1234 RmtCtlSns_D_Err 1 "Yes" 0 "No" ;
VAL_ 1234 RmtCtlPathPlan_D_Stat 7 "NotUsed_3" 6 "NotUsed_2" 5 "NotUsed_1" 4 "FinishedMovesExceeded" 3 "FinishedDistanceExceeded" 2 "Finished" 1 "Ongoing" 0 "None" ;
VAL_ 1234 RmtCtlPathPlan_B_Err 1 "Yes" 0 "No" ;
VAL_ 1234 RmtCtlAdas_D_Stat 7 "Paused" 6 "Abort" 5 "ManeuverFinished" 4 "EndPositionReached" 3 "Backward" 2 "Forward" 1 "ManeuverBegin" 0 "Inactive" ;
VAL_ 1234 RmtCtlAdas_B_Err 1 "Yes" 0 "No" ;
VAL_ 976 VehLong2_A_Actl_UB 1 "Fresh_data" 0 "Unchanged_data" ;
VAL_ 976 VehLong2_A_Actl 8191 "Faulty" 8190 "NoDataExists" ;
VAL_ 925 TripSumDrvE_Pc_Dsply 1023 "Faulty" 1022 "NoDataExists" ;
VAL_ 925 TripExtFctrE_Pc_Dsply 1023 "Faulty" 1022 "NoDataExists" ;
VAL_ 925 TripClimE_Pc_Dsply 1023 "Faulty" 1022 "NoDataExists" ;
VAL_ 925 TripBattULoE_Pc_Dsply 1023 "Faulty" 1022 "NoDataExists" ;
VAL_ 473 NAV_StorePreset2_Rq 31 "Reserved" 30 "Preset30" 29 "Preset29" 28 "Preset28" 27 "Preset27" 26 "Preset26" 25 "Preset25" 24 "Preset24" 23 "Preset23" 22 "Preset22" 21 "Preset21" 20 "Preset20" 19 "Preset19" 18 "Preset18" 17 "Preset17" 16 "Preset16" 15 "Preset15" 14 "Preset14" 13 "Preset13" 12 "Preset12" 11 "Preset11" 10 "Preset10" 9 "Preset9" 8 "Preset8" 7 "Preset7" 6 "Preset6" 5 "Preset5" 4 "Preset4" 3 "Preset3" 2 "Preset2" 1 "Preset1" 0 "Inactive" ;
VAL_ 473 NAV_SetAFMode_Rq 0 "Inactive" 1 "AfOn" 2 "AfOff" 3 "Auto" ;
VAL_ 473 NAV_StorePreset_Rq 10 "Preset10" 9 "Preset9" 8 "Preset8" 7 "Preset7" 0 "Inactive" 1 "Preset1" 2 "Preset2" 3 "Preset3" 4 "Preset4" 5 "Preset5" 6 "Preset6" ;
VAL_ 473 HMI_StorePreset2_Rq 31 "Reserved" 30 "Preset30" 29 "Preset29" 28 "Preset28" 27 "Preset27" 26 "Preset26" 25 "Preset25" 24 "Preset24" 23 "Preset23" 22 "Preset22" 21 "Preset21" 20 "Preset20" 19 "Preset19" 18 "Preset18" 17 "Preset17" 16 "Preset16" 15 "Preset15" 14 "Preset14" 13 "Preset13" 12 "Preset12" 11 "Preset11" 10 "Preset10" 9 "Preset9" 8 "Preset8" 7 "Preset7" 6 "Preset6" 5 "Preset5" 4 "Preset4" 3 "Preset3" 2 "Preset2" 1 "Preset1" 0 "Inactive" ;
VAL_ 473 NAV_SetTUServiceLink_Rq 3 "reserved" 2 "Inactive" 1 "Active" 0 "Invalid" ;
VAL_ 473 NAV_SetTAMode_Rq 0 "Inactive" 1 "TaLocalOn" 2 "TaDistantOn" 3 "TaOff" ;
VAL_ 473 NAV_SetReg_Rq 2 "On" 1 "Off" 0 "Inactive" ;
VAL_ 473 NAV_SelectPTYCodeSet_Rq 0 "Inactive" 1 "SetCode" ;
VAL_ 473 NAV_CDSetShuffle_Rq 0 "Inactive" 1 "On" 2 "Off" 3 "OnFolder" ;
VAL_ 473 NAV_CDSetRepeat_Rq 0 "Inactive" 1 "RepeatOnTrack" 2 "Off" 3 "OnFolder" ;
VAL_ 473 NAV_CDSetIntroScan_Rq 0 "Inactive" 1 "On" 2 "Off" 3 "OnFolder" ;
VAL_ 810 ExtLghtDsply_B_StatArb 1 "On" 0 "Off" ;
VAL_ 810 OneTEditActv_B_RqCld 1 "Yes" 0 "No" ;
VAL_ 482 SDARS_Firm_Update2_St 0 "Invalid" 2 "Active" 1 "Inactive" ;
VAL_ 482 SDARS_UnSubscrb_Chan2_St 0 "Invalid" 2 "Active" 1 "Inactive" ;
VAL_ 482 SDARS_UnSubscrb2_St 0 "Invalid" 2 "Active" 1 "Inactive" ;
VAL_ 482 SDARS_Subscription2_St 0 "Invalid" 2 "Active" 1 "Inactive" ;
VAL_ 482 SDARS_Seek_Scan2_St 1 "NoChannelsAvailable" 0 "Invalid" ;
VAL_ 482 SDARS_Receive_Err2_St 0 "Invalid" 2 "Active" 1 "Inactive" ;
VAL_ 482 SDARS_Loss_Ant2_St 0 "Invalid" 2 "Active" 1 "Inactive" ;
VAL_ 482 SDARS_Invalid_Chan2_St 0 "Invalid" 2 "Active" 1 "Inactive" ;
VAL_ 482 SDARS_GCI_Update2_St 0 "Invalid" 2 "Active" 1 "Inactive" ;
VAL_ 482 SDARS_Error_Conf2_St 0 "Invalid" 2 "SDARS_OFF" 1 "SDARS_ON" ;
VAL_ 482 SDARS_Antenna_Err2_St 0 "Invalid" 2 "Active" 1 "Inactive" ;
VAL_ 764 SdarsSampleRate_D_Stat 3 "NotUsed_1" 2 "SampleRate_48000Hz" 1 "SampleRate_44100Hz" 0 "Null" ;
VAL_ 764 SdarsBaudRate_D_Stat 7 "NotUsed_3" 6 "NotUsed_2" 5 "NotUsed_1" 4 "BaudRate_460800bps" 3 "BaudRate_230400bps" 2 "BaudRate_115200bps" 1 "BaudRate_57600bps" 0 "Null" ;
VAL_ 764 SDARS_ChannelUpdate_St 3 "NotUsed_1" 2 "NewUpdatesAvailable" 1 "NoUpdates" 0 "Inactive" ;
VAL_ 764 SDARS_Channel_Lock2 0 "Invalid" 2 "Unlocked" 1 "Locked" ;
